VERSION ""

NS_ :

BS_:

BU_: AHCP APM BPCM EAC EBCM ECM ESC HCP OBCM ORC RHSC2

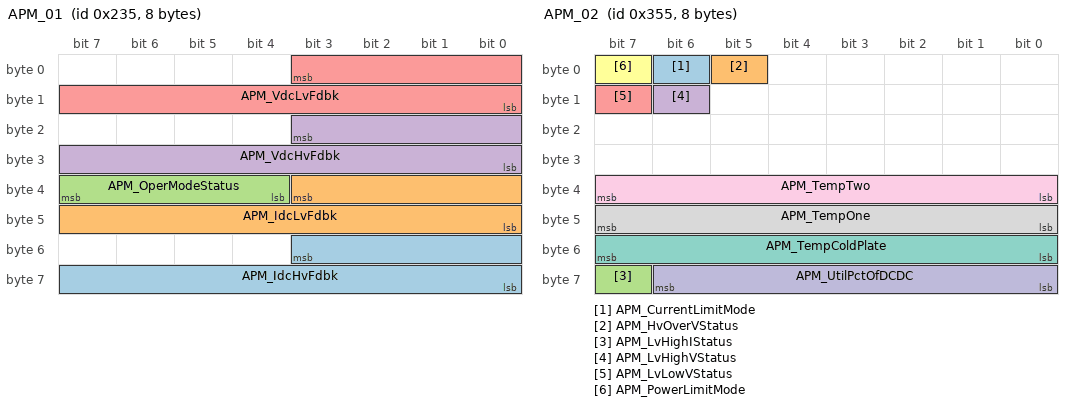
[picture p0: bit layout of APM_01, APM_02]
BO_ 565 APM_01: 8 APM
 SG_ APM_IdcHvFdbk : 51|12@0+ (0.1,-149) [-149|150] "Amp"  HCP
 SG_ APM_IdcLvFdbk : 35|12@0+ (0.15,-299) [-299|299.5] "Amp"  HCP
 SG_ APM_OperModeStatus : 36|4@1+ (1,0) [0|0] ""  HCP
 SG_ APM_VdcHvFdbk : 19|12@0+ (0.125,0) [0|510] "V"  HCP
 SG_ APM_VdcLvFdbk : 3|12@0+ (0.005,0) [0|19.9999] "V"  HCP

BO_ 853 APM_02: 8 APM
 SG_ APM_CurrentLimitMode : 6|1@1+ (1,0) [0|0] ""  HCP
 SG_ APM_HvOverVStatus : 5|1@1+ (1,0) [0|0] ""  HCP
 SG_ APM_LvHighIStatus : 63|1@1+ (1,0) [0|0] ""  HCP
 SG_ APM_LvHighVStatus : 14|1@1+ (1,0) [0|0] ""  HCP
 SG_ APM_LvLowVStatus : 15|1@1+ (1,0) [0|0] ""  HCP
 SG_ APM_PowerLimitMode : 7|1@1+ (1,0) [0|0] ""  HCP
 SG_ APM_TempColdPlate : 48|8@1+ (1,-40) [-40|213] "°C"  HCP
 SG_ APM_TempOne : 40|8@1+ (1,-40) [-40|213] "°C"  HCP
 SG_ APM_TempTwo : 32|8@1+ (1,-40) [-40|213] "°C"  HCP
 SG_ APM_UtilPctOfDCDC : 56|7@1+ (1,0) [0|126] "%"  HCP

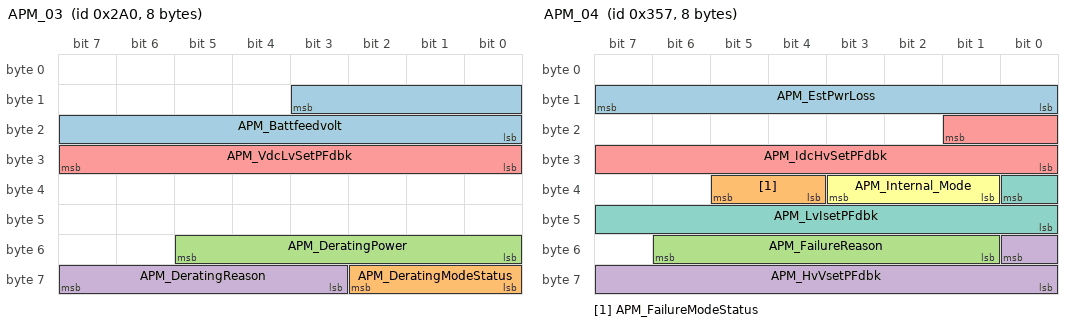
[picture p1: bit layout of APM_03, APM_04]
BO_ 672 APM_03: 8 APM
 SG_ APM_Battfeedvolt : 11|12@0+ (0.0097703,0) [0|40] "V"  HCP
 SG_ APM_DeratingModeStatus : 56|3@1+ (1,0) [0|0] ""  HCP
 SG_ APM_DeratingPower : 48|6@1+ (50,0) [0|3100] "W"  HCP
 SG_ APM_DeratingReason : 59|5@1+ (1,0) [0|0] ""  HCP
 SG_ APM_VdcLvSetPFdbk : 24|8@1+ (0.0625,0) [0|15.875] "V"  HCP

BO_ 855 APM_04: 8 APM
 SG_ APM_EstPwrLoss : 8|8@1+ (2,0) [0|504] "W"  HCP
 SG_ APM_FailureModeStatus : 36|2@1+ (1,0) [0|0] ""  HCP
 SG_ APM_FailureReason : 49|6@1+ (1,0) [0|0] ""  HCP
 SG_ APM_HvVsetPFdbk : 48|9@0+ (1,0) [0|510] "V"  HCP
 SG_ APM_IdcHvSetPFdbk : 17|10@0+ (0.2,-100) [-100|104.4] "Amp"  HCP
 SG_ APM_Internal_Mode : 33|3@1+ (1,0) [0|0] ""  HCP
 SG_ APM_LvIsetPFdbk : 32|9@0+ (1,-255) [-255|255] "Amp"  HCP

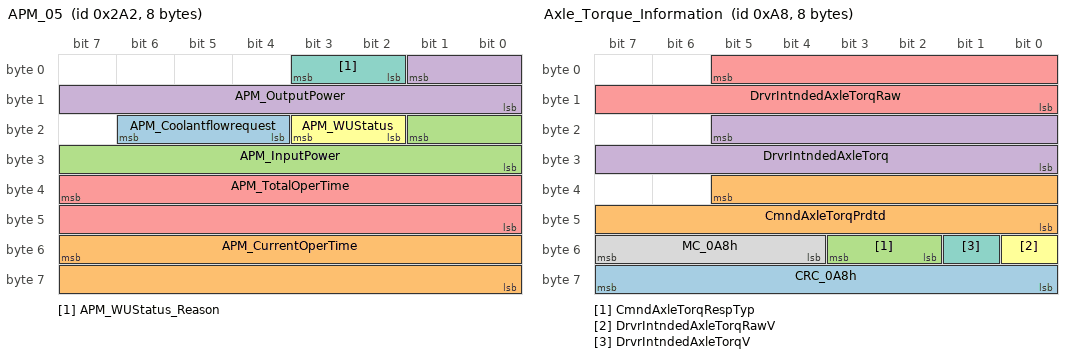
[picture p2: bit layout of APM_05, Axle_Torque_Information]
BO_ 674 APM_05: 8 APM
 SG_ APM_Coolantflowrequest : 20|3@1+ (1,0) [0|7] ""  HCP
 SG_ APM_CurrentOperTime : 55|16@0+ (1,0) [0|65534] "sec"  HCP
 SG_ APM_InputPower : 17|10@0+ (3,0) [0|3066] "W"  HCP
 SG_ APM_OutputPower : 1|10@0+ (3,0) [0|3066] "W"  HCP
 SG_ APM_TotalOperTime : 39|16@0+ (1,0) [0|65534] "Hours"  HCP
 SG_ APM_WUStatus : 18|2@1+ (1,0) [0|0] ""  HCP
 SG_ APM_WUStatus_Reason : 2|2@1+ (1,0) [0|0] ""  HCP

BO_ 168 Axle_Torque_Information: 8 ECM
 SG_ CRC_0A8h : 56|8@1+ (1,0) [0|0] ""  HCP
 SG_ CmndAxleTorqPrdtd : 37|14@0+ (1.5625,-4604.688) [-4604.688|20970.3125] "Nm"  HCP
 SG_ CmndAxleTorqRespTyp : 50|2@1+ (1,0) [0|0] ""  HCP
 SG_ DrvrIntndedAxleTorq : 21|14@0+ (1.5625,-4604.688) [-4604.688|20970.3125] "Nm"  HCP
 SG_ DrvrIntndedAxleTorqRaw : 5|14@0+ (1.5625,-4604.688) [-4604.688|20970.3125] "Nm"  HCP
 SG_ DrvrIntndedAxleTorqRawV : 48|1@1+ (1,0) [0|0] ""  HCP
 SG_ DrvrIntndedAxleTorqV : 49|1@1+ (1,0) [0|0] ""  HCP
 SG_ MC_0A8h : 52|4@1+ (1,0) [0|15] ""  HCP

BO_ 708 BPCM_HV_CellBalancing: 8 BPCM
 SG_ HVBatBalComplete : 56|1@1+ (1,0) [0|0] ""  HCP
 SG_ HVBatBalMd : 58|1@1+ (1,0) [0|0] ""  HCP

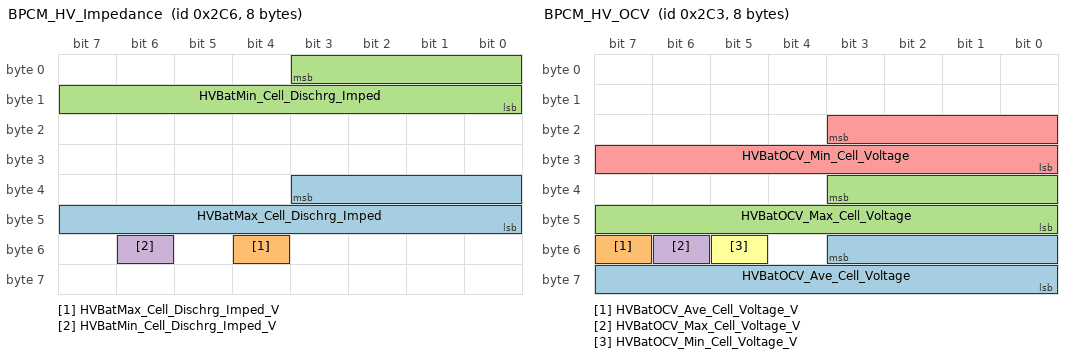
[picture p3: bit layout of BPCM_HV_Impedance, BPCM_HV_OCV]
BO_ 710 BPCM_HV_Impedance: 8 BPCM
 SG_ HVBatMax_Cell_Dischrg_Imped : 35|12@0+ (0.01,0) [0|40.9] "Ohms"  HCP
 SG_ HVBatMax_Cell_Dischrg_Imped_V : 52|1@1+ (1,0) [0|0] ""  HCP
 SG_ HVBatMin_Cell_Dischrg_Imped : 3|12@0+ (0.01,0) [0|40.9] "Ohms"  HCP
 SG_ HVBatMin_Cell_Dischrg_Imped_V : 54|1@1+ (1,0) [0|0] ""  HCP

BO_ 707 BPCM_HV_OCV: 8 BPCM
 SG_ HVBatOCV_Ave_Cell_Voltage : 51|12@0+ (0.001,1.5) [1.5|4.5] "Volts"  HCP
 SG_ HVBatOCV_Ave_Cell_Voltage_V : 55|1@1+ (1,0) [0|0] ""  HCP
 SG_ HVBatOCV_Max_Cell_Voltage : 35|12@0+ (0.001,1.5) [1.5|4.5] "Volts"  HCP
 SG_ HVBatOCV_Max_Cell_Voltage_V : 54|1@1+ (1,0) [0|0] ""  HCP
 SG_ HVBatOCV_Min_Cell_Voltage : 19|12@0+ (0.001,1.5) [1.5|4.5] "Volts"  HCP
 SG_ HVBatOCV_Min_Cell_Voltage_V : 53|1@1+ (1,0) [0|0] ""  HCP

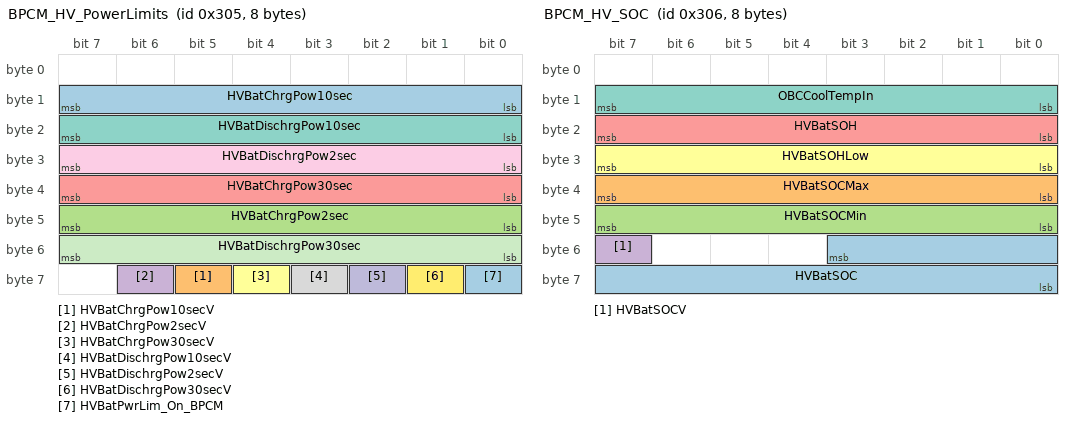
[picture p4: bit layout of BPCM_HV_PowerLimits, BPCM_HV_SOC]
BO_ 773 BPCM_HV_PowerLimits: 8 BPCM
 SG_ HVBatChrgPow10sec : 8|8@1+ (0.5,0) [0|125] "kW"  ECM,HCP
 SG_ HVBatChrgPow10secV : 61|1@1+ (1,0) [0|0] ""  ECM,HCP
 SG_ HVBatChrgPow2sec : 40|8@1+ (0.5,0) [0|125] "kW"  ECM,HCP
 SG_ HVBatChrgPow2secV : 62|1@1+ (1,0) [0|0] ""  ECM,HCP
 SG_ HVBatChrgPow30sec : 32|8@1+ (0.5,0) [0|125] "kW"  ECM,HCP
 SG_ HVBatChrgPow30secV : 60|1@1+ (1,0) [0|0] ""  ECM,HCP
 SG_ HVBatDischrgPow10sec : 16|8@1+ (0.5,0) [0|125] "kW"  HCP
 SG_ HVBatDischrgPow10secV : 59|1@1+ (1,0) [0|0] ""  HCP
 SG_ HVBatDischrgPow2sec : 24|8@1+ (0.5,0) [0|125] "kW"  HCP
 SG_ HVBatDischrgPow2secV : 58|1@1+ (1,0) [0|0] ""  HCP
 SG_ HVBatDischrgPow30sec : 48|8@1+ (0.5,0) [0|125] "kW"  HCP
 SG_ HVBatDischrgPow30secV : 57|1@1+ (1,0) [0|0] ""  HCP
 SG_ HVBatPwrLim_On_BPCM : 56|1@1+ (1,0) [0|0] ""  HCP

BO_ 774 BPCM_HV_SOC: 8 BPCM
 SG_ HVBatSOC : 51|12@0+ (0.02442,0) [0|100] "%"  EBCM,ESC,HCP
 SG_ HVBatSOCMax : 32|8@1+ (0.392157,0) [0|100] "%"  HCP
 SG_ HVBatSOCMin : 40|8@1+ (0.392157,0) [0|100] "%"  HCP
 SG_ HVBatSOCV : 55|1@1+ (1,0) [0|0] ""  HCP
 SG_ HVBatSOH : 16|8@1+ (0.2,50) [50|100] "%"  HCP
 SG_ HVBatSOHLow : 24|8@1+ (0.2,50) [50|100] "%"  HCP
 SG_ OBCCoolTempIn : 8|8@1+ (1,-40) [-40|214] "°C"  HCP

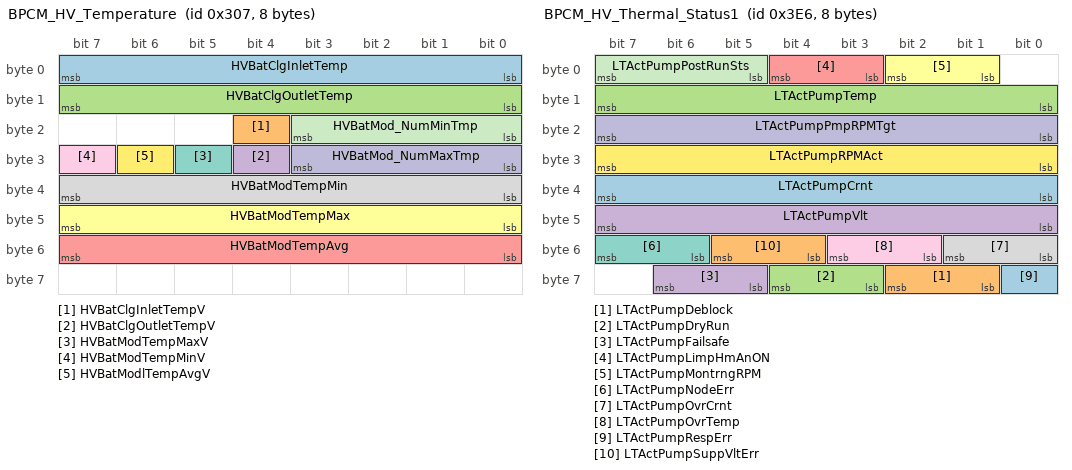
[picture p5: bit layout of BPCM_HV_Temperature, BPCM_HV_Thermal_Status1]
BO_ 775 BPCM_HV_Temperature: 8 BPCM
 SG_ HVBatClgInletTemp : 0|8@1+ (1,-40) [-40|214] "°C"  ECM,HCP
 SG_ HVBatClgInletTempV : 20|1@1+ (1,0) [0|0] ""  ECM,HCP
 SG_ HVBatClgOutletTemp : 8|8@1+ (1,-40) [-40|214] "°C"  ECM,HCP
 SG_ HVBatClgOutletTempV : 28|1@1+ (1,0) [0|0] ""  ECM,HCP
 SG_ HVBatModTempAvg : 48|8@1+ (1,-40) [-40|214] "°C"  HCP
 SG_ HVBatModTempMax : 40|8@1+ (1,-40) [-40|214] "°C"  HCP,RHSC2
 SG_ HVBatModTempMaxV : 29|1@1+ (1,0) [0|0] ""  HCP,RHSC2
 SG_ HVBatModTempMin : 32|8@1+ (1,-40) [-40|214] "°C"  HCP,RHSC2
 SG_ HVBatModTempMinV : 31|1@1+ (1,0) [0|0] ""  HCP,RHSC2
 SG_ HVBatMod_NumMaxTmp : 24|4@1+ (1,0) [0|15] ""  HCP
 SG_ HVBatMod_NumMinTmp : 16|4@1+ (1,0) [0|15] ""  HCP
 SG_ HVBatModlTempAvgV : 30|1@1+ (1,0) [0|0] ""  HCP

BO_ 998 BPCM_HV_Thermal_Status1: 8 BPCM
 SG_ LTActPumpCrnt : 32|8@1+ (0.2,0) [0|50.8] "Amp"  HCP
 SG_ LTActPumpDeblock : 57|2@1+ (1,0) [0|0] ""  HCP
 SG_ LTActPumpDryRun : 59|2@1+ (1,0) [0|0] ""  HCP
 SG_ LTActPumpFailsafe : 61|2@1+ (1,0) [0|0] ""  HCP
 SG_ LTActPumpLimpHmAnON : 3|2@1+ (1,0) [0|0] ""  HCP
 SG_ LTActPumpMontrngRPM : 1|2@1+ (1,0) [0|0] ""  ECM,HCP
 SG_ LTActPumpNodeErr : 54|2@1+ (1,0) [0|0] ""  HCP
 SG_ LTActPumpOvrCrnt : 48|2@1+ (1,0) [0|0] ""  HCP
 SG_ LTActPumpOvrTemp : 50|2@1+ (1,0) [0|0] ""  HCP
 SG_ LTActPumpPmpRPMTgt : 16|8@1+ (28,0) [0|7000] "rpm"  HCP
 SG_ LTActPumpPostRunSts : 5|3@1+ (1,0) [0|0] ""  HCP
 SG_ LTActPumpRPMAct : 24|8@1+ (28,0) [0|7000] "rpm"  ECM,HCP
 SG_ LTActPumpRespErr : 56|1@1+ (1,0) [0|0] ""  HCP
 SG_ LTActPumpSuppVltErr : 52|2@1+ (1,0) [0|0] ""  HCP
 SG_ LTActPumpTemp : 8|8@1+ (1,-50) [-50|204] "°C"  HCP
 SG_ LTActPumpVlt : 40|8@1+ (0.12,0) [0|30] "Volts"  HCP

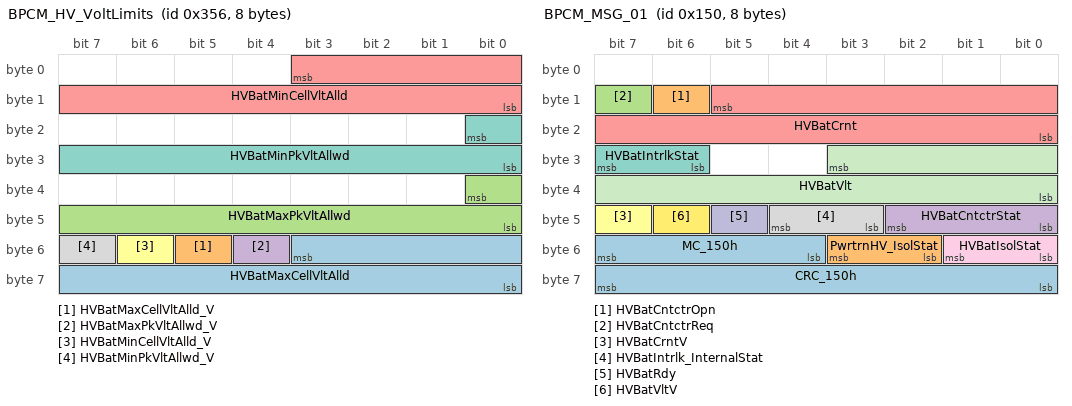
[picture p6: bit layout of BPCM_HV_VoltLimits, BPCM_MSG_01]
BO_ 854 BPCM_HV_VoltLimits: 8 BPCM
 SG_ HVBatMaxCellVltAlld : 51|12@0+ (0.001,1.5) [1.5|4.5] "Volts"  HCP
 SG_ HVBatMaxCellVltAlld_V : 53|1@1+ (1,0) [0|0] ""  HCP
 SG_ HVBatMaxPkVltAllwd : 32|9@0+ (1,175) [175|440] "V"  HCP
 SG_ HVBatMaxPkVltAllwd_V : 52|1@1+ (1,0) [0|0] ""  HCP
 SG_ HVBatMinCellVltAlld : 3|12@0+ (0.001,1.5) [1.5|4.5] "Volts"  HCP
 SG_ HVBatMinCellVltAlld_V : 54|1@1+ (1,0) [0|0] ""  HCP
 SG_ HVBatMinPkVltAllwd : 16|9@0+ (1,175) [175|440] "V"  HCP
 SG_ HVBatMinPkVltAllwd_V : 55|1@1+ (1,0) [0|0] ""  HCP

BO_ 336 BPCM_MSG_01: 8 BPCM
 SG_ CRC_150h : 56|8@1+ (1,0) [0|255] ""  HCP,OBCM
 SG_ HVBatCntctrOpn : 14|1@1+ (1,0) [0|0] ""  APM,HCP,OBCM
 SG_ HVBatCntctrReq : 15|1@1+ (1,0) [0|0] ""  HCP
 SG_ HVBatCntctrStat : 40|3@1+ (1,0) [0|0] ""  APM,HCP,OBCM,ORC
 SG_ HVBatCrnt : 13|14@0+ (0.1,-512.1) [-512|512] "Amp"  HCP
 SG_ HVBatCrntV : 47|1@1+ (1,0) [0|0] ""  HCP
 SG_ HVBatIntrlkStat : 30|2@1+ (1,0) [0|0] ""  HCP
 SG_ HVBatIntrlk_InternalStat : 43|2@1+ (1,0) [0|0] ""  HCP
 SG_ HVBatIsolStat : 48|2@1+ (1,0) [0|0] ""  HCP
 SG_ HVBatRdy : 45|1@1+ (1,0) [0|0] ""  HCP
 SG_ HVBatVlt : 27|12@0+ (0.1,180) [180|511] "Volts"  APM,HCP
 SG_ HVBatVltV : 46|1@1+ (1,0) [0|0] ""  APM,HCP
 SG_ MC_150h : 52|4@1+ (1,0) [0|15] ""  HCP,OBCM
 SG_ PwrtrnHV_IsolStat : 50|2@1+ (1,0) [0|0] ""  HCP

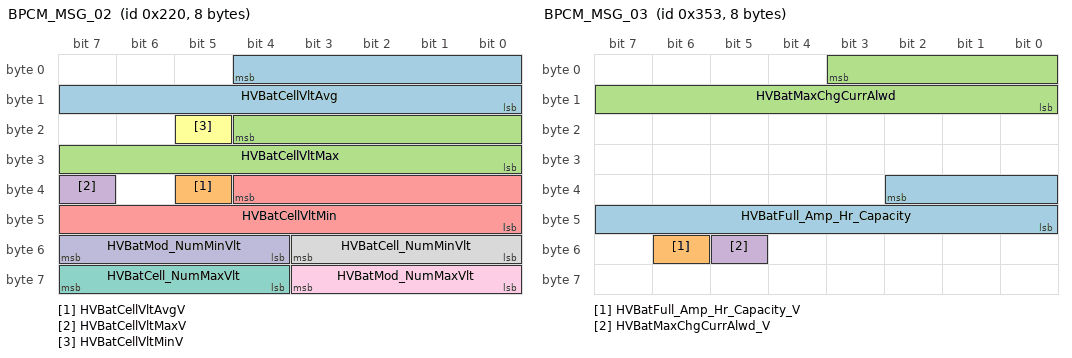
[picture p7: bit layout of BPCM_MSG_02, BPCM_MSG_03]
BO_ 544 BPCM_MSG_02: 8 BPCM
 SG_ HVBatCellVltAvg : 4|13@0+ (0.001,0) [0|5] "Volts"  HCP
 SG_ HVBatCellVltAvgV : 37|1@1+ (1,0) [0|0] ""  HCP
 SG_ HVBatCellVltMax : 20|13@0+ (0.001,0) [0|5] "Volts"  HCP
 SG_ HVBatCellVltMaxV : 39|1@1+ (1,0) [0|0] ""  HCP
 SG_ HVBatCellVltMin : 36|13@0+ (0.001,0) [0|5] "Volts"  HCP
 SG_ HVBatCellVltMinV : 21|1@1+ (1,0) [0|0] ""  HCP
 SG_ HVBatCell_NumMaxVlt : 60|4@1+ (1,0) [0|15] "Volts"  HCP
 SG_ HVBatCell_NumMinVlt : 48|4@1+ (1,0) [0|15] "Volts"  HCP
 SG_ HVBatMod_NumMaxVlt : 56|4@1+ (1,0) [0|15] ""  HCP
 SG_ HVBatMod_NumMinVlt : 52|4@1+ (1,0) [0|15] ""  HCP

BO_ 851 BPCM_MSG_03: 8 BPCM
 SG_ HVBatFull_Amp_Hr_Capacity : 34|11@0+ (0.1,0) [0|200] "Ah"  HCP
 SG_ HVBatFull_Amp_Hr_Capacity_V : 54|1@1+ (1,0) [0|0] ""  HCP
 SG_ HVBatMaxChgCurrAlwd : 3|12@0+ (0.1,0) [0|256] "A"  HCP
 SG_ HVBatMaxChgCurrAlwd_V : 53|1@1+ (1,0) [0|0] ""  HCP

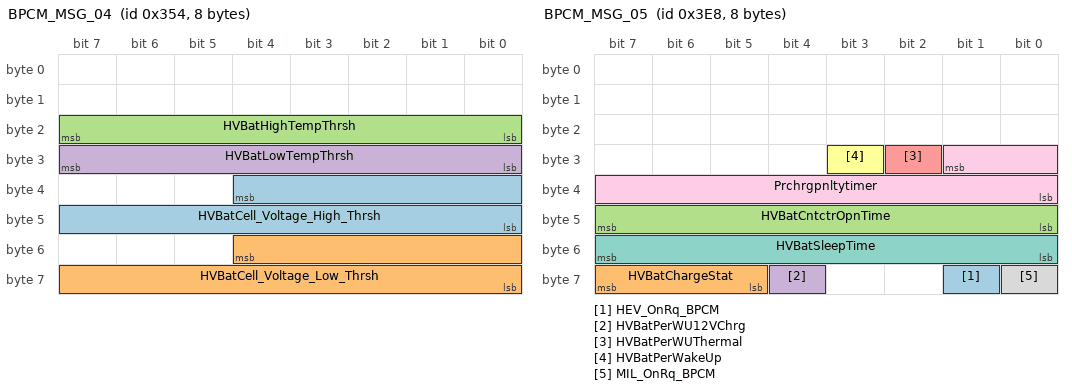
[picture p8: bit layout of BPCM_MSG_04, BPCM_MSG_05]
BO_ 852 BPCM_MSG_04: 8 BPCM
 SG_ HVBatCell_Voltage_High_Thrsh : 36|13@0+ (0.001,0) [0|5] "Volts"  HCP
 SG_ HVBatCell_Voltage_Low_Thrsh : 52|13@0+ (0.001,0) [0|5] "Volts"  HCP
 SG_ HVBatHighTempThrsh : 16|8@1+ (1,-40) [-40|214] "°C"  HCP,RHSC2
 SG_ HVBatLowTempThrsh : 24|8@1+ (1,-40) [-40|214] "°C"  HCP,RHSC2

BO_ 1000 BPCM_MSG_05: 8 BPCM
 SG_ HEV_OnRq_BPCM : 57|1@1+ (1,0) [0|0] ""  HCP
 SG_ HVBatChargeStat : 61|3@1+ (1,0) [0|0] ""  HCP
 SG_ HVBatCntctrOpnTime : 40|8@1+ (0.2,0) [0|48] "Hours"  HCP
 SG_ HVBatPerWU12VChrg : 60|1@1+ (1,0) [0|0] ""  HCP
 SG_ HVBatPerWUThermal : 26|1@1+ (1,0) [0|0] ""  HCP
 SG_ HVBatPerWakeUp : 27|1@1+ (1,0) [0|0] ""  HCP
 SG_ HVBatSleepTime : 48|8@1+ (0.2,0) [0|48] "Days"  HCP
 SG_ MIL_OnRq_BPCM : 56|1@1+ (1,0) [0|0] ""  ECM
 SG_ Prchrgpnltytimer : 25|10@0+ (2,0) [2|1800] "sec"  HCP

BO_ 337 BPCM_PHEV_2: 8 BPCM
 SG_ HVBat_Real_Time_Clock : 7|32@0+ (1,0) [0|4294967294] "sec"  ECM,HCP
 SG_ HVBat_Real_Time_Clock_V : 39|1@1+ (1,0) [0|0] ""  ECM,HCP

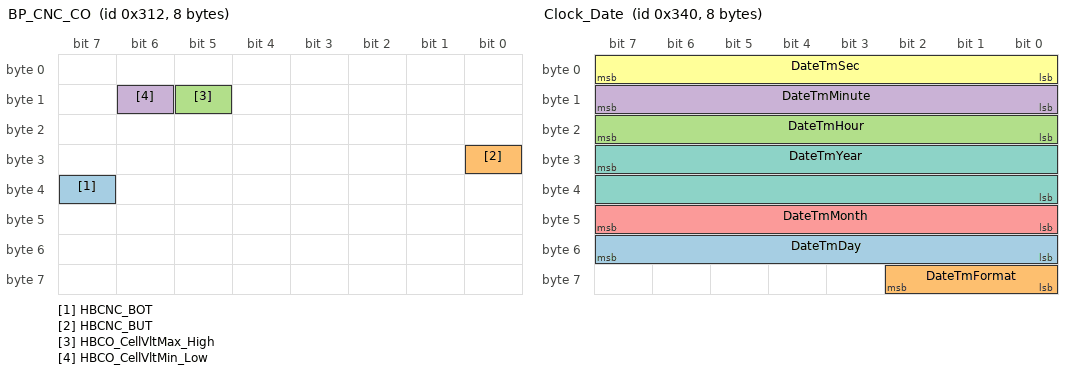
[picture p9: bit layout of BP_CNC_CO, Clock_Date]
BO_ 786 BP_CNC_CO: 8 BPCM
 SG_ HBCNC_BOT : 39|1@1+ (1,0) [0|0] ""  HCP
 SG_ HBCNC_BUT : 24|1@1+ (1,0) [0|0] ""  HCP
 SG_ HBCO_CellVltMax_High : 13|1@1+ (1,0) [0|0] ""  HCP
 SG_ HBCO_CellVltMin_Low : 14|1@1+ (1,0) [0|0] ""  HCP

BO_ 832 Clock_Date: 8 HCP
 SG_ DateTmDay : 48|8@1+ (1,0) [1|31] "Days"  BPCM
 SG_ DateTmFormat : 56|3@1+ (1,0) [0|0] ""  BPCM
 SG_ DateTmHour : 16|8@1+ (1,0) [0|23] "Hours"  BPCM
 SG_ DateTmMinute : 8|8@1+ (1,0) [0|59] "min"  BPCM
 SG_ DateTmMonth : 40|8@1+ (1,0) [1|12] "Months"  BPCM
 SG_ DateTmSec : 0|8@1+ (1,0) [0|59] "sec"  BPCM
 SG_ DateTmYear : 31|16@0+ (1,0) [0|65534] "Years"  BPCM

BO_ 500 DAS_A3: 8 RHSC2
 SG_ CRC_DAS_A3 : 56|8@1+ (1,0) [0|0] "" Vector__XXX
 SG_ MC_DAS_A3 : 52|4@1+ (1,0) [0|15] "" Vector__XXX

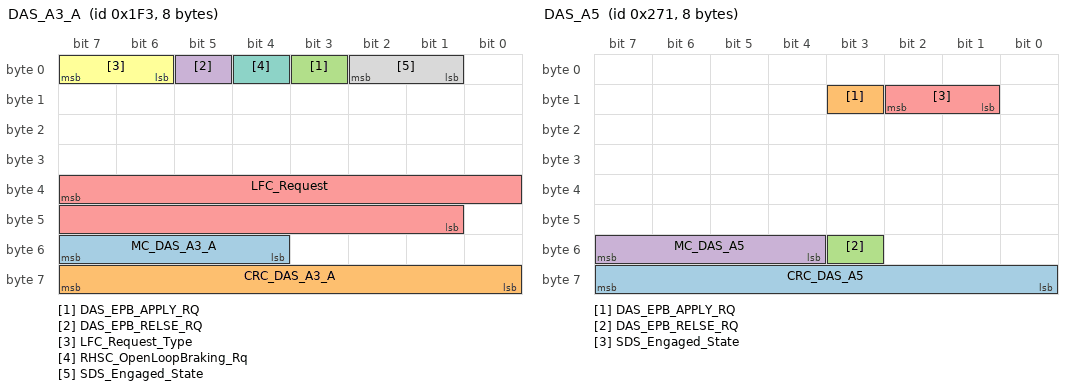
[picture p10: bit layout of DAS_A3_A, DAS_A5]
BO_ 499 DAS_A3_A: 8 RHSC2
 SG_ MC_DAS_A3_A : 52|4@1+ (1,0) [0|15] ""  EBCM,ESC
 SG_ CRC_DAS_A3_A : 56|8@1+ (1,0) [0|255] ""  EBCM,ESC
 SG_ DAS_EPB_APPLY_RQ : 3|1@1+ (1,0) [0|0] "" Vector__XXX
 SG_ DAS_EPB_RELSE_RQ : 5|1@1+ (1,0) [0|0] "" Vector__XXX
 SG_ LFC_Request : 39|15@0+ (2,-65534) [-65534|0] ""  EBCM,ESC
 SG_ LFC_Request_Type : 6|2@1+ (1,0) [0|0] ""  EBCM,ESC
 SG_ RHSC_OpenLoopBraking_Rq : 4|1@1+ (1,0) [0|0] ""  EBCM,ESC
 SG_ SDS_Engaged_State : 1|2@1+ (1,0) [0|0] ""  EBCM,ESC

BO_ 625 DAS_A5: 8 RHSC2
 SG_ CRC_DAS_A5 : 56|8@1+ (1,0) [0|255] "" Vector__XXX
 SG_ DAS_EPB_APPLY_RQ : 11|1@1+ (1,0) [0|0] "" Vector__XXX
 SG_ DAS_EPB_RELSE_RQ : 51|1@1+ (1,0) [0|0] "" Vector__XXX
 SG_ MC_DAS_A5 : 52|4@1+ (1,0) [0|15] "" Vector__XXX
 SG_ SDS_Engaged_State : 9|2@1+ (1,0) [0|0] "" Vector__XXX

BO_ 2015 DG_RQ_GLOBAL: 8 HCP
 SG_ DG_RQ_GLOBAL : 7|64@0+ (1,0) [0|0] ""  BPCM

BO_ 1089 DG_RQ_GLOBAL_UDS: 8 HCP
 SG_ DG_RQ_GLOBAL_UDS : 7|64@0+ (1,0) [0|0] ""  AHCP,APM,BPCM,EAC,OBCM

BO_ 1900 D_RQ_AHCP: 8 HCP
 SG_ D_RQ_AHCP : 7|64@0+ (1,0) [0|0] ""  AHCP

BO_ 1898 D_RQ_APM: 8 HCP
 SG_ D_RQ_APM : 7|64@0+ (1,0) [0|0] ""  APM

BO_ 2023 D_RQ_BPCM: 8 HCP
 SG_ D_RQ_BPCM : 7|64@0+ (1,0) [0|0] ""  BPCM

BO_ 1899 D_RQ_EAC: 8 HCP
 SG_ D_RQ_EAC : 7|64@0+ (1,0) [0|0] ""  EAC

BO_ 1902 D_RQ_OBCM: 8 HCP
 SG_ D_RQ_OBCM : 7|64@0+ (1,0) [0|0] ""  OBCM

BO_ 1260 D_RS_AHCP: 8 AHCP
 SG_ D_RS_AHCP : 7|64@0+ (1,0) [0|0] ""  HCP

BO_ 1258 D_RS_APM: 8 APM
 SG_ D_RS_APM : 7|64@0+ (1,0) [0|0] ""  HCP

BO_ 2031 D_RS_BPCM: 8 BPCM
 SG_ D_RS_BPCM : 7|64@0+ (1,0) [0|0] ""  HCP

BO_ 1259 D_RS_EAC: 8 EAC
 SG_ D_RS_EAC : 7|64@0+ (1,0) [0|0] ""  HCP

BO_ 1262 D_RS_OBCM: 8 OBCM
 SG_ D_RS_OBCM : 7|64@0+ (1,0) [0|0] ""  HCP

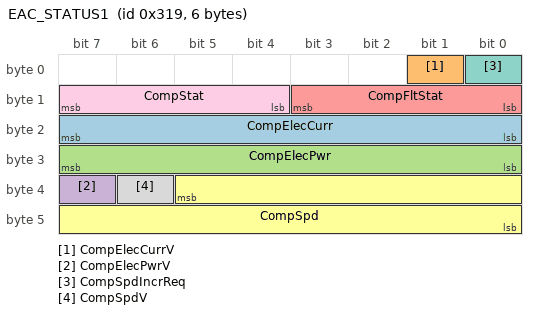
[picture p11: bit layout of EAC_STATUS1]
BO_ 793 EAC_STATUS1: 6 EAC
 SG_ CompElecCurr : 16|8@1+ (0.2,0) [0|51] "Amp"  HCP
 SG_ CompElecCurrV : 1|1@1+ (1,0) [0|0] ""  HCP
 SG_ CompElecPwr : 24|8@1+ (0.04,0) [0|10.2] "kW"  HCP
 SG_ CompElecPwrV : 39|1@1+ (1,0) [0|0] ""  HCP
 SG_ CompFltStat : 8|4@1+ (1,0) [0|0] ""  HCP
 SG_ CompSpd : 37|14@0+ (1,0) [0|16382] "rpm"  HCP
 SG_ CompSpdIncrReq : 0|1@1+ (1,0) [0|0] ""  HCP
 SG_ CompSpdV : 38|1@1+ (1,0) [0|0] ""  HCP
 SG_ CompStat : 12|4@1+ (1,0) [0|0] ""  HCP

CM_ "Excel Convert to DBC - Written by Vector CANtech, Inc. 2016";
CM_ SG_ 565 APM_IdcHvFdbk "High side current feedback";
CM_ SG_ 565 APM_IdcLvFdbk "Low side current feedback";
CM_ SG_ 565 APM_OperModeStatus "APM Operation  mode  Status";
CM_ SG_ 565 APM_VdcHvFdbk "High side  voltage feedback";
CM_ SG_ 565 APM_VdcLvFdbk "Low side voltage feedback";
CM_ SG_ 853 APM_CurrentLimitMode "Derating becasuse of too high current at HV";
CM_ SG_ 853 APM_HvOverVStatus "over voltage at HV";
CM_ SG_ 853 APM_LvHighIStatus "High current at LV side";
CM_ SG_ 853 APM_LvHighVStatus "High voltage at LV side";
CM_ SG_ 853 APM_LvLowVStatus "Low voltage at LV side";
CM_ SG_ 853 APM_PowerLimitMode "Low voltage at HV side";
CM_ SG_ 853 APM_TempColdPlate "Cold Plate Temperature";
CM_ SG_ 853 APM_TempOne "Direct Bonded Copper temperature";
CM_ SG_ 853 APM_TempTwo "Printed Circuit Board Temperature";
CM_ SG_ 853 APM_UtilPctOfDCDC "Utilization of DCDC output power capability";
CM_ SG_ 672 APM_Battfeedvolt "Battery feed voltage";
CM_ SG_ 672 APM_DeratingModeStatus "APM Derating status during operation";
CM_ SG_ 672 APM_DeratingPower "Available power during derating mode";
CM_ SG_ 672 APM_DeratingReason "APM Derating";
CM_ SG_ 672 APM_VdcLvSetPFdbk "setpoint of low voltage";
CM_ SG_ 855 APM_EstPwrLoss "Estimated Power Loss";
CM_ SG_ 855 APM_FailureModeStatus "APM Failure mode status";
CM_ SG_ 855 APM_FailureReason "FailureReason";
CM_ SG_ 855 APM_HvVsetPFdbk "APM HV  Voltage set point feedback";
CM_ SG_ 855 APM_IdcHvSetPFdbk "Feedback of set point high voltage current";
CM_ SG_ 855 APM_Internal_Mode "APM internal mode status";
CM_ SG_ 855 APM_LvIsetPFdbk "APM LV  Current set point feedback";
CM_ SG_ 674 APM_Coolantflowrequest "APM coolant flow required rate";
CM_ SG_ 674 APM_CurrentOperTime "APM current cycle time";
CM_ SG_ 674 APM_InputPower "APM input power";
CM_ SG_ 674 APM_OutputPower "APM output power";
CM_ SG_ 674 APM_TotalOperTime "APM total operating time in hours";
CM_ SG_ 674 APM_WUStatus "APM Wake up status";
CM_ SG_ 674 APM_WUStatus_Reason "APM Wake reason";
CM_ SG_ 168 CRC_0A8h "CRC-Checksum Byte 1 - 7 according to SAE J1850";
CM_ SG_ 168 CmndAxleTorqPrdtd "Commanded Axle Torque: Predicted Torque";
CM_ SG_ 168 CmndAxleTorqRespTyp "Commanded Axle Torque Response Type";
CM_ SG_ 168 DrvrIntndedAxleTorq "Driver Intended Axle Torque";
CM_ SG_ 168 DrvrIntndedAxleTorqRaw "Driver Intended Axle Torque Raw";
CM_ SG_ 168 DrvrIntndedAxleTorqRawV "Driver Intended Axle Torque Raw Validity; Invalid = [1]";
CM_ SG_ 168 DrvrIntndedAxleTorqV "Driver Intended Axle Torque Validity; Invalid = [1]";
CM_ SG_ 168 MC_0A8h "Message counter   0A8h";
CM_ SG_ 708 HVBatBalComplete "Battery Balance complete...";
CM_ SG_ 708 HVBatBalMd "Balance mode in progress";
CM_ SG_ 710 HVBatMax_Cell_Dischrg_Imped "Maximum Cell disCharge Impedance";
CM_ SG_ 710 HVBatMax_Cell_Dischrg_Imped_V "Maximum cell discharge impedance valid; Invalid = [1]";
CM_ SG_ 710 HVBatMin_Cell_Dischrg_Imped "Minimum cell discharge impedance";
CM_ SG_ 710 HVBatMin_Cell_Dischrg_Imped_V "Minimum cell discharge impedance validity; Invalid = [1]";
CM_ SG_ 707 HVBatOCV_Ave_Cell_Voltage "Cell Open Circuit Voltage Average";
CM_ SG_ 707 HVBatOCV_Ave_Cell_Voltage_V "Cell open circuit voltage average validity; Invalid = [1]";
CM_ SG_ 707 HVBatOCV_Max_Cell_Voltage "Cell Open Circuit Voltage Maximum";
CM_ SG_ 707 HVBatOCV_Max_Cell_Voltage_V "Cell open circuit voltage maximum validity; Invalid = [1]";
CM_ SG_ 707 HVBatOCV_Min_Cell_Voltage "Cell Open Circuit Voltage Minimum";
CM_ SG_ 707 HVBatOCV_Min_Cell_Voltage_V "Cell open circuit voltage minimum validity; Invalid = [1]";
CM_ SG_ 773 HVBatChrgPow10sec "Eunjoo ??";
CM_ SG_ 773 HVBatChrgPow10secV "High voltage battery charge power 10 seconds validity; Invalid = [1]";
CM_ SG_ 773 HVBatChrgPow2sec "High Voltage Battery Charge Power 2 seconds";
CM_ SG_ 773 HVBatChrgPow2secV "High voltage battery charge power 2 seconds validity; Invalid = [1]";
CM_ SG_ 773 HVBatChrgPow30sec "High Voltage Battery Charge Power 30 seconds";
CM_ SG_ 773 HVBatChrgPow30secV "High voltage battery charge power 30 seconds validity; Invalid = [1]";
CM_ SG_ 773 HVBatDischrgPow10sec "High Voltage Battery Discharge Power 10 seconds";
CM_ SG_ 773 HVBatDischrgPow10secV "High voltage battery discharge power 10 seconds validity; Invalid = [1]";
CM_ SG_ 773 HVBatDischrgPow2sec "High Voltage Battery DisCharge Power 2 seconds";
CM_ SG_ 773 HVBatDischrgPow2secV "High voltage battery discharge power 2 seconds validity; Invalid = [1]";
CM_ SG_ 773 HVBatDischrgPow30sec "High Voltage Battery DisCharge Power 30 seconds";
CM_ SG_ 773 HVBatDischrgPow30secV "High voltage battery discharge power 30 seconds validity; Invalid = [1]";
CM_ SG_ 773 HVBatPwrLim_On_BPCM "Limp Home Mode Enabled";
CM_ SG_ 774 HVBatSOC "High voltage battery pack state of charge";
CM_ SG_ 774 HVBatSOCMax "Maximum HV battery cell state of charge";
CM_ SG_ 774 HVBatSOCMin "Minimum HV battery cell state of charge";
CM_ SG_ 774 HVBatSOCV "High voltage battery state of charge validity. 0-Valid, 1-Invalid.";
CM_ SG_ 774 HVBatSOH "HV Battery percentage of State of Health.  Last-Known value to be stored in EEPROM.";
CM_ SG_ 774 HVBatSOHLow "HV Battery percentage of State of Health Low";
CM_ SG_ 774 OBCCoolTempIn "Onboard Charger Coolant Inlet Temperature";
CM_ SG_ 775 HVBatClgInletTemp "High voltage pack outlet cooling temperature";
CM_ SG_ 775 HVBatClgInletTempV "High voltage pack outlet cooling temperature valid; Invalid = [1]";
CM_ SG_ 775 HVBatClgOutletTemp "High voltage pack outlet cooling temperature valid";
CM_ SG_ 775 HVBatClgOutletTempV "High voltage pack outlet cooling temperature valid; Invalid = [1]";
CM_ SG_ 775 HVBatModTempAvg "HV Battery pack average temperature";
CM_ SG_ 775 HVBatModTempMax "HV Battery pack Maximum temperature";
CM_ SG_ 775 HVBatModTempMaxV "HV battery pack maximum temperature validity; Invalid = [1]";
CM_ SG_ 775 HVBatModTempMin "HV Battery pack Minimum temperature";
CM_ SG_ 775 HVBatModTempMinV "HV battery pack minimum temperature validity; Invalid = [1]";
CM_ SG_ 775 HVBatMod_NumMaxTmp "Module number - maximum temperature";
CM_ SG_ 775 HVBatMod_NumMinTmp "Module number - minimum temperature";
CM_ SG_ 775 HVBatModlTempAvgV "HV battery pack average temperature validity; Invalid = [1]";
CM_ SG_ 998 LTActPumpCrnt "Low Temp Active Pump Current";
CM_ SG_ 998 LTActPumpDeblock "Low Temp Active Pump Deblocking";
CM_ SG_ 998 LTActPumpDryRun "Low Temp Active Pump Dry Run";
CM_ SG_ 998 LTActPumpFailsafe "Low Temp Active Pump Failsafe";
CM_ SG_ 998 LTActPumpLimpHmAnON "Low Temp Active Pump limp home analog signal is on";
CM_ SG_ 998 LTActPumpMontrngRPM "Low Temp Active Pump RPM monitoring active";
CM_ SG_ 998 LTActPumpNodeErr "Low Temp Active Pump Node Error";
CM_ SG_ 998 LTActPumpOvrCrnt "Low Temp Active Pump Overcurrent";
CM_ SG_ 998 LTActPumpOvrTemp "Low Temp Active Pump Overtemp";
CM_ SG_ 998 LTActPumpPmpRPMTgt "Low Temp Active Pump RPM Target";
CM_ SG_ 998 LTActPumpPostRunSts "Low Temp Active Pump Post run status";
CM_ SG_ 998 LTActPumpRPMAct "Low Temp Active Pump RPM Actual";
CM_ SG_ 998 LTActPumpRespErr "0x0 No Error, 0x1 Error in the response of of a message frame";
CM_ SG_ 998 LTActPumpSuppVltErr "specified range (7V > Vbat >20V)";
CM_ SG_ 998 LTActPumpTemp "Low Temp Active Pump temperature";
CM_ SG_ 998 LTActPumpVlt "Low Temp Active Pump Voltage";
CM_ SG_ 854 HVBatMaxCellVltAlld "Maximum cell voltage allowed";
CM_ SG_ 854 HVBatMaxCellVltAlld_V "Maximum cell voltage allowed valid; Invalid = [1]";
CM_ SG_ 854 HVBatMaxPkVltAllwd "Maximum pack voltage allowed";
CM_ SG_ 854 HVBatMaxPkVltAllwd_V "Maximum pack voltage allowed valid; Invalid = [1]";
CM_ SG_ 854 HVBatMinCellVltAlld "Minimum cell voltage allowed";
CM_ SG_ 854 HVBatMinCellVltAlld_V "Minimum cell voltage allowed valid; Invalid = [1]";
CM_ SG_ 854 HVBatMinPkVltAllwd "Minimum battery pack voltage allowed";
CM_ SG_ 854 HVBatMinPkVltAllwd_V "Minimum battery pack voltage allowed valid; Invalid = [1]";
CM_ SG_ 336 CRC_150h "CRC-Checksum Byte 1 - 7 according to SAE J1850";
CM_ SG_ 336 HVBatCntctrOpn "HV Battery Pack contactor Open";
CM_ SG_ 336 HVBatCntctrReq "HV Battery pack contactor request";
CM_ SG_ 336 HVBatCntctrStat "HV Battery pack contactor state";
CM_ SG_ 336 HVBatCrnt "High voltage Battery pack current...";
CM_ SG_ 336 HVBatCrntV "High voltage battery pack current valid; Invalid = [1]";
CM_ SG_ 336 HVBatIntrlkStat "High Voltage Battery interlock state";
CM_ SG_ 336 HVBatIntrlk_InternalStat "HVIL Status internal";
CM_ SG_ 336 HVBatIsolStat "High voltage battery pack Isolation state";
CM_ SG_ 336 HVBatRdy "High Voltage Battery Ready";
CM_ SG_ 336 HVBatVlt "High voltage battery pack voltage";
CM_ SG_ 336 HVBatVltV "High voltage battery pack voltage validity; Invalid = [1]";
CM_ SG_ 336 MC_150h "HV Battery pack contactor state message counter";
CM_ SG_ 336 PwrtrnHV_IsolStat "Powertrain High voltage Isolation state";
CM_ SG_ 544 HVBatCellVltAvg "Average cell voltage";
CM_ SG_ 544 HVBatCellVltAvgV "Average cell voltage valid; Invalid = [1]";
CM_ SG_ 544 HVBatCellVltMax "Max cell voltage";
CM_ SG_ 544 HVBatCellVltMaxV "Max cell voltage valid; Invalid = [1]";
CM_ SG_ 544 HVBatCellVltMin "Min cell voltage";
CM_ SG_ 544 HVBatCellVltMinV "Min cell voltage valid; Invalid = [1]";
CM_ SG_ 544 HVBatCell_NumMaxVlt "Cell number - maximum voltage";
CM_ SG_ 544 HVBatCell_NumMinVlt "Cell number - minimum voltage";
CM_ SG_ 544 HVBatMod_NumMaxVlt "Module number - maximum voltage; Enumeration  0 = Module 1 ...15 = Module 16.";
CM_ SG_ 544 HVBatMod_NumMinVlt "Module number - Minimum voltage; Enumeration  0 = Module 1, 15 = Module 16.";
CM_ SG_ 851 HVBatFull_Amp_Hr_Capacity "Total HV Battery Amp Hour Capacity";
CM_ SG_ 851 HVBatFull_Amp_Hr_Capacity_V "Total HV battery amp hour capacity validity; Invalid = [1]";
CM_ SG_ 851 HVBatMaxChgCurrAlwd "Maximum charge current allowed";
CM_ SG_ 851 HVBatMaxChgCurrAlwd_V "Maximum charge current allowed valid; Invalid = [1]";
CM_ SG_ 852 HVBatCell_Voltage_High_Thrsh "Cell voltage high threshold";
CM_ SG_ 852 HVBatCell_Voltage_Low_Thrsh "Cell voltage low threshold";
CM_ SG_ 852 HVBatHighTempThrsh "High Voltage Battery High Temperature Threshold";
CM_ SG_ 852 HVBatLowTempThrsh "High Voltage Battery low Temperature Threshold";
CM_ SG_ 1000 HEV_OnRq_BPCM "Ev service On request from BPCM";
CM_ SG_ 1000 HVBatChargeStat "ChargeStat";
CM_ SG_ 1000 HVBatCntctrOpnTime "Time Since Bat contactors last transitioned to Open";
CM_ SG_ 1000 HVBatPerWU12VChrg "High voltage pack wake up due to 12v charge, [1] = Periodic Wakeup";
CM_ SG_ 1000 HVBatPerWUThermal "High voltage battery pack wake up due to thermal request, [1] = Periodic Wakeup";
CM_ SG_ 1000 HVBatPerWakeUp "High voltage battery pack periodical wake up, [1] = Periodic Wakeup";
CM_ SG_ 1000 HVBatSleepTime "Time since BPCM last went to sleep.";
CM_ SG_ 1000 MIL_OnRq_BPCM "MIL Lamp request from BPCM.";
CM_ SG_ 1000 Prchrgpnltytimer "Precharge Penalty Timer";
CM_ SG_ 337 HVBat_Real_Time_Clock "32 bit Real Time Clock";
CM_ SG_ 337 HVBat_Real_Time_Clock_V "-";
CM_ SG_ 786 HBCNC_BOT "Battery over temperature";
CM_ SG_ 786 HBCNC_BUT "HV Battery under temperature";
CM_ SG_ 786 HBCO_CellVltMax_High "Cell Voltage too High";
CM_ SG_ 786 HBCO_CellVltMin_Low "Cell Voltage too Low";
CM_ SG_ 832 DateTmDay "Day";
CM_ SG_ 832 DateTmFormat "Date and Time Format";
CM_ SG_ 832 DateTmHour "Time of day: HOURS";
CM_ SG_ 832 DateTmMinute "Time of day: MINUTES";
CM_ SG_ 832 DateTmMonth "Month";
CM_ SG_ 832 DateTmSec "Time of day: SECONDS";
CM_ SG_ 832 DateTmYear "Date year";
CM_ SG_ 500 CRC_DAS_A3 "CRC-checksum byte 1 to 7 according to SAE J1850";
CM_ SG_ 500 MC_DAS_A3 "Message counter";
CM_ SG_ 499 DAS_EPB_APPLY_RQ "DAS request to apply EPB";
CM_ SG_ 499 DAS_EPB_RELSE_RQ "DAS request to release EPB";
CM_ SG_ 499 LFC_Request_Type "Longitudinal Force Control Request Type";
CM_ SG_ 499 RHSC_OpenLoopBraking_Rq "Longitudinal Force Control Open Loop Braking Request";
CM_ SG_ 499 SDS_Engaged_State "SDS Engaged Status";
CM_ SG_ 625 CRC_DAS_A5 "CRC-checksum byte 1 to 7 according to SAE J1850";
CM_ SG_ 625 DAS_EPB_APPLY_RQ "DAS request to apply EPB";
CM_ SG_ 625 DAS_EPB_RELSE_RQ "DAS request to apply EPB";
CM_ SG_ 625 MC_DAS_A5 "Message counter";
CM_ SG_ 625 SDS_Engaged_State "SDS Engaged Status";
CM_ SG_ 2015 DG_RQ_GLOBAL "Diagnostic-Request";
CM_ SG_ 1089 DG_RQ_GLOBAL_UDS "Diagnostic-Request";
CM_ SG_ 1900 D_RQ_AHCP "Diagnostic-Request";
CM_ SG_ 1898 D_RQ_APM "Diagnostic-Request";
CM_ SG_ 2023 D_RQ_BPCM "Diagnostic-Request";
CM_ SG_ 1899 D_RQ_EAC "Diagnostic-Request";
CM_ SG_ 1902 D_RQ_OBCM "Diagnostic-Request";
CM_ SG_ 1260 D_RS_AHCP "Diagnostic-Response";
CM_ SG_ 1258 D_RS_APM "Diagnostic-Response";
CM_ SG_ 2031 D_RS_BPCM "Diagnostic-Response";
CM_ SG_ 1259 D_RS_EAC "Diagnostic-Response";
CM_ SG_ 1262 D_RS_OBCM "Diagnostic-Response";
CM_ SG_ 793 CompElecCurr "CompElecCurr";
CM_ SG_ 793 CompElecCurrV "compressor current valid";
CM_ SG_ 793 CompElecPwr "CompElecPwr";
CM_ SG_ 793 CompElecPwrV "compressor power valid";
CM_ SG_ 793 CompFltStat "Compressor Fault status.";
CM_ SG_ 793 CompSpd "compressor speed";
CM_ SG_ 793 CompSpdIncrReq "compressor speed incr valid";
CM_ SG_ 793 CompSpdV "compressor speed valid";
CM_ SG_ 793 CompStat "comppressor state";
BA_DEF_ BO_  "App-Botschaft" ENUM  "nein","ja";
BA_DEF_ BO_  "CanMsgMinLen" INT 0 8;
BA_DEF_ BO_  "DiagRequest" ENUM  "nein","ja";
BA_DEF_ BO_  "DiagResponse" ENUM  "nein","ja";
BA_DEF_ BO_  "DiagState" ENUM  "nein","ja";
BA_DEF_ BO_  "GenMsgCycleTime" INT 0 65535;
BA_DEF_ BO_  "GenMsgCycleTimeActive" INT 0 65535;
BA_DEF_ BO_  "GenMsgDelayTime" INT 0 65535;
BA_DEF_ BO_  "GenMsgNrOfRepetitions" INT 0 65535;
BA_DEF_ BO_  "GenMsgSendType" ENUM  "cyclicX","spontanX","cyclicIfActiveX","spontanWithDelay","cyclicAndSpontanX","cyclicAndSpontanWithDelay","spontanWithRepitition","cyclicIfActiveAndSpontanWD","cyclicIfActiveFast","cyclicWithRepeatOnDemand","none";
BA_DEF_ BO_  "GenMsgStartDelayTime" INT 0 65535;
BA_DEF_ BO_  "GenMsgStartValue" STRING ;
BA_DEF_ BO_  "NWM-Botschaft" ENUM  "nein","ja";
BA_DEF_ BO_  "TpTxIndex" INT 0 99;
BA_DEF_  "Baudrate" INT 0 1000000;
BA_DEF_  "Manufacturer" ENUM  "DBAG","VAG","BMWAG","PAG","GM";
BA_DEF_  "NBTMax" INT 0 255;
BA_DEF_  "NBTMin" INT 0 255;
BA_DEF_  "NmMessageCount" INT 0 64;
BA_DEF_  "NWM-Basisadresse" HEX 0 536870911;
BA_DEF_  "NWM-Typ" ENUM  "zentral (MB-W210)","dezentral (MB-OSAN)","keines","VAG-OSEK","BMW-OSEK","PAG-OSEK","DBAG-OSEK";
BA_DEF_  "SamplePointMax" FLOAT 0 100;
BA_DEF_  "SamplePointMin" FLOAT 0 100;
BA_DEF_  "Version" HEX 0 4080;
BA_DEF_  "VersionWeek" INT 0 53;
BA_DEF_  "VersionYear" INT 0 99;
BA_DEF_ BU_  "NWM-Knoten" ENUM  "nein","ja";
BA_DEF_ BU_  "NWM-Stationsadresse" HEX 0 63;
BA_DEF_ BU_  "TpNodeBaseAddress" HEX 0 65535;
BA_DEF_ BU_  "TpOwnSystemEcuNumber" HEX 0 255;
BA_DEF_ SG_  "FlexKomComment" STRING ;
BA_DEF_ SG_  "FlexKomIsMotorola" ENUM  "nein","ja";
BA_DEF_ SG_  "FlexKomSID" INT 0 2147483647;
BA_DEF_ SG_  "FlexKomSigLaenge" INT 0 64;
BA_DEF_ SG_  "FlexKomSigName" STRING ;
BA_DEF_ SG_  "FlexKomSigStartPos" INT 0 63;
BA_DEF_ SG_  "FlexKomSigStartValue" STRING ;
BA_DEF_ SG_  "GenSigCycleTime" INT 0 65535;
BA_DEF_ SG_  "GenSigCycleTimeActive" INT 0 65535;
BA_DEF_ SG_  "GenSigSendType" ENUM  "cyclicX","spontanX","cyclicIfActiveX","spontanWithDelay","cyclicAndSpontanX","cyclicAndSpontanWithDelay","spontanWithRepitition","cyclicIfActiveAndSpontanWD","cyclicIfActiveFast","cyclicWithRepeatOnDemand","none";
BA_DEF_ SG_  "GenSigSNA" STRING ;
BA_DEF_ SG_  "GenSigStartValue" HEX 0 2147483648;
BA_DEF_ SG_  "RID" STRING ;
BA_DEF_DEF_  "App-Botschaft" "nein";
BA_DEF_DEF_  "CanMsgMinLen" 0;
BA_DEF_DEF_  "DiagRequest" "nein";
BA_DEF_DEF_  "DiagResponse" "nein";
BA_DEF_DEF_  "DiagState" "nein";
BA_DEF_DEF_  "GenMsgCycleTime" 0;
BA_DEF_DEF_  "GenMsgCycleTimeActive" 0;
BA_DEF_DEF_  "GenMsgDelayTime" 0;
BA_DEF_DEF_  "GenMsgNrOfRepetitions" 0;
BA_DEF_DEF_  "GenMsgSendType" "cyclicX";
BA_DEF_DEF_  "GenMsgStartDelayTime" 0;
BA_DEF_DEF_  "GenMsgStartValue" "";
BA_DEF_DEF_  "NWM-Botschaft" "nein";
BA_DEF_DEF_  "TpTxIndex" 0;
BA_DEF_DEF_  "Baudrate" 500000;
BA_DEF_DEF_  "Manufacturer" "DBAG";
BA_DEF_DEF_  "NBTMax" 20;
BA_DEF_DEF_  "NBTMin" 10;
BA_DEF_DEF_  "NmMessageCount" 64;
BA_DEF_DEF_  "NWM-Basisadresse" 1024;
BA_DEF_DEF_  "NWM-Typ" "DBAG-OSEK";
BA_DEF_DEF_  "SamplePointMax" 81.25;
BA_DEF_DEF_  "SamplePointMin" 75;
BA_DEF_DEF_  "Version" 4;
BA_DEF_DEF_  "VersionWeek" 26;
BA_DEF_DEF_  "VersionYear" 18;
BA_DEF_DEF_  "NWM-Knoten" "nein";
BA_DEF_DEF_  "NWM-Stationsadresse" 0;
BA_DEF_DEF_  "TpNodeBaseAddress" 0;
BA_DEF_DEF_  "TpOwnSystemEcuNumber" 0;
BA_DEF_DEF_  "FlexKomComment" "";
BA_DEF_DEF_  "FlexKomIsMotorola" "nein";
BA_DEF_DEF_  "FlexKomSID" 0;
BA_DEF_DEF_  "FlexKomSigLaenge" 0;
BA_DEF_DEF_  "FlexKomSigName" "";
BA_DEF_DEF_  "FlexKomSigStartPos" 0;
BA_DEF_DEF_  "FlexKomSigStartValue" "";
BA_DEF_DEF_  "GenSigCycleTime" 0;
BA_DEF_DEF_  "GenSigCycleTimeActive" 0;
BA_DEF_DEF_  "GenSigSendType" "cyclicX";
BA_DEF_DEF_  "GenSigSNA" "";
BA_DEF_DEF_  "GenSigStartValue" 0;
BA_DEF_DEF_  "RID" "";
BA_ "NWM-Stationsadresse" BU_ APM 42;
BA_ "NWM-Knoten" BU_ APM 1;
BA_ "NWM-Stationsadresse" BU_ OBCM 46;
BA_ "NWM-Knoten" BU_ OBCM 1;
BA_ "GenMsgStartValue" BO_ 565 "000000000FFF03FDh";
BA_ "GenMsgNrOfRepetitions" BO_ 565 2;
BA_ "GenMsgDelayTime" BO_ 565 20;
BA_ "GenMsgCycleTime" BO_ 565 50;
BA_ "GenMsgStartValue" BO_ 853 "0000000041414100h";
BA_ "GenMsgNrOfRepetitions" BO_ 853 2;
BA_ "GenMsgDelayTime" BO_ 853 20;
BA_ "GenMsgCycleTime" BO_ 853 250;
BA_ "GenMsgStartValue" BO_ 672 "000000D941413D00h";
BA_ "GenMsgNrOfRepetitions" BO_ 672 2;
BA_ "GenMsgDelayTime" BO_ 672 20;
BA_ "GenMsgCycleTime" BO_ 672 250;
BA_ "GenMsgStartValue" BO_ 855 "000003FD01FC0000h";
BA_ "GenMsgNrOfRepetitions" BO_ 855 2;
BA_ "GenMsgDelayTime" BO_ 855 20;
BA_ "GenMsgCycleTime" BO_ 855 100;
BA_ "GenMsgStartValue" BO_ 674 "0000000000000000h";
BA_ "GenMsgNrOfRepetitions" BO_ 674 2;
BA_ "GenMsgDelayTime" BO_ 674 20;
BA_ "GenMsgCycleTime" BO_ 674 250;
BA_ "GenMsgStartValue" BO_ 168 "0B830B830B8300FFh";
BA_ "GenMsgNrOfRepetitions" BO_ 168 2;
BA_ "GenMsgDelayTime" BO_ 168 20;
BA_ "GenMsgCycleTime" BO_ 168 10;
BA_ "GenMsgStartValue" BO_ 708 "0000000000000000h";
BA_ "GenMsgNrOfRepetitions" BO_ 708 2;
BA_ "GenMsgDelayTime" BO_ 708 20;
BA_ "GenMsgCycleTime" BO_ 708 1000;
BA_ "GenMsgStartValue" BO_ 710 "0000000000000000h";
BA_ "GenMsgNrOfRepetitions" BO_ 710 2;
BA_ "GenMsgDelayTime" BO_ 710 20;
BA_ "GenMsgCycleTime" BO_ 710 1000;
BA_ "GenMsgStartValue" BO_ 707 "0000000000000000h";
BA_ "GenMsgNrOfRepetitions" BO_ 707 2;
BA_ "GenMsgDelayTime" BO_ 707 20;
BA_ "GenMsgCycleTime" BO_ 707 1000;
BA_ "GenMsgStartValue" BO_ 773 "0000000000000000h";
BA_ "GenMsgNrOfRepetitions" BO_ 773 2;
BA_ "GenMsgDelayTime" BO_ 773 20;
BA_ "GenMsgCycleTime" BO_ 773 100;
BA_ "GenMsgStartValue" BO_ 774 "0000FAFA80808800h";
BA_ "GenMsgNrOfRepetitions" BO_ 774 2;
BA_ "GenMsgDelayTime" BO_ 774 20;
BA_ "GenMsgCycleTime" BO_ 774 100;
BA_ "GenMsgStartValue" BO_ 775 "0000000000000000h";
BA_ "GenMsgNrOfRepetitions" BO_ 775 2;
BA_ "GenMsgDelayTime" BO_ 775 20;
BA_ "GenMsgCycleTime" BO_ 775 100;
BA_ "GenMsgStartValue" BO_ 998 "FEFFFFFFFFFF3C1Eh";
BA_ "GenMsgNrOfRepetitions" BO_ 998 2;
BA_ "GenMsgDelayTime" BO_ 998 20;
BA_ "GenMsgCycleTime" BO_ 998 100;
BA_ "GenMsgStartValue" BO_ 854 "0000000000000000h";
BA_ "GenMsgNrOfRepetitions" BO_ 854 2;
BA_ "GenMsgDelayTime" BO_ 854 20;
BA_ "GenMsgCycleTime" BO_ 854 250;
BA_ "GenMsgStartValue" BO_ 336 "00000000000000FFh";
BA_ "GenMsgNrOfRepetitions" BO_ 336 2;
BA_ "GenMsgDelayTime" BO_ 336 20;
BA_ "GenMsgCycleTime" BO_ 336 10;
BA_ "GenMsgStartValue" BO_ 544 "0000000000000000h";
BA_ "GenMsgNrOfRepetitions" BO_ 544 2;
BA_ "GenMsgDelayTime" BO_ 544 20;
BA_ "GenMsgCycleTime" BO_ 544 20;
BA_ "GenMsgStartValue" BO_ 851 "0000000000000000h";
BA_ "GenMsgNrOfRepetitions" BO_ 851 2;
BA_ "GenMsgDelayTime" BO_ 851 20;
BA_ "GenMsgCycleTime" BO_ 851 250;
BA_ "GenMsgStartValue" BO_ 852 "0000141400000000h";
BA_ "GenMsgNrOfRepetitions" BO_ 852 2;
BA_ "GenMsgDelayTime" BO_ 852 20;
BA_ "GenMsgCycleTime" BO_ 852 250;
BA_ "GenMsgStartValue" BO_ 1000 "0000000000000000h";
BA_ "GenMsgNrOfRepetitions" BO_ 1000 2;
BA_ "GenMsgDelayTime" BO_ 1000 20;
BA_ "GenMsgCycleTime" BO_ 1000 100;
BA_ "GenMsgStartValue" BO_ 337 "0000000000000000h";
BA_ "GenMsgNrOfRepetitions" BO_ 337 2;
BA_ "GenMsgDelayTime" BO_ 337 20;
BA_ "GenMsgCycleTime" BO_ 337 1000;
BA_ "GenMsgStartValue" BO_ 786 "0000000000000000h";
BA_ "GenMsgNrOfRepetitions" BO_ 786 2;
BA_ "GenMsgDelayTime" BO_ 786 20;
BA_ "GenMsgCycleTime" BO_ 786 1000;
BA_ "GenMsgStartValue" BO_ 832 "FFFFFFFFFFFFFF3Fh";
BA_ "GenMsgNrOfRepetitions" BO_ 832 2;
BA_ "GenMsgDelayTime" BO_ 832 20;
BA_ "GenMsgCycleTime" BO_ 832 1000;
BA_ "GenMsgStartValue" BO_ 500 "1FFF0CCB000000FFh";
BA_ "GenMsgNrOfRepetitions" BO_ 500 2;
BA_ "GenMsgDelayTime" BO_ 500 20;
BA_ "GenMsgCycleTime" BO_ 500 20;
BA_ "GenMsgStartValue" BO_ 499 "1FFF0CCB000000FFh";
BA_ "GenMsgNrOfRepetitions" BO_ 499 2;
BA_ "GenMsgCycleTime" BO_ 499 10;
BA_ "GenMsgStartValue" BO_ 625 "000000FF000000FFh";
BA_ "GenMsgNrOfRepetitions" BO_ 625 2;
BA_ "GenMsgDelayTime" BO_ 625 20;
BA_ "GenMsgCycleTime" BO_ 625 20;
BA_ "GenMsgStartValue" BO_ 2015 "0000000000000000h";
BA_ "GenMsgNrOfRepetitions" BO_ 2015 2;
BA_ "GenMsgDelayTime" BO_ 2015 20;
BA_ "DiagState" BO_ 2015 1;
BA_ "GenMsgStartValue" BO_ 1089 "0000000000000000h";
BA_ "GenMsgNrOfRepetitions" BO_ 1089 2;
BA_ "GenMsgDelayTime" BO_ 1089 20;
BA_ "DiagState" BO_ 1089 1;
BA_ "GenMsgStartValue" BO_ 1900 "0000000000000000h";
BA_ "GenMsgNrOfRepetitions" BO_ 1900 2;
BA_ "GenMsgDelayTime" BO_ 1900 20;
BA_ "DiagRequest" BO_ 1900 1;
BA_ "GenMsgStartValue" BO_ 1898 "0000000000000000h";
BA_ "GenMsgNrOfRepetitions" BO_ 1898 2;
BA_ "GenMsgDelayTime" BO_ 1898 20;
BA_ "DiagRequest" BO_ 1898 1;
BA_ "GenMsgStartValue" BO_ 2023 "0000000000000000h";
BA_ "GenMsgNrOfRepetitions" BO_ 2023 2;
BA_ "GenMsgDelayTime" BO_ 2023 20;
BA_ "DiagRequest" BO_ 2023 1;
BA_ "GenMsgStartValue" BO_ 1899 "0000000000000000h";
BA_ "GenMsgNrOfRepetitions" BO_ 1899 2;
BA_ "GenMsgDelayTime" BO_ 1899 20;
BA_ "DiagRequest" BO_ 1899 1;
BA_ "GenMsgStartValue" BO_ 1902 "0000000000000000h";
BA_ "GenMsgNrOfRepetitions" BO_ 1902 2;
BA_ "GenMsgDelayTime" BO_ 1902 20;
BA_ "DiagRequest" BO_ 1902 1;
BA_ "GenMsgStartValue" BO_ 1260 "0000000000000000h";
BA_ "GenMsgNrOfRepetitions" BO_ 1260 2;
BA_ "GenMsgDelayTime" BO_ 1260 20;
BA_ "DiagResponse" BO_ 1260 1;
BA_ "GenMsgStartValue" BO_ 1258 "0000000000000000h";
BA_ "GenMsgNrOfRepetitions" BO_ 1258 2;
BA_ "GenMsgDelayTime" BO_ 1258 20;
BA_ "DiagResponse" BO_ 1258 1;
BA_ "GenMsgStartValue" BO_ 2031 "0000000000000000h";
BA_ "GenMsgNrOfRepetitions" BO_ 2031 2;
BA_ "GenMsgDelayTime" BO_ 2031 20;
BA_ "DiagResponse" BO_ 2031 1;
BA_ "GenMsgStartValue" BO_ 1259 "0000000000000000h";
BA_ "GenMsgNrOfRepetitions" BO_ 1259 2;
BA_ "GenMsgDelayTime" BO_ 1259 20;
BA_ "DiagResponse" BO_ 1259 1;
BA_ "GenMsgStartValue" BO_ 1262 "0000000000000000h";
BA_ "GenMsgNrOfRepetitions" BO_ 1262 2;
BA_ "GenMsgDelayTime" BO_ 1262 20;
BA_ "DiagResponse" BO_ 1262 1;
BA_ "GenMsgStartValue" BO_ 793 "000000000000h";
BA_ "GenMsgNrOfRepetitions" BO_ 793 2;
BA_ "GenMsgDelayTime" BO_ 793 20;
BA_ "GenMsgCycleTime" BO_ 793 100;
BA_ "GenSigStartValue" SG_ 565 APM_IdcHvFdbk 1021;
BA_ "GenSigSNA" SG_ 565 APM_IdcHvFdbk "FFFh";
BA_ "GenSigCycleTime" SG_ 565 APM_IdcHvFdbk 50;
BA_ "FlexKomSigStartValue" SG_ 565 APM_IdcHvFdbk "000000000FFF03FDh";
BA_ "FlexKomSigStartPos" SG_ 565 APM_IdcHvFdbk 7;
BA_ "FlexKomSigName" SG_ 565 APM_IdcHvFdbk "APM_01";
BA_ "FlexKomSigLaenge" SG_ 565 APM_IdcHvFdbk 64;
BA_ "FlexKomSID" SG_ 565 APM_IdcHvFdbk 2130708605;
BA_ "FlexKomIsMotorola" SG_ 565 APM_IdcHvFdbk 1;
BA_ "FlexKomComment" SG_ 565 APM_IdcHvFdbk ".";
BA_ "GenSigStartValue" SG_ 565 APM_IdcLvFdbk 4095;
BA_ "GenSigSNA" SG_ 565 APM_IdcLvFdbk "FFFh";
BA_ "GenSigCycleTime" SG_ 565 APM_IdcLvFdbk 50;
BA_ "FlexKomSigStartValue" SG_ 565 APM_IdcLvFdbk "000000000FFF03FDh";
BA_ "FlexKomSigStartPos" SG_ 565 APM_IdcLvFdbk 7;
BA_ "FlexKomSigName" SG_ 565 APM_IdcLvFdbk "APM_01";
BA_ "FlexKomSigLaenge" SG_ 565 APM_IdcLvFdbk 64;
BA_ "FlexKomSID" SG_ 565 APM_IdcLvFdbk 2130708605;
BA_ "FlexKomIsMotorola" SG_ 565 APM_IdcLvFdbk 1;
BA_ "FlexKomComment" SG_ 565 APM_IdcLvFdbk ".";
BA_ "GenSigSNA" SG_ 565 APM_OperModeStatus "Fh";
BA_ "GenSigCycleTime" SG_ 565 APM_OperModeStatus 50;
BA_ "FlexKomSigStartValue" SG_ 565 APM_OperModeStatus "000000000FFF03FDh";
BA_ "FlexKomSigStartPos" SG_ 565 APM_OperModeStatus 7;
BA_ "FlexKomSigName" SG_ 565 APM_OperModeStatus "APM_01";
BA_ "FlexKomSigLaenge" SG_ 565 APM_OperModeStatus 64;
BA_ "FlexKomSID" SG_ 565 APM_OperModeStatus 2130708605;
BA_ "FlexKomIsMotorola" SG_ 565 APM_OperModeStatus 1;
BA_ "FlexKomComment" SG_ 565 APM_OperModeStatus ".";
BA_ "GenSigSNA" SG_ 565 APM_VdcHvFdbk "FFFh";
BA_ "GenSigCycleTime" SG_ 565 APM_VdcHvFdbk 50;
BA_ "FlexKomSigStartValue" SG_ 565 APM_VdcHvFdbk "000000000FFF03FDh";
BA_ "FlexKomSigStartPos" SG_ 565 APM_VdcHvFdbk 7;
BA_ "FlexKomSigName" SG_ 565 APM_VdcHvFdbk "APM_01";
BA_ "FlexKomSigLaenge" SG_ 565 APM_VdcHvFdbk 64;
BA_ "FlexKomSID" SG_ 565 APM_VdcHvFdbk 2130708605;
BA_ "FlexKomIsMotorola" SG_ 565 APM_VdcHvFdbk 1;
BA_ "FlexKomComment" SG_ 565 APM_VdcHvFdbk ".";
BA_ "GenSigSNA" SG_ 565 APM_VdcLvFdbk "FFFh";
BA_ "GenSigCycleTime" SG_ 565 APM_VdcLvFdbk 50;
BA_ "FlexKomSigStartValue" SG_ 565 APM_VdcLvFdbk "000000000FFF03FDh";
BA_ "FlexKomSigStartPos" SG_ 565 APM_VdcLvFdbk 7;
BA_ "FlexKomSigName" SG_ 565 APM_VdcLvFdbk "APM_01";
BA_ "FlexKomSigLaenge" SG_ 565 APM_VdcLvFdbk 64;
BA_ "FlexKomSID" SG_ 565 APM_VdcLvFdbk 2130708605;
BA_ "FlexKomIsMotorola" SG_ 565 APM_VdcLvFdbk 1;
BA_ "FlexKomComment" SG_ 565 APM_VdcLvFdbk ".";
BA_ "GenSigSNA" SG_ 853 APM_CurrentLimitMode "0h";
BA_ "GenSigCycleTime" SG_ 853 APM_CurrentLimitMode 250;
BA_ "FlexKomSigStartValue" SG_ 853 APM_CurrentLimitMode "0000000041414100h";
BA_ "FlexKomSigStartPos" SG_ 853 APM_CurrentLimitMode 7;
BA_ "FlexKomSigName" SG_ 853 APM_CurrentLimitMode "APM_02";
BA_ "FlexKomSigLaenge" SG_ 853 APM_CurrentLimitMode 64;
BA_ "FlexKomSID" SG_ 853 APM_CurrentLimitMode 2130708606;
BA_ "FlexKomIsMotorola" SG_ 853 APM_CurrentLimitMode 1;
BA_ "FlexKomComment" SG_ 853 APM_CurrentLimitMode ".";
BA_ "GenSigSNA" SG_ 853 APM_HvOverVStatus "0h";
BA_ "GenSigCycleTime" SG_ 853 APM_HvOverVStatus 250;
BA_ "FlexKomSigStartValue" SG_ 853 APM_HvOverVStatus "0000000041414100h";
BA_ "FlexKomSigStartPos" SG_ 853 APM_HvOverVStatus 7;
BA_ "FlexKomSigName" SG_ 853 APM_HvOverVStatus "APM_02";
BA_ "FlexKomSigLaenge" SG_ 853 APM_HvOverVStatus 64;
BA_ "FlexKomSID" SG_ 853 APM_HvOverVStatus 2130708606;
BA_ "FlexKomIsMotorola" SG_ 853 APM_HvOverVStatus 1;
BA_ "FlexKomComment" SG_ 853 APM_HvOverVStatus ".";
BA_ "GenSigSNA" SG_ 853 APM_LvHighIStatus "0h";
BA_ "GenSigCycleTime" SG_ 853 APM_LvHighIStatus 250;
BA_ "FlexKomSigStartValue" SG_ 853 APM_LvHighIStatus "0000000041414100h";
BA_ "FlexKomSigStartPos" SG_ 853 APM_LvHighIStatus 7;
BA_ "FlexKomSigName" SG_ 853 APM_LvHighIStatus "APM_02";
BA_ "FlexKomSigLaenge" SG_ 853 APM_LvHighIStatus 64;
BA_ "FlexKomSID" SG_ 853 APM_LvHighIStatus 2130708606;
BA_ "FlexKomIsMotorola" SG_ 853 APM_LvHighIStatus 1;
BA_ "FlexKomComment" SG_ 853 APM_LvHighIStatus ".";
BA_ "GenSigSNA" SG_ 853 APM_LvHighVStatus "0h";
BA_ "GenSigCycleTime" SG_ 853 APM_LvHighVStatus 250;
BA_ "FlexKomSigStartValue" SG_ 853 APM_LvHighVStatus "0000000041414100h";
BA_ "FlexKomSigStartPos" SG_ 853 APM_LvHighVStatus 7;
BA_ "FlexKomSigName" SG_ 853 APM_LvHighVStatus "APM_02";
BA_ "FlexKomSigLaenge" SG_ 853 APM_LvHighVStatus 64;
BA_ "FlexKomSID" SG_ 853 APM_LvHighVStatus 2130708606;
BA_ "FlexKomIsMotorola" SG_ 853 APM_LvHighVStatus 1;
BA_ "FlexKomComment" SG_ 853 APM_LvHighVStatus ".";
BA_ "GenSigSNA" SG_ 853 APM_LvLowVStatus "0h";
BA_ "GenSigCycleTime" SG_ 853 APM_LvLowVStatus 250;
BA_ "FlexKomSigStartValue" SG_ 853 APM_LvLowVStatus "0000000041414100h";
BA_ "FlexKomSigStartPos" SG_ 853 APM_LvLowVStatus 7;
BA_ "FlexKomSigName" SG_ 853 APM_LvLowVStatus "APM_02";
BA_ "FlexKomSigLaenge" SG_ 853 APM_LvLowVStatus 64;
BA_ "FlexKomSID" SG_ 853 APM_LvLowVStatus 2130708606;
BA_ "FlexKomIsMotorola" SG_ 853 APM_LvLowVStatus 1;
BA_ "FlexKomComment" SG_ 853 APM_LvLowVStatus ".";
BA_ "GenSigSNA" SG_ 853 APM_PowerLimitMode "0h";
BA_ "GenSigCycleTime" SG_ 853 APM_PowerLimitMode 250;
BA_ "FlexKomSigStartValue" SG_ 853 APM_PowerLimitMode "0000000041414100h";
BA_ "FlexKomSigStartPos" SG_ 853 APM_PowerLimitMode 7;
BA_ "FlexKomSigName" SG_ 853 APM_PowerLimitMode "APM_02";
BA_ "FlexKomSigLaenge" SG_ 853 APM_PowerLimitMode 64;
BA_ "FlexKomSID" SG_ 853 APM_PowerLimitMode 2130708606;
BA_ "FlexKomIsMotorola" SG_ 853 APM_PowerLimitMode 1;
BA_ "FlexKomComment" SG_ 853 APM_PowerLimitMode ".";
BA_ "GenSigStartValue" SG_ 853 APM_TempColdPlate 65;
BA_ "GenSigSNA" SG_ 853 APM_TempColdPlate "FFh";
BA_ "GenSigCycleTime" SG_ 853 APM_TempColdPlate 250;
BA_ "FlexKomSigStartValue" SG_ 853 APM_TempColdPlate "0000000041414100h";
BA_ "FlexKomSigStartPos" SG_ 853 APM_TempColdPlate 7;
BA_ "FlexKomSigName" SG_ 853 APM_TempColdPlate "APM_02";
BA_ "FlexKomSigLaenge" SG_ 853 APM_TempColdPlate 64;
BA_ "FlexKomSID" SG_ 853 APM_TempColdPlate 2130708606;
BA_ "FlexKomIsMotorola" SG_ 853 APM_TempColdPlate 1;
BA_ "FlexKomComment" SG_ 853 APM_TempColdPlate ".";
BA_ "GenSigStartValue" SG_ 853 APM_TempOne 65;
BA_ "GenSigSNA" SG_ 853 APM_TempOne "FFh";
BA_ "GenSigCycleTime" SG_ 853 APM_TempOne 250;
BA_ "FlexKomSigStartValue" SG_ 853 APM_TempOne "0000000041414100h";
BA_ "FlexKomSigStartPos" SG_ 853 APM_TempOne 7;
BA_ "FlexKomSigName" SG_ 853 APM_TempOne "APM_02";
BA_ "FlexKomSigLaenge" SG_ 853 APM_TempOne 64;
BA_ "FlexKomSID" SG_ 853 APM_TempOne 2130708606;
BA_ "FlexKomIsMotorola" SG_ 853 APM_TempOne 1;
BA_ "FlexKomComment" SG_ 853 APM_TempOne ".";
BA_ "GenSigStartValue" SG_ 853 APM_TempTwo 65;
BA_ "GenSigSNA" SG_ 853 APM_TempTwo "FFh";
BA_ "GenSigCycleTime" SG_ 853 APM_TempTwo 250;
BA_ "FlexKomSigStartValue" SG_ 853 APM_TempTwo "0000000041414100h";
BA_ "FlexKomSigStartPos" SG_ 853 APM_TempTwo 7;
BA_ "FlexKomSigName" SG_ 853 APM_TempTwo "APM_02";
BA_ "FlexKomSigLaenge" SG_ 853 APM_TempTwo 64;
BA_ "FlexKomSID" SG_ 853 APM_TempTwo 2130708606;
BA_ "FlexKomIsMotorola" SG_ 853 APM_TempTwo 1;
BA_ "FlexKomComment" SG_ 853 APM_TempTwo ".";
BA_ "GenSigSNA" SG_ 853 APM_UtilPctOfDCDC "7Fh";
BA_ "GenSigCycleTime" SG_ 853 APM_UtilPctOfDCDC 250;
BA_ "FlexKomSigStartValue" SG_ 853 APM_UtilPctOfDCDC "0000000041414100h";
BA_ "FlexKomSigStartPos" SG_ 853 APM_UtilPctOfDCDC 7;
BA_ "FlexKomSigName" SG_ 853 APM_UtilPctOfDCDC "APM_02";
BA_ "FlexKomSigLaenge" SG_ 853 APM_UtilPctOfDCDC 64;
BA_ "FlexKomSID" SG_ 853 APM_UtilPctOfDCDC 2130708606;
BA_ "FlexKomIsMotorola" SG_ 853 APM_UtilPctOfDCDC 1;
BA_ "FlexKomComment" SG_ 853 APM_UtilPctOfDCDC ".";
BA_ "GenSigSNA" SG_ 672 APM_Battfeedvolt "FFFh";
BA_ "GenSigCycleTime" SG_ 672 APM_Battfeedvolt 250;
BA_ "FlexKomSigStartValue" SG_ 672 APM_Battfeedvolt "000000D941413D00h";
BA_ "FlexKomSigStartPos" SG_ 672 APM_Battfeedvolt 7;
BA_ "FlexKomSigName" SG_ 672 APM_Battfeedvolt "APM_03";
BA_ "FlexKomSigLaenge" SG_ 672 APM_Battfeedvolt 64;
BA_ "FlexKomSID" SG_ 672 APM_Battfeedvolt 2130708607;
BA_ "FlexKomIsMotorola" SG_ 672 APM_Battfeedvolt 1;
BA_ "FlexKomComment" SG_ 672 APM_Battfeedvolt ".";
BA_ "GenSigSNA" SG_ 672 APM_DeratingModeStatus "7h";
BA_ "GenSigCycleTime" SG_ 672 APM_DeratingModeStatus 250;
BA_ "FlexKomSigStartValue" SG_ 672 APM_DeratingModeStatus "000000D941413D00h";
BA_ "FlexKomSigStartPos" SG_ 672 APM_DeratingModeStatus 7;
BA_ "FlexKomSigName" SG_ 672 APM_DeratingModeStatus "APM_03";
BA_ "FlexKomSigLaenge" SG_ 672 APM_DeratingModeStatus 64;
BA_ "FlexKomSID" SG_ 672 APM_DeratingModeStatus 2130708607;
BA_ "FlexKomIsMotorola" SG_ 672 APM_DeratingModeStatus 1;
BA_ "FlexKomComment" SG_ 672 APM_DeratingModeStatus ".";
BA_ "GenSigStartValue" SG_ 672 APM_DeratingPower 61;
BA_ "GenSigSNA" SG_ 672 APM_DeratingPower "3Fh";
BA_ "GenSigCycleTime" SG_ 672 APM_DeratingPower 250;
BA_ "FlexKomSigStartValue" SG_ 672 APM_DeratingPower "000000D941413D00h";
BA_ "FlexKomSigStartPos" SG_ 672 APM_DeratingPower 7;
BA_ "FlexKomSigName" SG_ 672 APM_DeratingPower "APM_03";
BA_ "FlexKomSigLaenge" SG_ 672 APM_DeratingPower 64;
BA_ "FlexKomSID" SG_ 672 APM_DeratingPower 2130708607;
BA_ "FlexKomIsMotorola" SG_ 672 APM_DeratingPower 1;
BA_ "FlexKomComment" SG_ 672 APM_DeratingPower ".";
BA_ "GenSigSNA" SG_ 672 APM_DeratingReason "1Fh";
BA_ "GenSigCycleTime" SG_ 672 APM_DeratingReason 250;
BA_ "FlexKomSigStartValue" SG_ 672 APM_DeratingReason "000000D941413D00h";
BA_ "FlexKomSigStartPos" SG_ 672 APM_DeratingReason 7;
BA_ "FlexKomSigName" SG_ 672 APM_DeratingReason "APM_03";
BA_ "FlexKomSigLaenge" SG_ 672 APM_DeratingReason 64;
BA_ "FlexKomSID" SG_ 672 APM_DeratingReason 2130708607;
BA_ "FlexKomIsMotorola" SG_ 672 APM_DeratingReason 1;
BA_ "FlexKomComment" SG_ 672 APM_DeratingReason ".";
BA_ "GenSigStartValue" SG_ 672 APM_VdcLvSetPFdbk 217;
BA_ "GenSigSNA" SG_ 672 APM_VdcLvSetPFdbk "FFh";
BA_ "GenSigCycleTime" SG_ 672 APM_VdcLvSetPFdbk 250;
BA_ "FlexKomSigStartValue" SG_ 672 APM_VdcLvSetPFdbk "000000D941413D00h";
BA_ "FlexKomSigStartPos" SG_ 672 APM_VdcLvSetPFdbk 7;
BA_ "FlexKomSigName" SG_ 672 APM_VdcLvSetPFdbk "APM_03";
BA_ "FlexKomSigLaenge" SG_ 672 APM_VdcLvSetPFdbk 64;
BA_ "FlexKomSID" SG_ 672 APM_VdcLvSetPFdbk 2130708607;
BA_ "FlexKomIsMotorola" SG_ 672 APM_VdcLvSetPFdbk 1;
BA_ "FlexKomComment" SG_ 672 APM_VdcLvSetPFdbk ".";
BA_ "GenSigSNA" SG_ 855 APM_EstPwrLoss "FFh";
BA_ "GenSigCycleTime" SG_ 855 APM_EstPwrLoss 100;
BA_ "FlexKomSigStartValue" SG_ 855 APM_EstPwrLoss "000003FD01FC0000h";
BA_ "FlexKomSigStartPos" SG_ 855 APM_EstPwrLoss 7;
BA_ "FlexKomSigName" SG_ 855 APM_EstPwrLoss "APM_04";
BA_ "FlexKomSigLaenge" SG_ 855 APM_EstPwrLoss 64;
BA_ "FlexKomSID" SG_ 855 APM_EstPwrLoss 2130708608;
BA_ "FlexKomIsMotorola" SG_ 855 APM_EstPwrLoss 1;
BA_ "FlexKomComment" SG_ 855 APM_EstPwrLoss ".";
BA_ "GenSigSNA" SG_ 855 APM_FailureModeStatus "3h";
BA_ "GenSigCycleTime" SG_ 855 APM_FailureModeStatus 100;
BA_ "FlexKomSigStartValue" SG_ 855 APM_FailureModeStatus "000003FD01FC0000h";
BA_ "FlexKomSigStartPos" SG_ 855 APM_FailureModeStatus 7;
BA_ "FlexKomSigName" SG_ 855 APM_FailureModeStatus "APM_04";
BA_ "FlexKomSigLaenge" SG_ 855 APM_FailureModeStatus 64;
BA_ "FlexKomSID" SG_ 855 APM_FailureModeStatus 2130708608;
BA_ "FlexKomIsMotorola" SG_ 855 APM_FailureModeStatus 1;
BA_ "FlexKomComment" SG_ 855 APM_FailureModeStatus ".";
BA_ "GenSigSNA" SG_ 855 APM_FailureReason "3Fh";
BA_ "GenSigCycleTime" SG_ 855 APM_FailureReason 100;
BA_ "FlexKomSigStartValue" SG_ 855 APM_FailureReason "000003FD01FC0000h";
BA_ "FlexKomSigStartPos" SG_ 855 APM_FailureReason 7;
BA_ "FlexKomSigName" SG_ 855 APM_FailureReason "APM_04";
BA_ "FlexKomSigLaenge" SG_ 855 APM_FailureReason 64;
BA_ "FlexKomSID" SG_ 855 APM_FailureReason 2130708608;
BA_ "FlexKomIsMotorola" SG_ 855 APM_FailureReason 1;
BA_ "FlexKomComment" SG_ 855 APM_FailureReason ".";
BA_ "GenSigSNA" SG_ 855 APM_HvVsetPFdbk "1FFh";
BA_ "GenSigCycleTime" SG_ 855 APM_HvVsetPFdbk 100;
BA_ "FlexKomSigStartValue" SG_ 855 APM_HvVsetPFdbk "000003FD01FC0000h";
BA_ "FlexKomSigStartPos" SG_ 855 APM_HvVsetPFdbk 7;
BA_ "FlexKomSigName" SG_ 855 APM_HvVsetPFdbk "APM_04";
BA_ "FlexKomSigLaenge" SG_ 855 APM_HvVsetPFdbk 64;
BA_ "FlexKomSID" SG_ 855 APM_HvVsetPFdbk 2130708608;
BA_ "FlexKomIsMotorola" SG_ 855 APM_HvVsetPFdbk 1;
BA_ "FlexKomComment" SG_ 855 APM_HvVsetPFdbk ".";
BA_ "GenSigStartValue" SG_ 855 APM_IdcHvSetPFdbk 1021;
BA_ "GenSigSNA" SG_ 855 APM_IdcHvSetPFdbk "3FFh";
BA_ "GenSigCycleTime" SG_ 855 APM_IdcHvSetPFdbk 100;
BA_ "FlexKomSigStartValue" SG_ 855 APM_IdcHvSetPFdbk "000003FD01FC0000h";
BA_ "FlexKomSigStartPos" SG_ 855 APM_IdcHvSetPFdbk 7;
BA_ "FlexKomSigName" SG_ 855 APM_IdcHvSetPFdbk "APM_04";
BA_ "FlexKomSigLaenge" SG_ 855 APM_IdcHvSetPFdbk 64;
BA_ "FlexKomSID" SG_ 855 APM_IdcHvSetPFdbk 2130708608;
BA_ "FlexKomIsMotorola" SG_ 855 APM_IdcHvSetPFdbk 1;
BA_ "FlexKomComment" SG_ 855 APM_IdcHvSetPFdbk ".";
BA_ "GenSigSNA" SG_ 855 APM_Internal_Mode "7h";
BA_ "GenSigCycleTime" SG_ 855 APM_Internal_Mode 100;
BA_ "FlexKomSigStartValue" SG_ 855 APM_Internal_Mode "000003FD01FC0000h";
BA_ "FlexKomSigStartPos" SG_ 855 APM_Internal_Mode 7;
BA_ "FlexKomSigName" SG_ 855 APM_Internal_Mode "APM_04";
BA_ "FlexKomSigLaenge" SG_ 855 APM_Internal_Mode 64;
BA_ "FlexKomSID" SG_ 855 APM_Internal_Mode 2130708608;
BA_ "FlexKomIsMotorola" SG_ 855 APM_Internal_Mode 1;
BA_ "FlexKomComment" SG_ 855 APM_Internal_Mode ".";
BA_ "GenSigStartValue" SG_ 855 APM_LvIsetPFdbk 508;
BA_ "GenSigSNA" SG_ 855 APM_LvIsetPFdbk "1FFh";
BA_ "GenSigCycleTime" SG_ 855 APM_LvIsetPFdbk 100;
BA_ "FlexKomSigStartValue" SG_ 855 APM_LvIsetPFdbk "000003FD01FC0000h";
BA_ "FlexKomSigStartPos" SG_ 855 APM_LvIsetPFdbk 7;
BA_ "FlexKomSigName" SG_ 855 APM_LvIsetPFdbk "APM_04";
BA_ "FlexKomSigLaenge" SG_ 855 APM_LvIsetPFdbk 64;
BA_ "FlexKomSID" SG_ 855 APM_LvIsetPFdbk 2130708608;
BA_ "FlexKomIsMotorola" SG_ 855 APM_LvIsetPFdbk 1;
BA_ "FlexKomComment" SG_ 855 APM_LvIsetPFdbk ".";
BA_ "GenSigSNA" SG_ 674 APM_Coolantflowrequest "0h";
BA_ "GenSigCycleTime" SG_ 674 APM_Coolantflowrequest 250;
BA_ "FlexKomSigStartValue" SG_ 674 APM_Coolantflowrequest "0000000000000000h";
BA_ "FlexKomSigStartPos" SG_ 674 APM_Coolantflowrequest 7;
BA_ "FlexKomSigName" SG_ 674 APM_Coolantflowrequest "APM_05";
BA_ "FlexKomSigLaenge" SG_ 674 APM_Coolantflowrequest 64;
BA_ "FlexKomSID" SG_ 674 APM_Coolantflowrequest 2130708804;
BA_ "FlexKomIsMotorola" SG_ 674 APM_Coolantflowrequest 1;
BA_ "FlexKomComment" SG_ 674 APM_Coolantflowrequest ".";
BA_ "GenSigSNA" SG_ 674 APM_CurrentOperTime "FFFFh";
BA_ "GenSigCycleTime" SG_ 674 APM_CurrentOperTime 250;
BA_ "FlexKomSigStartValue" SG_ 674 APM_CurrentOperTime "0000000000000000h";
BA_ "FlexKomSigStartPos" SG_ 674 APM_CurrentOperTime 7;
BA_ "FlexKomSigName" SG_ 674 APM_CurrentOperTime "APM_05";
BA_ "FlexKomSigLaenge" SG_ 674 APM_CurrentOperTime 64;
BA_ "FlexKomSID" SG_ 674 APM_CurrentOperTime 2130708804;
BA_ "FlexKomIsMotorola" SG_ 674 APM_CurrentOperTime 1;
BA_ "FlexKomComment" SG_ 674 APM_CurrentOperTime ".";
BA_ "GenSigSNA" SG_ 674 APM_InputPower "3FFh";
BA_ "GenSigCycleTime" SG_ 674 APM_InputPower 250;
BA_ "FlexKomSigStartValue" SG_ 674 APM_InputPower "0000000000000000h";
BA_ "FlexKomSigStartPos" SG_ 674 APM_InputPower 7;
BA_ "FlexKomSigName" SG_ 674 APM_InputPower "APM_05";
BA_ "FlexKomSigLaenge" SG_ 674 APM_InputPower 64;
BA_ "FlexKomSID" SG_ 674 APM_InputPower 2130708804;
BA_ "FlexKomIsMotorola" SG_ 674 APM_InputPower 1;
BA_ "FlexKomComment" SG_ 674 APM_InputPower ".";
BA_ "GenSigSNA" SG_ 674 APM_OutputPower "3FFh";
BA_ "GenSigCycleTime" SG_ 674 APM_OutputPower 250;
BA_ "FlexKomSigStartValue" SG_ 674 APM_OutputPower "0000000000000000h";
BA_ "FlexKomSigStartPos" SG_ 674 APM_OutputPower 7;
BA_ "FlexKomSigName" SG_ 674 APM_OutputPower "APM_05";
BA_ "FlexKomSigLaenge" SG_ 674 APM_OutputPower 64;
BA_ "FlexKomSID" SG_ 674 APM_OutputPower 2130708804;
BA_ "FlexKomIsMotorola" SG_ 674 APM_OutputPower 1;
BA_ "FlexKomComment" SG_ 674 APM_OutputPower ".";
BA_ "GenSigSNA" SG_ 674 APM_TotalOperTime "FFFFh";
BA_ "GenSigCycleTime" SG_ 674 APM_TotalOperTime 250;
BA_ "FlexKomSigStartValue" SG_ 674 APM_TotalOperTime "0000000000000000h";
BA_ "FlexKomSigStartPos" SG_ 674 APM_TotalOperTime 7;
BA_ "FlexKomSigName" SG_ 674 APM_TotalOperTime "APM_05";
BA_ "FlexKomSigLaenge" SG_ 674 APM_TotalOperTime 64;
BA_ "FlexKomSID" SG_ 674 APM_TotalOperTime 2130708804;
BA_ "FlexKomIsMotorola" SG_ 674 APM_TotalOperTime 1;
BA_ "FlexKomComment" SG_ 674 APM_TotalOperTime ".";
BA_ "GenSigSNA" SG_ 674 APM_WUStatus "3h";
BA_ "GenSigCycleTime" SG_ 674 APM_WUStatus 250;
BA_ "FlexKomSigStartValue" SG_ 674 APM_WUStatus "0000000000000000h";
BA_ "FlexKomSigStartPos" SG_ 674 APM_WUStatus 7;
BA_ "FlexKomSigName" SG_ 674 APM_WUStatus "APM_05";
BA_ "FlexKomSigLaenge" SG_ 674 APM_WUStatus 64;
BA_ "FlexKomSID" SG_ 674 APM_WUStatus 2130708804;
BA_ "FlexKomIsMotorola" SG_ 674 APM_WUStatus 1;
BA_ "FlexKomComment" SG_ 674 APM_WUStatus ".";
BA_ "GenSigSNA" SG_ 674 APM_WUStatus_Reason "3h";
BA_ "GenSigCycleTime" SG_ 674 APM_WUStatus_Reason 250;
BA_ "FlexKomSigStartValue" SG_ 674 APM_WUStatus_Reason "0000000000000000h";
BA_ "FlexKomSigStartPos" SG_ 674 APM_WUStatus_Reason 7;
BA_ "FlexKomSigName" SG_ 674 APM_WUStatus_Reason "APM_05";
BA_ "FlexKomSigLaenge" SG_ 674 APM_WUStatus_Reason 64;
BA_ "FlexKomSID" SG_ 674 APM_WUStatus_Reason 2130708804;
BA_ "FlexKomIsMotorola" SG_ 674 APM_WUStatus_Reason 1;
BA_ "FlexKomComment" SG_ 674 APM_WUStatus_Reason ".";
BA_ "GenSigStartValue" SG_ 168 CRC_0A8h 255;
BA_ "GenSigSNA" SG_ 168 CRC_0A8h "FFh";
BA_ "GenSigCycleTime" SG_ 168 CRC_0A8h 10;
BA_ "FlexKomSigStartValue" SG_ 168 CRC_0A8h "0B830B830B8300FFh";
BA_ "FlexKomSigStartPos" SG_ 168 CRC_0A8h 7;
BA_ "FlexKomSigName" SG_ 168 CRC_0A8h "Axle_Torque_Information";
BA_ "FlexKomSigLaenge" SG_ 168 CRC_0A8h 64;
BA_ "FlexKomSID" SG_ 168 CRC_0A8h 2130708723;
BA_ "FlexKomIsMotorola" SG_ 168 CRC_0A8h 1;
BA_ "FlexKomComment" SG_ 168 CRC_0A8h ".";
BA_ "GenSigStartValue" SG_ 168 CmndAxleTorqPrdtd 2947;
BA_ "GenSigSNA" SG_ 168 CmndAxleTorqPrdtd "3FFFh";
BA_ "GenSigCycleTime" SG_ 168 CmndAxleTorqPrdtd 10;
BA_ "FlexKomSigStartValue" SG_ 168 CmndAxleTorqPrdtd "0B830B830B8300FFh";
BA_ "FlexKomSigStartPos" SG_ 168 CmndAxleTorqPrdtd 7;
BA_ "FlexKomSigName" SG_ 168 CmndAxleTorqPrdtd "Axle_Torque_Information";
BA_ "FlexKomSigLaenge" SG_ 168 CmndAxleTorqPrdtd 64;
BA_ "FlexKomSID" SG_ 168 CmndAxleTorqPrdtd 2130708723;
BA_ "FlexKomIsMotorola" SG_ 168 CmndAxleTorqPrdtd 1;
BA_ "FlexKomComment" SG_ 168 CmndAxleTorqPrdtd ".";
BA_ "GenSigSNA" SG_ 168 CmndAxleTorqRespTyp "0h";
BA_ "GenSigCycleTime" SG_ 168 CmndAxleTorqRespTyp 10;
BA_ "FlexKomSigStartValue" SG_ 168 CmndAxleTorqRespTyp "0B830B830B8300FFh";
BA_ "FlexKomSigStartPos" SG_ 168 CmndAxleTorqRespTyp 7;
BA_ "FlexKomSigName" SG_ 168 CmndAxleTorqRespTyp "Axle_Torque_Information";
BA_ "FlexKomSigLaenge" SG_ 168 CmndAxleTorqRespTyp 64;
BA_ "FlexKomSID" SG_ 168 CmndAxleTorqRespTyp 2130708723;
BA_ "FlexKomIsMotorola" SG_ 168 CmndAxleTorqRespTyp 1;
BA_ "FlexKomComment" SG_ 168 CmndAxleTorqRespTyp ".";
BA_ "GenSigStartValue" SG_ 168 DrvrIntndedAxleTorq 2947;
BA_ "GenSigSNA" SG_ 168 DrvrIntndedAxleTorq "3FFFh";
BA_ "GenSigCycleTime" SG_ 168 DrvrIntndedAxleTorq 10;
BA_ "FlexKomSigStartValue" SG_ 168 DrvrIntndedAxleTorq "0B830B830B8300FFh";
BA_ "FlexKomSigStartPos" SG_ 168 DrvrIntndedAxleTorq 7;
BA_ "FlexKomSigName" SG_ 168 DrvrIntndedAxleTorq "Axle_Torque_Information";
BA_ "FlexKomSigLaenge" SG_ 168 DrvrIntndedAxleTorq 64;
BA_ "FlexKomSID" SG_ 168 DrvrIntndedAxleTorq 2130708723;
BA_ "FlexKomIsMotorola" SG_ 168 DrvrIntndedAxleTorq 1;
BA_ "FlexKomComment" SG_ 168 DrvrIntndedAxleTorq ".";
BA_ "GenSigStartValue" SG_ 168 DrvrIntndedAxleTorqRaw 2947;
BA_ "GenSigSNA" SG_ 168 DrvrIntndedAxleTorqRaw "3FFFh";
BA_ "GenSigCycleTime" SG_ 168 DrvrIntndedAxleTorqRaw 10;
BA_ "FlexKomSigStartValue" SG_ 168 DrvrIntndedAxleTorqRaw "0B830B830B8300FFh";
BA_ "FlexKomSigStartPos" SG_ 168 DrvrIntndedAxleTorqRaw 7;
BA_ "FlexKomSigName" SG_ 168 DrvrIntndedAxleTorqRaw "Axle_Torque_Information";
BA_ "FlexKomSigLaenge" SG_ 168 DrvrIntndedAxleTorqRaw 64;
BA_ "FlexKomSID" SG_ 168 DrvrIntndedAxleTorqRaw 2130708723;
BA_ "FlexKomIsMotorola" SG_ 168 DrvrIntndedAxleTorqRaw 1;
BA_ "FlexKomComment" SG_ 168 DrvrIntndedAxleTorqRaw ".";
BA_ "GenSigSNA" SG_ 168 DrvrIntndedAxleTorqRawV "0h";
BA_ "GenSigCycleTime" SG_ 168 DrvrIntndedAxleTorqRawV 10;
BA_ "FlexKomSigStartValue" SG_ 168 DrvrIntndedAxleTorqRawV "0B830B830B8300FFh";
BA_ "FlexKomSigStartPos" SG_ 168 DrvrIntndedAxleTorqRawV 7;
BA_ "FlexKomSigName" SG_ 168 DrvrIntndedAxleTorqRawV "Axle_Torque_Information";
BA_ "FlexKomSigLaenge" SG_ 168 DrvrIntndedAxleTorqRawV 64;
BA_ "FlexKomSID" SG_ 168 DrvrIntndedAxleTorqRawV 2130708723;
BA_ "FlexKomIsMotorola" SG_ 168 DrvrIntndedAxleTorqRawV 1;
BA_ "FlexKomComment" SG_ 168 DrvrIntndedAxleTorqRawV ".";
BA_ "GenSigSNA" SG_ 168 DrvrIntndedAxleTorqV "0h";
BA_ "GenSigCycleTime" SG_ 168 DrvrIntndedAxleTorqV 10;
BA_ "FlexKomSigStartValue" SG_ 168 DrvrIntndedAxleTorqV "0B830B830B8300FFh";
BA_ "FlexKomSigStartPos" SG_ 168 DrvrIntndedAxleTorqV 7;
BA_ "FlexKomSigName" SG_ 168 DrvrIntndedAxleTorqV "Axle_Torque_Information";
BA_ "FlexKomSigLaenge" SG_ 168 DrvrIntndedAxleTorqV 64;
BA_ "FlexKomSID" SG_ 168 DrvrIntndedAxleTorqV 2130708723;
BA_ "FlexKomIsMotorola" SG_ 168 DrvrIntndedAxleTorqV 1;
BA_ "FlexKomComment" SG_ 168 DrvrIntndedAxleTorqV ".";
BA_ "GenSigSNA" SG_ 168 MC_0A8h "0h";
BA_ "GenSigCycleTime" SG_ 168 MC_0A8h 10;
BA_ "FlexKomSigStartValue" SG_ 168 MC_0A8h "0B830B830B8300FFh";
BA_ "FlexKomSigStartPos" SG_ 168 MC_0A8h 7;
BA_ "FlexKomSigName" SG_ 168 MC_0A8h "Axle_Torque_Information";
BA_ "FlexKomSigLaenge" SG_ 168 MC_0A8h 64;
BA_ "FlexKomSID" SG_ 168 MC_0A8h 2130708723;
BA_ "FlexKomIsMotorola" SG_ 168 MC_0A8h 1;
BA_ "FlexKomComment" SG_ 168 MC_0A8h ".";
BA_ "GenSigSNA" SG_ 708 HVBatBalComplete "0h";
BA_ "GenSigCycleTime" SG_ 708 HVBatBalComplete 1000;
BA_ "FlexKomSigStartValue" SG_ 708 HVBatBalComplete "0000000000000000h";
BA_ "FlexKomSigStartPos" SG_ 708 HVBatBalComplete 7;
BA_ "FlexKomSigName" SG_ 708 HVBatBalComplete "BPCM_HV_CellBalancing";
BA_ "FlexKomSigLaenge" SG_ 708 HVBatBalComplete 64;
BA_ "FlexKomSID" SG_ 708 HVBatBalComplete 2130708613;
BA_ "FlexKomIsMotorola" SG_ 708 HVBatBalComplete 1;
BA_ "FlexKomComment" SG_ 708 HVBatBalComplete "HV Cell Balancing";
BA_ "GenSigSNA" SG_ 708 HVBatBalMd "0h";
BA_ "GenSigCycleTime" SG_ 708 HVBatBalMd 1000;
BA_ "FlexKomSigStartValue" SG_ 708 HVBatBalMd "0000000000000000h";
BA_ "FlexKomSigStartPos" SG_ 708 HVBatBalMd 7;
BA_ "FlexKomSigName" SG_ 708 HVBatBalMd "BPCM_HV_CellBalancing";
BA_ "FlexKomSigLaenge" SG_ 708 HVBatBalMd 64;
BA_ "FlexKomSID" SG_ 708 HVBatBalMd 2130708613;
BA_ "FlexKomIsMotorola" SG_ 708 HVBatBalMd 1;
BA_ "FlexKomComment" SG_ 708 HVBatBalMd "HV Cell Balancing";
BA_ "GenSigSNA" SG_ 710 HVBatMax_Cell_Dischrg_Imped "FFFh";
BA_ "GenSigCycleTime" SG_ 710 HVBatMax_Cell_Dischrg_Imped 1000;
BA_ "FlexKomSigStartValue" SG_ 710 HVBatMax_Cell_Dischrg_Imped "0000000000000000h";
BA_ "FlexKomSigStartPos" SG_ 710 HVBatMax_Cell_Dischrg_Imped 7;
BA_ "FlexKomSigName" SG_ 710 HVBatMax_Cell_Dischrg_Imped "BPCM_HV_Impedance";
BA_ "FlexKomSigLaenge" SG_ 710 HVBatMax_Cell_Dischrg_Imped 64;
BA_ "FlexKomSID" SG_ 710 HVBatMax_Cell_Dischrg_Imped 2130708615;
BA_ "FlexKomIsMotorola" SG_ 710 HVBatMax_Cell_Dischrg_Imped 1;
BA_ "FlexKomComment" SG_ 710 HVBatMax_Cell_Dischrg_Imped ".";
BA_ "GenSigSNA" SG_ 710 HVBatMax_Cell_Dischrg_Imped_V "0h";
BA_ "GenSigCycleTime" SG_ 710 HVBatMax_Cell_Dischrg_Imped_V 1000;
BA_ "FlexKomSigStartValue" SG_ 710 HVBatMax_Cell_Dischrg_Imped_V "0000000000000000h";
BA_ "FlexKomSigStartPos" SG_ 710 HVBatMax_Cell_Dischrg_Imped_V 7;
BA_ "FlexKomSigName" SG_ 710 HVBatMax_Cell_Dischrg_Imped_V "BPCM_HV_Impedance";
BA_ "FlexKomSigLaenge" SG_ 710 HVBatMax_Cell_Dischrg_Imped_V 64;
BA_ "FlexKomSID" SG_ 710 HVBatMax_Cell_Dischrg_Imped_V 2130708615;
BA_ "FlexKomIsMotorola" SG_ 710 HVBatMax_Cell_Dischrg_Imped_V 1;
BA_ "FlexKomComment" SG_ 710 HVBatMax_Cell_Dischrg_Imped_V ".";
BA_ "GenSigSNA" SG_ 710 HVBatMin_Cell_Dischrg_Imped "FFFh";
BA_ "GenSigCycleTime" SG_ 710 HVBatMin_Cell_Dischrg_Imped 1000;
BA_ "FlexKomSigStartValue" SG_ 710 HVBatMin_Cell_Dischrg_Imped "0000000000000000h";
BA_ "FlexKomSigStartPos" SG_ 710 HVBatMin_Cell_Dischrg_Imped 7;
BA_ "FlexKomSigName" SG_ 710 HVBatMin_Cell_Dischrg_Imped "BPCM_HV_Impedance";
BA_ "FlexKomSigLaenge" SG_ 710 HVBatMin_Cell_Dischrg_Imped 64;
BA_ "FlexKomSID" SG_ 710 HVBatMin_Cell_Dischrg_Imped 2130708615;
BA_ "FlexKomIsMotorola" SG_ 710 HVBatMin_Cell_Dischrg_Imped 1;
BA_ "FlexKomComment" SG_ 710 HVBatMin_Cell_Dischrg_Imped ".";
BA_ "GenSigSNA" SG_ 710 HVBatMin_Cell_Dischrg_Imped_V "0h";
BA_ "GenSigCycleTime" SG_ 710 HVBatMin_Cell_Dischrg_Imped_V 1000;
BA_ "FlexKomSigStartValue" SG_ 710 HVBatMin_Cell_Dischrg_Imped_V "0000000000000000h";
BA_ "FlexKomSigStartPos" SG_ 710 HVBatMin_Cell_Dischrg_Imped_V 7;
BA_ "FlexKomSigName" SG_ 710 HVBatMin_Cell_Dischrg_Imped_V "BPCM_HV_Impedance";
BA_ "FlexKomSigLaenge" SG_ 710 HVBatMin_Cell_Dischrg_Imped_V 64;
BA_ "FlexKomSID" SG_ 710 HVBatMin_Cell_Dischrg_Imped_V 2130708615;
BA_ "FlexKomIsMotorola" SG_ 710 HVBatMin_Cell_Dischrg_Imped_V 1;
BA_ "FlexKomComment" SG_ 710 HVBatMin_Cell_Dischrg_Imped_V ".";
BA_ "GenSigSNA" SG_ 707 HVBatOCV_Ave_Cell_Voltage "FFFh";
BA_ "GenSigCycleTime" SG_ 707 HVBatOCV_Ave_Cell_Voltage 1000;
BA_ "FlexKomSigStartValue" SG_ 707 HVBatOCV_Ave_Cell_Voltage "0000000000000000h";
BA_ "FlexKomSigStartPos" SG_ 707 HVBatOCV_Ave_Cell_Voltage 7;
BA_ "FlexKomSigName" SG_ 707 HVBatOCV_Ave_Cell_Voltage "BPCM_HV_OCV";
BA_ "FlexKomSigLaenge" SG_ 707 HVBatOCV_Ave_Cell_Voltage 64;
BA_ "FlexKomSID" SG_ 707 HVBatOCV_Ave_Cell_Voltage 2130708616;
BA_ "FlexKomIsMotorola" SG_ 707 HVBatOCV_Ave_Cell_Voltage 1;
BA_ "FlexKomComment" SG_ 707 HVBatOCV_Ave_Cell_Voltage ".";
BA_ "GenSigSNA" SG_ 707 HVBatOCV_Ave_Cell_Voltage_V "0h";
BA_ "GenSigCycleTime" SG_ 707 HVBatOCV_Ave_Cell_Voltage_V 1000;
BA_ "FlexKomSigStartValue" SG_ 707 HVBatOCV_Ave_Cell_Voltage_V "0000000000000000h";
BA_ "FlexKomSigStartPos" SG_ 707 HVBatOCV_Ave_Cell_Voltage_V 7;
BA_ "FlexKomSigName" SG_ 707 HVBatOCV_Ave_Cell_Voltage_V "BPCM_HV_OCV";
BA_ "FlexKomSigLaenge" SG_ 707 HVBatOCV_Ave_Cell_Voltage_V 64;
BA_ "FlexKomSID" SG_ 707 HVBatOCV_Ave_Cell_Voltage_V 2130708616;
BA_ "FlexKomIsMotorola" SG_ 707 HVBatOCV_Ave_Cell_Voltage_V 1;
BA_ "FlexKomComment" SG_ 707 HVBatOCV_Ave_Cell_Voltage_V ".";
BA_ "GenSigSNA" SG_ 707 HVBatOCV_Max_Cell_Voltage "FFFh";
BA_ "GenSigCycleTime" SG_ 707 HVBatOCV_Max_Cell_Voltage 1000;
BA_ "FlexKomSigStartValue" SG_ 707 HVBatOCV_Max_Cell_Voltage "0000000000000000h";
BA_ "FlexKomSigStartPos" SG_ 707 HVBatOCV_Max_Cell_Voltage 7;
BA_ "FlexKomSigName" SG_ 707 HVBatOCV_Max_Cell_Voltage "BPCM_HV_OCV";
BA_ "FlexKomSigLaenge" SG_ 707 HVBatOCV_Max_Cell_Voltage 64;
BA_ "FlexKomSID" SG_ 707 HVBatOCV_Max_Cell_Voltage 2130708616;
BA_ "FlexKomIsMotorola" SG_ 707 HVBatOCV_Max_Cell_Voltage 1;
BA_ "FlexKomComment" SG_ 707 HVBatOCV_Max_Cell_Voltage ".";
BA_ "GenSigSNA" SG_ 707 HVBatOCV_Max_Cell_Voltage_V "0h";
BA_ "GenSigCycleTime" SG_ 707 HVBatOCV_Max_Cell_Voltage_V 1000;
BA_ "FlexKomSigStartValue" SG_ 707 HVBatOCV_Max_Cell_Voltage_V "0000000000000000h";
BA_ "FlexKomSigStartPos" SG_ 707 HVBatOCV_Max_Cell_Voltage_V 7;
BA_ "FlexKomSigName" SG_ 707 HVBatOCV_Max_Cell_Voltage_V "BPCM_HV_OCV";
BA_ "FlexKomSigLaenge" SG_ 707 HVBatOCV_Max_Cell_Voltage_V 64;
BA_ "FlexKomSID" SG_ 707 HVBatOCV_Max_Cell_Voltage_V 2130708616;
BA_ "FlexKomIsMotorola" SG_ 707 HVBatOCV_Max_Cell_Voltage_V 1;
BA_ "FlexKomComment" SG_ 707 HVBatOCV_Max_Cell_Voltage_V ".";
BA_ "GenSigSNA" SG_ 707 HVBatOCV_Min_Cell_Voltage "FFFh";
BA_ "GenSigCycleTime" SG_ 707 HVBatOCV_Min_Cell_Voltage 1000;
BA_ "FlexKomSigStartValue" SG_ 707 HVBatOCV_Min_Cell_Voltage "0000000000000000h";
BA_ "FlexKomSigStartPos" SG_ 707 HVBatOCV_Min_Cell_Voltage 7;
BA_ "FlexKomSigName" SG_ 707 HVBatOCV_Min_Cell_Voltage "BPCM_HV_OCV";
BA_ "FlexKomSigLaenge" SG_ 707 HVBatOCV_Min_Cell_Voltage 64;
BA_ "FlexKomSID" SG_ 707 HVBatOCV_Min_Cell_Voltage 2130708616;
BA_ "FlexKomIsMotorola" SG_ 707 HVBatOCV_Min_Cell_Voltage 1;
BA_ "FlexKomComment" SG_ 707 HVBatOCV_Min_Cell_Voltage ".";
BA_ "GenSigSNA" SG_ 707 HVBatOCV_Min_Cell_Voltage_V "0h";
BA_ "GenSigCycleTime" SG_ 707 HVBatOCV_Min_Cell_Voltage_V 1000;
BA_ "FlexKomSigStartValue" SG_ 707 HVBatOCV_Min_Cell_Voltage_V "0000000000000000h";
BA_ "FlexKomSigStartPos" SG_ 707 HVBatOCV_Min_Cell_Voltage_V 7;
BA_ "FlexKomSigName" SG_ 707 HVBatOCV_Min_Cell_Voltage_V "BPCM_HV_OCV";
BA_ "FlexKomSigLaenge" SG_ 707 HVBatOCV_Min_Cell_Voltage_V 64;
BA_ "FlexKomSID" SG_ 707 HVBatOCV_Min_Cell_Voltage_V 2130708616;
BA_ "FlexKomIsMotorola" SG_ 707 HVBatOCV_Min_Cell_Voltage_V 1;
BA_ "FlexKomComment" SG_ 707 HVBatOCV_Min_Cell_Voltage_V ".";
BA_ "GenSigSNA" SG_ 773 HVBatChrgPow10sec "FFh";
BA_ "GenSigCycleTime" SG_ 773 HVBatChrgPow10sec 100;
BA_ "FlexKomSigStartValue" SG_ 773 HVBatChrgPow10sec "0000000000000000h";
BA_ "FlexKomSigStartPos" SG_ 773 HVBatChrgPow10sec 7;
BA_ "FlexKomSigName" SG_ 773 HVBatChrgPow10sec "BPCM_HV_PowerLimits";
BA_ "FlexKomSigLaenge" SG_ 773 HVBatChrgPow10sec 64;
BA_ "FlexKomSID" SG_ 773 HVBatChrgPow10sec 2130708617;
BA_ "FlexKomIsMotorola" SG_ 773 HVBatChrgPow10sec 1;
BA_ "FlexKomComment" SG_ 773 HVBatChrgPow10sec ".";
BA_ "GenSigSNA" SG_ 773 HVBatChrgPow10secV "0h";
BA_ "GenSigCycleTime" SG_ 773 HVBatChrgPow10secV 100;
BA_ "FlexKomSigStartValue" SG_ 773 HVBatChrgPow10secV "0000000000000000h";
BA_ "FlexKomSigStartPos" SG_ 773 HVBatChrgPow10secV 7;
BA_ "FlexKomSigName" SG_ 773 HVBatChrgPow10secV "BPCM_HV_PowerLimits";
BA_ "FlexKomSigLaenge" SG_ 773 HVBatChrgPow10secV 64;
BA_ "FlexKomSID" SG_ 773 HVBatChrgPow10secV 2130708617;
BA_ "FlexKomIsMotorola" SG_ 773 HVBatChrgPow10secV 1;
BA_ "FlexKomComment" SG_ 773 HVBatChrgPow10secV ".";
BA_ "GenSigSNA" SG_ 773 HVBatChrgPow2sec "FFh";
BA_ "GenSigCycleTime" SG_ 773 HVBatChrgPow2sec 100;
BA_ "FlexKomSigStartValue" SG_ 773 HVBatChrgPow2sec "0000000000000000h";
BA_ "FlexKomSigStartPos" SG_ 773 HVBatChrgPow2sec 7;
BA_ "FlexKomSigName" SG_ 773 HVBatChrgPow2sec "BPCM_HV_PowerLimits";
BA_ "FlexKomSigLaenge" SG_ 773 HVBatChrgPow2sec 64;
BA_ "FlexKomSID" SG_ 773 HVBatChrgPow2sec 2130708617;
BA_ "FlexKomIsMotorola" SG_ 773 HVBatChrgPow2sec 1;
BA_ "FlexKomComment" SG_ 773 HVBatChrgPow2sec ".";
BA_ "GenSigSNA" SG_ 773 HVBatChrgPow2secV "0h";
BA_ "GenSigCycleTime" SG_ 773 HVBatChrgPow2secV 100;
BA_ "FlexKomSigStartValue" SG_ 773 HVBatChrgPow2secV "0000000000000000h";
BA_ "FlexKomSigStartPos" SG_ 773 HVBatChrgPow2secV 7;
BA_ "FlexKomSigName" SG_ 773 HVBatChrgPow2secV "BPCM_HV_PowerLimits";
BA_ "FlexKomSigLaenge" SG_ 773 HVBatChrgPow2secV 64;
BA_ "FlexKomSID" SG_ 773 HVBatChrgPow2secV 2130708617;
BA_ "FlexKomIsMotorola" SG_ 773 HVBatChrgPow2secV 1;
BA_ "FlexKomComment" SG_ 773 HVBatChrgPow2secV ".";
BA_ "GenSigSNA" SG_ 773 HVBatChrgPow30sec "FFh";
BA_ "GenSigCycleTime" SG_ 773 HVBatChrgPow30sec 100;
BA_ "FlexKomSigStartValue" SG_ 773 HVBatChrgPow30sec "0000000000000000h";
BA_ "FlexKomSigStartPos" SG_ 773 HVBatChrgPow30sec 7;
BA_ "FlexKomSigName" SG_ 773 HVBatChrgPow30sec "BPCM_HV_PowerLimits";
BA_ "FlexKomSigLaenge" SG_ 773 HVBatChrgPow30sec 64;
BA_ "FlexKomSID" SG_ 773 HVBatChrgPow30sec 2130708617;
BA_ "FlexKomIsMotorola" SG_ 773 HVBatChrgPow30sec 1;
BA_ "FlexKomComment" SG_ 773 HVBatChrgPow30sec ".";
BA_ "GenSigSNA" SG_ 773 HVBatChrgPow30secV "0h";
BA_ "GenSigCycleTime" SG_ 773 HVBatChrgPow30secV 100;
BA_ "FlexKomSigStartValue" SG_ 773 HVBatChrgPow30secV "0000000000000000h";
BA_ "FlexKomSigStartPos" SG_ 773 HVBatChrgPow30secV 7;
BA_ "FlexKomSigName" SG_ 773 HVBatChrgPow30secV "BPCM_HV_PowerLimits";
BA_ "FlexKomSigLaenge" SG_ 773 HVBatChrgPow30secV 64;
BA_ "FlexKomSID" SG_ 773 HVBatChrgPow30secV 2130708617;
BA_ "FlexKomIsMotorola" SG_ 773 HVBatChrgPow30secV 1;
BA_ "FlexKomComment" SG_ 773 HVBatChrgPow30secV ".";
BA_ "GenSigSNA" SG_ 773 HVBatDischrgPow10sec "FFh";
BA_ "GenSigCycleTime" SG_ 773 HVBatDischrgPow10sec 100;
BA_ "FlexKomSigStartValue" SG_ 773 HVBatDischrgPow10sec "0000000000000000h";
BA_ "FlexKomSigStartPos" SG_ 773 HVBatDischrgPow10sec 7;
BA_ "FlexKomSigName" SG_ 773 HVBatDischrgPow10sec "BPCM_HV_PowerLimits";
BA_ "FlexKomSigLaenge" SG_ 773 HVBatDischrgPow10sec 64;
BA_ "FlexKomSID" SG_ 773 HVBatDischrgPow10sec 2130708617;
BA_ "FlexKomIsMotorola" SG_ 773 HVBatDischrgPow10sec 1;
BA_ "FlexKomComment" SG_ 773 HVBatDischrgPow10sec ".";
BA_ "GenSigSNA" SG_ 773 HVBatDischrgPow10secV "0h";
BA_ "GenSigCycleTime" SG_ 773 HVBatDischrgPow10secV 100;
BA_ "FlexKomSigStartValue" SG_ 773 HVBatDischrgPow10secV "0000000000000000h";
BA_ "FlexKomSigStartPos" SG_ 773 HVBatDischrgPow10secV 7;
BA_ "FlexKomSigName" SG_ 773 HVBatDischrgPow10secV "BPCM_HV_PowerLimits";
BA_ "FlexKomSigLaenge" SG_ 773 HVBatDischrgPow10secV 64;
BA_ "FlexKomSID" SG_ 773 HVBatDischrgPow10secV 2130708617;
BA_ "FlexKomIsMotorola" SG_ 773 HVBatDischrgPow10secV 1;
BA_ "FlexKomComment" SG_ 773 HVBatDischrgPow10secV ".";
BA_ "GenSigSNA" SG_ 773 HVBatDischrgPow2sec "FFh";
BA_ "GenSigCycleTime" SG_ 773 HVBatDischrgPow2sec 100;
BA_ "FlexKomSigStartValue" SG_ 773 HVBatDischrgPow2sec "0000000000000000h";
BA_ "FlexKomSigStartPos" SG_ 773 HVBatDischrgPow2sec 7;
BA_ "FlexKomSigName" SG_ 773 HVBatDischrgPow2sec "BPCM_HV_PowerLimits";
BA_ "FlexKomSigLaenge" SG_ 773 HVBatDischrgPow2sec 64;
BA_ "FlexKomSID" SG_ 773 HVBatDischrgPow2sec 2130708617;
BA_ "FlexKomIsMotorola" SG_ 773 HVBatDischrgPow2sec 1;
BA_ "FlexKomComment" SG_ 773 HVBatDischrgPow2sec ".";
BA_ "GenSigSNA" SG_ 773 HVBatDischrgPow2secV "0h";
BA_ "GenSigCycleTime" SG_ 773 HVBatDischrgPow2secV 100;
BA_ "FlexKomSigStartValue" SG_ 773 HVBatDischrgPow2secV "0000000000000000h";
BA_ "FlexKomSigStartPos" SG_ 773 HVBatDischrgPow2secV 7;
BA_ "FlexKomSigName" SG_ 773 HVBatDischrgPow2secV "BPCM_HV_PowerLimits";
BA_ "FlexKomSigLaenge" SG_ 773 HVBatDischrgPow2secV 64;
BA_ "FlexKomSID" SG_ 773 HVBatDischrgPow2secV 2130708617;
BA_ "FlexKomIsMotorola" SG_ 773 HVBatDischrgPow2secV 1;
BA_ "FlexKomComment" SG_ 773 HVBatDischrgPow2secV ".";
BA_ "GenSigSNA" SG_ 773 HVBatDischrgPow30sec "FFh";
BA_ "GenSigCycleTime" SG_ 773 HVBatDischrgPow30sec 100;
BA_ "FlexKomSigStartValue" SG_ 773 HVBatDischrgPow30sec "0000000000000000h";
BA_ "FlexKomSigStartPos" SG_ 773 HVBatDischrgPow30sec 7;
BA_ "FlexKomSigName" SG_ 773 HVBatDischrgPow30sec "BPCM_HV_PowerLimits";
BA_ "FlexKomSigLaenge" SG_ 773 HVBatDischrgPow30sec 64;
BA_ "FlexKomSID" SG_ 773 HVBatDischrgPow30sec 2130708617;
BA_ "FlexKomIsMotorola" SG_ 773 HVBatDischrgPow30sec 1;
BA_ "FlexKomComment" SG_ 773 HVBatDischrgPow30sec ".";
BA_ "GenSigSNA" SG_ 773 HVBatDischrgPow30secV "0h";
BA_ "GenSigCycleTime" SG_ 773 HVBatDischrgPow30secV 100;
BA_ "FlexKomSigStartValue" SG_ 773 HVBatDischrgPow30secV "0000000000000000h";
BA_ "FlexKomSigStartPos" SG_ 773 HVBatDischrgPow30secV 7;
BA_ "FlexKomSigName" SG_ 773 HVBatDischrgPow30secV "BPCM_HV_PowerLimits";
BA_ "FlexKomSigLaenge" SG_ 773 HVBatDischrgPow30secV 64;
BA_ "FlexKomSID" SG_ 773 HVBatDischrgPow30secV 2130708617;
BA_ "FlexKomIsMotorola" SG_ 773 HVBatDischrgPow30secV 1;
BA_ "FlexKomComment" SG_ 773 HVBatDischrgPow30secV ".";
BA_ "GenSigSNA" SG_ 773 HVBatPwrLim_On_BPCM "0h";
BA_ "GenSigCycleTime" SG_ 773 HVBatPwrLim_On_BPCM 100;
BA_ "FlexKomSigStartValue" SG_ 773 HVBatPwrLim_On_BPCM "0000000000000000h";
BA_ "FlexKomSigStartPos" SG_ 773 HVBatPwrLim_On_BPCM 7;
BA_ "FlexKomSigName" SG_ 773 HVBatPwrLim_On_BPCM "BPCM_HV_PowerLimits";
BA_ "FlexKomSigLaenge" SG_ 773 HVBatPwrLim_On_BPCM 64;
BA_ "FlexKomSID" SG_ 773 HVBatPwrLim_On_BPCM 2130708617;
BA_ "FlexKomIsMotorola" SG_ 773 HVBatPwrLim_On_BPCM 1;
BA_ "FlexKomComment" SG_ 773 HVBatPwrLim_On_BPCM ".";
BA_ "GenSigStartValue" SG_ 774 HVBatSOC 2048;
BA_ "GenSigSNA" SG_ 774 HVBatSOC "800h";
BA_ "GenSigCycleTime" SG_ 774 HVBatSOC 100;
BA_ "FlexKomSigStartValue" SG_ 774 HVBatSOC "0000FAFA80808800h";
BA_ "FlexKomSigStartPos" SG_ 774 HVBatSOC 7;
BA_ "FlexKomSigName" SG_ 774 HVBatSOC "BPCM_HV_SOC";
BA_ "FlexKomSigLaenge" SG_ 774 HVBatSOC 64;
BA_ "FlexKomSID" SG_ 774 HVBatSOC 2130708618;
BA_ "FlexKomIsMotorola" SG_ 774 HVBatSOC 1;
BA_ "FlexKomComment" SG_ 774 HVBatSOC ".";
BA_ "GenSigStartValue" SG_ 774 HVBatSOCMax 128;
BA_ "GenSigSNA" SG_ 774 HVBatSOCMax "80h";
BA_ "GenSigCycleTime" SG_ 774 HVBatSOCMax 100;
BA_ "FlexKomSigStartValue" SG_ 774 HVBatSOCMax "0000FAFA80808800h";
BA_ "FlexKomSigStartPos" SG_ 774 HVBatSOCMax 7;
BA_ "FlexKomSigName" SG_ 774 HVBatSOCMax "BPCM_HV_SOC";
BA_ "FlexKomSigLaenge" SG_ 774 HVBatSOCMax 64;
BA_ "FlexKomSID" SG_ 774 HVBatSOCMax 2130708618;
BA_ "FlexKomIsMotorola" SG_ 774 HVBatSOCMax 1;
BA_ "FlexKomComment" SG_ 774 HVBatSOCMax ".";
BA_ "GenSigStartValue" SG_ 774 HVBatSOCMin 128;
BA_ "GenSigSNA" SG_ 774 HVBatSOCMin "80h";
BA_ "GenSigCycleTime" SG_ 774 HVBatSOCMin 100;
BA_ "FlexKomSigStartValue" SG_ 774 HVBatSOCMin "0000FAFA80808800h";
BA_ "FlexKomSigStartPos" SG_ 774 HVBatSOCMin 7;
BA_ "FlexKomSigName" SG_ 774 HVBatSOCMin "BPCM_HV_SOC";
BA_ "FlexKomSigLaenge" SG_ 774 HVBatSOCMin 64;
BA_ "FlexKomSID" SG_ 774 HVBatSOCMin 2130708618;
BA_ "FlexKomIsMotorola" SG_ 774 HVBatSOCMin 1;
BA_ "FlexKomComment" SG_ 774 HVBatSOCMin ".";
BA_ "GenSigStartValue" SG_ 774 HVBatSOCV 1;
BA_ "GenSigSNA" SG_ 774 HVBatSOCV "1h";
BA_ "GenSigCycleTime" SG_ 774 HVBatSOCV 100;
BA_ "FlexKomSigStartValue" SG_ 774 HVBatSOCV "0000FAFA80808800h";
BA_ "FlexKomSigStartPos" SG_ 774 HVBatSOCV 7;
BA_ "FlexKomSigName" SG_ 774 HVBatSOCV "BPCM_HV_SOC";
BA_ "FlexKomSigLaenge" SG_ 774 HVBatSOCV 64;
BA_ "FlexKomSID" SG_ 774 HVBatSOCV 2130708618;
BA_ "FlexKomIsMotorola" SG_ 774 HVBatSOCV 1;
BA_ "FlexKomComment" SG_ 774 HVBatSOCV ".";
BA_ "GenSigStartValue" SG_ 774 HVBatSOH 250;
BA_ "GenSigSNA" SG_ 774 HVBatSOH "FFh";
BA_ "GenSigCycleTime" SG_ 774 HVBatSOH 100;
BA_ "FlexKomSigStartValue" SG_ 774 HVBatSOH "0000FAFA80808800h";
BA_ "FlexKomSigStartPos" SG_ 774 HVBatSOH 7;
BA_ "FlexKomSigName" SG_ 774 HVBatSOH "BPCM_HV_SOC";
BA_ "FlexKomSigLaenge" SG_ 774 HVBatSOH 64;
BA_ "FlexKomSID" SG_ 774 HVBatSOH 2130708618;
BA_ "FlexKomIsMotorola" SG_ 774 HVBatSOH 1;
BA_ "FlexKomComment" SG_ 774 HVBatSOH ".";
BA_ "GenSigStartValue" SG_ 774 HVBatSOHLow 250;
BA_ "GenSigSNA" SG_ 774 HVBatSOHLow "FFh";
BA_ "GenSigCycleTime" SG_ 774 HVBatSOHLow 100;
BA_ "FlexKomSigStartValue" SG_ 774 HVBatSOHLow "0000FAFA80808800h";
BA_ "FlexKomSigStartPos" SG_ 774 HVBatSOHLow 7;
BA_ "FlexKomSigName" SG_ 774 HVBatSOHLow "BPCM_HV_SOC";
BA_ "FlexKomSigLaenge" SG_ 774 HVBatSOHLow 64;
BA_ "FlexKomSID" SG_ 774 HVBatSOHLow 2130708618;
BA_ "FlexKomIsMotorola" SG_ 774 HVBatSOHLow 1;
BA_ "FlexKomComment" SG_ 774 HVBatSOHLow ".";
BA_ "GenSigSNA" SG_ 774 OBCCoolTempIn "FFh";
BA_ "GenSigCycleTime" SG_ 774 OBCCoolTempIn 100;
BA_ "FlexKomSigStartValue" SG_ 774 OBCCoolTempIn "0000FAFA80808800h";
BA_ "FlexKomSigStartPos" SG_ 774 OBCCoolTempIn 7;
BA_ "FlexKomSigName" SG_ 774 OBCCoolTempIn "BPCM_HV_SOC";
BA_ "FlexKomSigLaenge" SG_ 774 OBCCoolTempIn 64;
BA_ "FlexKomSID" SG_ 774 OBCCoolTempIn 2130708618;
BA_ "FlexKomIsMotorola" SG_ 774 OBCCoolTempIn 1;
BA_ "FlexKomComment" SG_ 774 OBCCoolTempIn ".";
BA_ "GenSigSNA" SG_ 775 HVBatClgInletTemp "FFh";
BA_ "GenSigCycleTime" SG_ 775 HVBatClgInletTemp 100;
BA_ "FlexKomSigStartValue" SG_ 775 HVBatClgInletTemp "0000000000000000h";
BA_ "FlexKomSigStartPos" SG_ 775 HVBatClgInletTemp 7;
BA_ "FlexKomSigName" SG_ 775 HVBatClgInletTemp "BPCM_HV_Temperature";
BA_ "FlexKomSigLaenge" SG_ 775 HVBatClgInletTemp 64;
BA_ "FlexKomSID" SG_ 775 HVBatClgInletTemp 2130708619;
BA_ "FlexKomIsMotorola" SG_ 775 HVBatClgInletTemp 1;
BA_ "FlexKomComment" SG_ 775 HVBatClgInletTemp ".";
BA_ "GenSigSNA" SG_ 775 HVBatClgInletTempV "0h";
BA_ "GenSigCycleTime" SG_ 775 HVBatClgInletTempV 100;
BA_ "FlexKomSigStartValue" SG_ 775 HVBatClgInletTempV "0000000000000000h";
BA_ "FlexKomSigStartPos" SG_ 775 HVBatClgInletTempV 7;
BA_ "FlexKomSigName" SG_ 775 HVBatClgInletTempV "BPCM_HV_Temperature";
BA_ "FlexKomSigLaenge" SG_ 775 HVBatClgInletTempV 64;
BA_ "FlexKomSID" SG_ 775 HVBatClgInletTempV 2130708619;
BA_ "FlexKomIsMotorola" SG_ 775 HVBatClgInletTempV 1;
BA_ "FlexKomComment" SG_ 775 HVBatClgInletTempV ".";
BA_ "GenSigSNA" SG_ 775 HVBatClgOutletTemp "FFh";
BA_ "GenSigCycleTime" SG_ 775 HVBatClgOutletTemp 100;
BA_ "FlexKomSigStartValue" SG_ 775 HVBatClgOutletTemp "0000000000000000h";
BA_ "FlexKomSigStartPos" SG_ 775 HVBatClgOutletTemp 7;
BA_ "FlexKomSigName" SG_ 775 HVBatClgOutletTemp "BPCM_HV_Temperature";
BA_ "FlexKomSigLaenge" SG_ 775 HVBatClgOutletTemp 64;
BA_ "FlexKomSID" SG_ 775 HVBatClgOutletTemp 2130708619;
BA_ "FlexKomIsMotorola" SG_ 775 HVBatClgOutletTemp 1;
BA_ "FlexKomComment" SG_ 775 HVBatClgOutletTemp ".";
BA_ "GenSigSNA" SG_ 775 HVBatClgOutletTempV "0h";
BA_ "GenSigCycleTime" SG_ 775 HVBatClgOutletTempV 100;
BA_ "FlexKomSigStartValue" SG_ 775 HVBatClgOutletTempV "0000000000000000h";
BA_ "FlexKomSigStartPos" SG_ 775 HVBatClgOutletTempV 7;
BA_ "FlexKomSigName" SG_ 775 HVBatClgOutletTempV "BPCM_HV_Temperature";
BA_ "FlexKomSigLaenge" SG_ 775 HVBatClgOutletTempV 64;
BA_ "FlexKomSID" SG_ 775 HVBatClgOutletTempV 2130708619;
BA_ "FlexKomIsMotorola" SG_ 775 HVBatClgOutletTempV 1;
BA_ "FlexKomComment" SG_ 775 HVBatClgOutletTempV ".";
BA_ "GenSigSNA" SG_ 775 HVBatModTempAvg "FFh";
BA_ "GenSigCycleTime" SG_ 775 HVBatModTempAvg 100;
BA_ "FlexKomSigStartValue" SG_ 775 HVBatModTempAvg "0000000000000000h";
BA_ "FlexKomSigStartPos" SG_ 775 HVBatModTempAvg 7;
BA_ "FlexKomSigName" SG_ 775 HVBatModTempAvg "BPCM_HV_Temperature";
BA_ "FlexKomSigLaenge" SG_ 775 HVBatModTempAvg 64;
BA_ "FlexKomSID" SG_ 775 HVBatModTempAvg 2130708619;
BA_ "FlexKomIsMotorola" SG_ 775 HVBatModTempAvg 1;
BA_ "FlexKomComment" SG_ 775 HVBatModTempAvg ".";
BA_ "GenSigSNA" SG_ 775 HVBatModTempMax "FFh";
BA_ "GenSigCycleTime" SG_ 775 HVBatModTempMax 100;
BA_ "FlexKomSigStartValue" SG_ 775 HVBatModTempMax "0000000000000000h";
BA_ "FlexKomSigStartPos" SG_ 775 HVBatModTempMax 7;
BA_ "FlexKomSigName" SG_ 775 HVBatModTempMax "BPCM_HV_Temperature";
BA_ "FlexKomSigLaenge" SG_ 775 HVBatModTempMax 64;
BA_ "FlexKomSID" SG_ 775 HVBatModTempMax 2130708619;
BA_ "FlexKomIsMotorola" SG_ 775 HVBatModTempMax 1;
BA_ "FlexKomComment" SG_ 775 HVBatModTempMax ".";
BA_ "GenSigSNA" SG_ 775 HVBatModTempMaxV "0h";
BA_ "GenSigCycleTime" SG_ 775 HVBatModTempMaxV 100;
BA_ "FlexKomSigStartValue" SG_ 775 HVBatModTempMaxV "0000000000000000h";
BA_ "FlexKomSigStartPos" SG_ 775 HVBatModTempMaxV 7;
BA_ "FlexKomSigName" SG_ 775 HVBatModTempMaxV "BPCM_HV_Temperature";
BA_ "FlexKomSigLaenge" SG_ 775 HVBatModTempMaxV 64;
BA_ "FlexKomSID" SG_ 775 HVBatModTempMaxV 2130708619;
BA_ "FlexKomIsMotorola" SG_ 775 HVBatModTempMaxV 1;
BA_ "FlexKomComment" SG_ 775 HVBatModTempMaxV ".";
BA_ "GenSigSNA" SG_ 775 HVBatModTempMin "FFh";
BA_ "GenSigCycleTime" SG_ 775 HVBatModTempMin 100;
BA_ "FlexKomSigStartValue" SG_ 775 HVBatModTempMin "0000000000000000h";
BA_ "FlexKomSigStartPos" SG_ 775 HVBatModTempMin 7;
BA_ "FlexKomSigName" SG_ 775 HVBatModTempMin "BPCM_HV_Temperature";
BA_ "FlexKomSigLaenge" SG_ 775 HVBatModTempMin 64;
BA_ "FlexKomSID" SG_ 775 HVBatModTempMin 2130708619;
BA_ "FlexKomIsMotorola" SG_ 775 HVBatModTempMin 1;
BA_ "FlexKomComment" SG_ 775 HVBatModTempMin ".";
BA_ "GenSigSNA" SG_ 775 HVBatModTempMinV "0h";
BA_ "GenSigCycleTime" SG_ 775 HVBatModTempMinV 100;
BA_ "FlexKomSigStartValue" SG_ 775 HVBatModTempMinV "0000000000000000h";
BA_ "FlexKomSigStartPos" SG_ 775 HVBatModTempMinV 7;
BA_ "FlexKomSigName" SG_ 775 HVBatModTempMinV "BPCM_HV_Temperature";
BA_ "FlexKomSigLaenge" SG_ 775 HVBatModTempMinV 64;
BA_ "FlexKomSID" SG_ 775 HVBatModTempMinV 2130708619;
BA_ "FlexKomIsMotorola" SG_ 775 HVBatModTempMinV 1;
BA_ "FlexKomComment" SG_ 775 HVBatModTempMinV ".";
BA_ "GenSigSNA" SG_ 775 HVBatMod_NumMaxTmp "0h";
BA_ "GenSigCycleTime" SG_ 775 HVBatMod_NumMaxTmp 100;
BA_ "FlexKomSigStartValue" SG_ 775 HVBatMod_NumMaxTmp "0000000000000000h";
BA_ "FlexKomSigStartPos" SG_ 775 HVBatMod_NumMaxTmp 7;
BA_ "FlexKomSigName" SG_ 775 HVBatMod_NumMaxTmp "BPCM_HV_Temperature";
BA_ "FlexKomSigLaenge" SG_ 775 HVBatMod_NumMaxTmp 64;
BA_ "FlexKomSID" SG_ 775 HVBatMod_NumMaxTmp 2130708619;
BA_ "FlexKomIsMotorola" SG_ 775 HVBatMod_NumMaxTmp 1;
BA_ "FlexKomComment" SG_ 775 HVBatMod_NumMaxTmp ".";
BA_ "GenSigSNA" SG_ 775 HVBatMod_NumMinTmp "0h";
BA_ "GenSigCycleTime" SG_ 775 HVBatMod_NumMinTmp 100;
BA_ "FlexKomSigStartValue" SG_ 775 HVBatMod_NumMinTmp "0000000000000000h";
BA_ "FlexKomSigStartPos" SG_ 775 HVBatMod_NumMinTmp 7;
BA_ "FlexKomSigName" SG_ 775 HVBatMod_NumMinTmp "BPCM_HV_Temperature";
BA_ "FlexKomSigLaenge" SG_ 775 HVBatMod_NumMinTmp 64;
BA_ "FlexKomSID" SG_ 775 HVBatMod_NumMinTmp 2130708619;
BA_ "FlexKomIsMotorola" SG_ 775 HVBatMod_NumMinTmp 1;
BA_ "FlexKomComment" SG_ 775 HVBatMod_NumMinTmp ".";
BA_ "GenSigSNA" SG_ 775 HVBatModlTempAvgV "0h";
BA_ "GenSigCycleTime" SG_ 775 HVBatModlTempAvgV 100;
BA_ "FlexKomSigStartValue" SG_ 775 HVBatModlTempAvgV "0000000000000000h";
BA_ "FlexKomSigStartPos" SG_ 775 HVBatModlTempAvgV 7;
BA_ "FlexKomSigName" SG_ 775 HVBatModlTempAvgV "BPCM_HV_Temperature";
BA_ "FlexKomSigLaenge" SG_ 775 HVBatModlTempAvgV 64;
BA_ "FlexKomSID" SG_ 775 HVBatModlTempAvgV 2130708619;
BA_ "FlexKomIsMotorola" SG_ 775 HVBatModlTempAvgV 1;
BA_ "FlexKomComment" SG_ 775 HVBatModlTempAvgV ".";
BA_ "GenSigStartValue" SG_ 998 LTActPumpCrnt 255;
BA_ "GenSigSNA" SG_ 998 LTActPumpCrnt "FFh";
BA_ "GenSigCycleTime" SG_ 998 LTActPumpCrnt 100;
BA_ "FlexKomSigStartValue" SG_ 998 LTActPumpCrnt "FEFFFFFFFFFF3C1Eh";
BA_ "FlexKomSigStartPos" SG_ 998 LTActPumpCrnt 7;
BA_ "FlexKomSigName" SG_ 998 LTActPumpCrnt "BPCM_HV_Thermal_Status1";
BA_ "FlexKomSigLaenge" SG_ 998 LTActPumpCrnt 64;
BA_ "FlexKomSID" SG_ 998 LTActPumpCrnt 2130708620;
BA_ "FlexKomIsMotorola" SG_ 998 LTActPumpCrnt 1;
BA_ "FlexKomComment" SG_ 998 LTActPumpCrnt ".";
BA_ "GenSigStartValue" SG_ 998 LTActPumpDeblock 3;
BA_ "GenSigSNA" SG_ 998 LTActPumpDeblock "3h";
BA_ "GenSigCycleTime" SG_ 998 LTActPumpDeblock 100;
BA_ "FlexKomSigStartValue" SG_ 998 LTActPumpDeblock "FEFFFFFFFFFF3C1Eh";
BA_ "FlexKomSigStartPos" SG_ 998 LTActPumpDeblock 7;
BA_ "FlexKomSigName" SG_ 998 LTActPumpDeblock "BPCM_HV_Thermal_Status1";
BA_ "FlexKomSigLaenge" SG_ 998 LTActPumpDeblock 64;
BA_ "FlexKomSID" SG_ 998 LTActPumpDeblock 2130708620;
BA_ "FlexKomIsMotorola" SG_ 998 LTActPumpDeblock 1;
BA_ "FlexKomComment" SG_ 998 LTActPumpDeblock ".";
BA_ "GenSigStartValue" SG_ 998 LTActPumpDryRun 3;
BA_ "GenSigSNA" SG_ 998 LTActPumpDryRun "3h";
BA_ "GenSigCycleTime" SG_ 998 LTActPumpDryRun 100;
BA_ "FlexKomSigStartValue" SG_ 998 LTActPumpDryRun "FEFFFFFFFFFF3C1Eh";
BA_ "FlexKomSigStartPos" SG_ 998 LTActPumpDryRun 7;
BA_ "FlexKomSigName" SG_ 998 LTActPumpDryRun "BPCM_HV_Thermal_Status1";
BA_ "FlexKomSigLaenge" SG_ 998 LTActPumpDryRun 64;
BA_ "FlexKomSID" SG_ 998 LTActPumpDryRun 2130708620;
BA_ "FlexKomIsMotorola" SG_ 998 LTActPumpDryRun 1;
BA_ "FlexKomComment" SG_ 998 LTActPumpDryRun ".";
BA_ "GenSigSNA" SG_ 998 LTActPumpFailsafe "0h";
BA_ "GenSigCycleTime" SG_ 998 LTActPumpFailsafe 100;
BA_ "FlexKomSigStartValue" SG_ 998 LTActPumpFailsafe "FEFFFFFFFFFF3C1Eh";
BA_ "FlexKomSigStartPos" SG_ 998 LTActPumpFailsafe 7;
BA_ "FlexKomSigName" SG_ 998 LTActPumpFailsafe "BPCM_HV_Thermal_Status1";
BA_ "FlexKomSigLaenge" SG_ 998 LTActPumpFailsafe 64;
BA_ "FlexKomSID" SG_ 998 LTActPumpFailsafe 2130708620;
BA_ "FlexKomIsMotorola" SG_ 998 LTActPumpFailsafe 1;
BA_ "FlexKomComment" SG_ 998 LTActPumpFailsafe ".";
BA_ "GenSigStartValue" SG_ 998 LTActPumpLimpHmAnON 3;
BA_ "GenSigSNA" SG_ 998 LTActPumpLimpHmAnON "3h";
BA_ "GenSigCycleTime" SG_ 998 LTActPumpLimpHmAnON 100;
BA_ "FlexKomSigStartValue" SG_ 998 LTActPumpLimpHmAnON "FEFFFFFFFFFF3C1Eh";
BA_ "FlexKomSigStartPos" SG_ 998 LTActPumpLimpHmAnON 7;
BA_ "FlexKomSigName" SG_ 998 LTActPumpLimpHmAnON "BPCM_HV_Thermal_Status1";
BA_ "FlexKomSigLaenge" SG_ 998 LTActPumpLimpHmAnON 64;
BA_ "FlexKomSID" SG_ 998 LTActPumpLimpHmAnON 2130708620;
BA_ "FlexKomIsMotorola" SG_ 998 LTActPumpLimpHmAnON 1;
BA_ "FlexKomComment" SG_ 998 LTActPumpLimpHmAnON ".";
BA_ "GenSigStartValue" SG_ 998 LTActPumpMontrngRPM 3;
BA_ "GenSigSNA" SG_ 998 LTActPumpMontrngRPM "3h";
BA_ "GenSigCycleTime" SG_ 998 LTActPumpMontrngRPM 100;
BA_ "FlexKomSigStartValue" SG_ 998 LTActPumpMontrngRPM "FEFFFFFFFFFF3C1Eh";
BA_ "FlexKomSigStartPos" SG_ 998 LTActPumpMontrngRPM 7;
BA_ "FlexKomSigName" SG_ 998 LTActPumpMontrngRPM "BPCM_HV_Thermal_Status1";
BA_ "FlexKomSigLaenge" SG_ 998 LTActPumpMontrngRPM 64;
BA_ "FlexKomSID" SG_ 998 LTActPumpMontrngRPM 2130708620;
BA_ "FlexKomIsMotorola" SG_ 998 LTActPumpMontrngRPM 1;
BA_ "FlexKomComment" SG_ 998 LTActPumpMontrngRPM ".";
BA_ "GenSigSNA" SG_ 998 LTActPumpNodeErr "0h";
BA_ "GenSigCycleTime" SG_ 998 LTActPumpNodeErr 100;
BA_ "FlexKomSigStartValue" SG_ 998 LTActPumpNodeErr "FEFFFFFFFFFF3C1Eh";
BA_ "FlexKomSigStartPos" SG_ 998 LTActPumpNodeErr 7;
BA_ "FlexKomSigName" SG_ 998 LTActPumpNodeErr "BPCM_HV_Thermal_Status1";
BA_ "FlexKomSigLaenge" SG_ 998 LTActPumpNodeErr 64;
BA_ "FlexKomSID" SG_ 998 LTActPumpNodeErr 2130708620;
BA_ "FlexKomIsMotorola" SG_ 998 LTActPumpNodeErr 1;
BA_ "FlexKomComment" SG_ 998 LTActPumpNodeErr ".";
BA_ "GenSigSNA" SG_ 998 LTActPumpOvrCrnt "0h";
BA_ "GenSigCycleTime" SG_ 998 LTActPumpOvrCrnt 100;
BA_ "FlexKomSigStartValue" SG_ 998 LTActPumpOvrCrnt "FEFFFFFFFFFF3C1Eh";
BA_ "FlexKomSigStartPos" SG_ 998 LTActPumpOvrCrnt 7;
BA_ "FlexKomSigName" SG_ 998 LTActPumpOvrCrnt "BPCM_HV_Thermal_Status1";
BA_ "FlexKomSigLaenge" SG_ 998 LTActPumpOvrCrnt 64;
BA_ "FlexKomSID" SG_ 998 LTActPumpOvrCrnt 2130708620;
BA_ "FlexKomIsMotorola" SG_ 998 LTActPumpOvrCrnt 1;
BA_ "FlexKomComment" SG_ 998 LTActPumpOvrCrnt ".";
BA_ "GenSigStartValue" SG_ 998 LTActPumpOvrTemp 3;
BA_ "GenSigSNA" SG_ 998 LTActPumpOvrTemp "3h";
BA_ "GenSigCycleTime" SG_ 998 LTActPumpOvrTemp 100;
BA_ "FlexKomSigStartValue" SG_ 998 LTActPumpOvrTemp "FEFFFFFFFFFF3C1Eh";
BA_ "FlexKomSigStartPos" SG_ 998 LTActPumpOvrTemp 7;
BA_ "FlexKomSigName" SG_ 998 LTActPumpOvrTemp "BPCM_HV_Thermal_Status1";
BA_ "FlexKomSigLaenge" SG_ 998 LTActPumpOvrTemp 64;
BA_ "FlexKomSID" SG_ 998 LTActPumpOvrTemp 2130708620;
BA_ "FlexKomIsMotorola" SG_ 998 LTActPumpOvrTemp 1;
BA_ "FlexKomComment" SG_ 998 LTActPumpOvrTemp ".";
BA_ "GenSigStartValue" SG_ 998 LTActPumpPmpRPMTgt 255;
BA_ "GenSigSNA" SG_ 998 LTActPumpPmpRPMTgt "FFh";
BA_ "GenSigCycleTime" SG_ 998 LTActPumpPmpRPMTgt 100;
BA_ "FlexKomSigStartValue" SG_ 998 LTActPumpPmpRPMTgt "FEFFFFFFFFFF3C1Eh";
BA_ "FlexKomSigStartPos" SG_ 998 LTActPumpPmpRPMTgt 7;
BA_ "FlexKomSigName" SG_ 998 LTActPumpPmpRPMTgt "BPCM_HV_Thermal_Status1";
BA_ "FlexKomSigLaenge" SG_ 998 LTActPumpPmpRPMTgt 64;
BA_ "FlexKomSID" SG_ 998 LTActPumpPmpRPMTgt 2130708620;
BA_ "FlexKomIsMotorola" SG_ 998 LTActPumpPmpRPMTgt 1;
BA_ "FlexKomComment" SG_ 998 LTActPumpPmpRPMTgt ".";
BA_ "GenSigStartValue" SG_ 998 LTActPumpPostRunSts 7;
BA_ "GenSigSNA" SG_ 998 LTActPumpPostRunSts "7h";
BA_ "GenSigCycleTime" SG_ 998 LTActPumpPostRunSts 100;
BA_ "FlexKomSigStartValue" SG_ 998 LTActPumpPostRunSts "FEFFFFFFFFFF3C1Eh";
BA_ "FlexKomSigStartPos" SG_ 998 LTActPumpPostRunSts 7;
BA_ "FlexKomSigName" SG_ 998 LTActPumpPostRunSts "BPCM_HV_Thermal_Status1";
BA_ "FlexKomSigLaenge" SG_ 998 LTActPumpPostRunSts 64;
BA_ "FlexKomSID" SG_ 998 LTActPumpPostRunSts 2130708620;
BA_ "FlexKomIsMotorola" SG_ 998 LTActPumpPostRunSts 1;
BA_ "FlexKomComment" SG_ 998 LTActPumpPostRunSts ".";
BA_ "GenSigStartValue" SG_ 998 LTActPumpRPMAct 255;
BA_ "GenSigSNA" SG_ 998 LTActPumpRPMAct "FFh";
BA_ "GenSigCycleTime" SG_ 998 LTActPumpRPMAct 100;
BA_ "FlexKomSigStartValue" SG_ 998 LTActPumpRPMAct "FEFFFFFFFFFF3C1Eh";
BA_ "FlexKomSigStartPos" SG_ 998 LTActPumpRPMAct 7;
BA_ "FlexKomSigName" SG_ 998 LTActPumpRPMAct "BPCM_HV_Thermal_Status1";
BA_ "FlexKomSigLaenge" SG_ 998 LTActPumpRPMAct 64;
BA_ "FlexKomSID" SG_ 998 LTActPumpRPMAct 2130708620;
BA_ "FlexKomIsMotorola" SG_ 998 LTActPumpRPMAct 1;
BA_ "FlexKomComment" SG_ 998 LTActPumpRPMAct ".";
BA_ "GenSigSNA" SG_ 998 LTActPumpRespErr "0h";
BA_ "GenSigCycleTime" SG_ 998 LTActPumpRespErr 100;
BA_ "FlexKomSigStartValue" SG_ 998 LTActPumpRespErr "FEFFFFFFFFFF3C1Eh";
BA_ "FlexKomSigStartPos" SG_ 998 LTActPumpRespErr 7;
BA_ "FlexKomSigName" SG_ 998 LTActPumpRespErr "BPCM_HV_Thermal_Status1";
BA_ "FlexKomSigLaenge" SG_ 998 LTActPumpRespErr 64;
BA_ "FlexKomSID" SG_ 998 LTActPumpRespErr 2130708620;
BA_ "FlexKomIsMotorola" SG_ 998 LTActPumpRespErr 1;
BA_ "FlexKomComment" SG_ 998 LTActPumpRespErr ".";
BA_ "GenSigStartValue" SG_ 998 LTActPumpSuppVltErr 3;
BA_ "GenSigSNA" SG_ 998 LTActPumpSuppVltErr "3h";
BA_ "GenSigCycleTime" SG_ 998 LTActPumpSuppVltErr 100;
BA_ "FlexKomSigStartValue" SG_ 998 LTActPumpSuppVltErr "FEFFFFFFFFFF3C1Eh";
BA_ "FlexKomSigStartPos" SG_ 998 LTActPumpSuppVltErr 7;
BA_ "FlexKomSigName" SG_ 998 LTActPumpSuppVltErr "BPCM_HV_Thermal_Status1";
BA_ "FlexKomSigLaenge" SG_ 998 LTActPumpSuppVltErr 64;
BA_ "FlexKomSID" SG_ 998 LTActPumpSuppVltErr 2130708620;
BA_ "FlexKomIsMotorola" SG_ 998 LTActPumpSuppVltErr 1;
BA_ "FlexKomComment" SG_ 998 LTActPumpSuppVltErr ".";
BA_ "GenSigStartValue" SG_ 998 LTActPumpTemp 255;
BA_ "GenSigSNA" SG_ 998 LTActPumpTemp "FFh";
BA_ "GenSigCycleTime" SG_ 998 LTActPumpTemp 100;
BA_ "FlexKomSigStartValue" SG_ 998 LTActPumpTemp "FEFFFFFFFFFF3C1Eh";
BA_ "FlexKomSigStartPos" SG_ 998 LTActPumpTemp 7;
BA_ "FlexKomSigName" SG_ 998 LTActPumpTemp "BPCM_HV_Thermal_Status1";
BA_ "FlexKomSigLaenge" SG_ 998 LTActPumpTemp 64;
BA_ "FlexKomSID" SG_ 998 LTActPumpTemp 2130708620;
BA_ "FlexKomIsMotorola" SG_ 998 LTActPumpTemp 1;
BA_ "FlexKomComment" SG_ 998 LTActPumpTemp ".";
BA_ "GenSigStartValue" SG_ 998 LTActPumpVlt 255;
BA_ "GenSigSNA" SG_ 998 LTActPumpVlt "FFh";
BA_ "GenSigCycleTime" SG_ 998 LTActPumpVlt 100;
BA_ "FlexKomSigStartValue" SG_ 998 LTActPumpVlt "FEFFFFFFFFFF3C1Eh";
BA_ "FlexKomSigStartPos" SG_ 998 LTActPumpVlt 7;
BA_ "FlexKomSigName" SG_ 998 LTActPumpVlt "BPCM_HV_Thermal_Status1";
BA_ "FlexKomSigLaenge" SG_ 998 LTActPumpVlt 64;
BA_ "FlexKomSID" SG_ 998 LTActPumpVlt 2130708620;
BA_ "FlexKomIsMotorola" SG_ 998 LTActPumpVlt 1;
BA_ "FlexKomComment" SG_ 998 LTActPumpVlt ".";
BA_ "GenSigSNA" SG_ 854 HVBatMaxCellVltAlld "FFFh";
BA_ "GenSigCycleTime" SG_ 854 HVBatMaxCellVltAlld 250;
BA_ "FlexKomSigStartValue" SG_ 854 HVBatMaxCellVltAlld "0000480000000000h";
BA_ "FlexKomSigStartPos" SG_ 854 HVBatMaxCellVltAlld 7;
BA_ "FlexKomSigName" SG_ 854 HVBatMaxCellVltAlld "BPCM_HV_VoltLimits";
BA_ "FlexKomSigLaenge" SG_ 854 HVBatMaxCellVltAlld 64;
BA_ "FlexKomSID" SG_ 854 HVBatMaxCellVltAlld 2130708622;
BA_ "FlexKomIsMotorola" SG_ 854 HVBatMaxCellVltAlld 1;
BA_ "FlexKomComment" SG_ 854 HVBatMaxCellVltAlld ".";
BA_ "GenSigSNA" SG_ 854 HVBatMaxCellVltAlld_V "0h";
BA_ "GenSigCycleTime" SG_ 854 HVBatMaxCellVltAlld_V 250;
BA_ "FlexKomSigStartValue" SG_ 854 HVBatMaxCellVltAlld_V "0000480000000000h";
BA_ "FlexKomSigStartPos" SG_ 854 HVBatMaxCellVltAlld_V 7;
BA_ "FlexKomSigName" SG_ 854 HVBatMaxCellVltAlld_V "BPCM_HV_VoltLimits";
BA_ "FlexKomSigLaenge" SG_ 854 HVBatMaxCellVltAlld_V 64;
BA_ "FlexKomSID" SG_ 854 HVBatMaxCellVltAlld_V 2130708622;
BA_ "FlexKomIsMotorola" SG_ 854 HVBatMaxCellVltAlld_V 1;
BA_ "FlexKomComment" SG_ 854 HVBatMaxCellVltAlld_V ".";
BA_ "GenSigSNA" SG_ 854 HVBatMaxPkVltAllwd "1FFh";
BA_ "GenSigCycleTime" SG_ 854 HVBatMaxPkVltAllwd 250;
BA_ "FlexKomSigStartValue" SG_ 854 HVBatMaxPkVltAllwd "0000480000000000h";
BA_ "FlexKomSigStartPos" SG_ 854 HVBatMaxPkVltAllwd 7;
BA_ "FlexKomSigName" SG_ 854 HVBatMaxPkVltAllwd "BPCM_HV_VoltLimits";
BA_ "FlexKomSigLaenge" SG_ 854 HVBatMaxPkVltAllwd 64;
BA_ "FlexKomSID" SG_ 854 HVBatMaxPkVltAllwd 2130708622;
BA_ "FlexKomIsMotorola" SG_ 854 HVBatMaxPkVltAllwd 1;
BA_ "FlexKomComment" SG_ 854 HVBatMaxPkVltAllwd ".";
BA_ "GenSigSNA" SG_ 854 HVBatMaxPkVltAllwd_V "0h";
BA_ "GenSigCycleTime" SG_ 854 HVBatMaxPkVltAllwd_V 250;
BA_ "FlexKomSigStartValue" SG_ 854 HVBatMaxPkVltAllwd_V "0000480000000000h";
BA_ "FlexKomSigStartPos" SG_ 854 HVBatMaxPkVltAllwd_V 7;
BA_ "FlexKomSigName" SG_ 854 HVBatMaxPkVltAllwd_V "BPCM_HV_VoltLimits";
BA_ "FlexKomSigLaenge" SG_ 854 HVBatMaxPkVltAllwd_V 64;
BA_ "FlexKomSID" SG_ 854 HVBatMaxPkVltAllwd_V 2130708622;
BA_ "FlexKomIsMotorola" SG_ 854 HVBatMaxPkVltAllwd_V 1;
BA_ "FlexKomComment" SG_ 854 HVBatMaxPkVltAllwd_V ".";
BA_ "GenSigSNA" SG_ 854 HVBatMinCellVltAlld "FFFh";
BA_ "GenSigCycleTime" SG_ 854 HVBatMinCellVltAlld 250;
BA_ "FlexKomSigStartValue" SG_ 854 HVBatMinCellVltAlld "0000480000000000h";
BA_ "FlexKomSigStartPos" SG_ 854 HVBatMinCellVltAlld 7;
BA_ "FlexKomSigName" SG_ 854 HVBatMinCellVltAlld "BPCM_HV_VoltLimits";
BA_ "FlexKomSigLaenge" SG_ 854 HVBatMinCellVltAlld 64;
BA_ "FlexKomSID" SG_ 854 HVBatMinCellVltAlld 2130708622;
BA_ "FlexKomIsMotorola" SG_ 854 HVBatMinCellVltAlld 1;
BA_ "FlexKomComment" SG_ 854 HVBatMinCellVltAlld ".";
BA_ "GenSigSNA" SG_ 854 HVBatMinCellVltAlld_V "0h";
BA_ "GenSigCycleTime" SG_ 854 HVBatMinCellVltAlld_V 250;
BA_ "FlexKomSigStartValue" SG_ 854 HVBatMinCellVltAlld_V "0000480000000000h";
BA_ "FlexKomSigStartPos" SG_ 854 HVBatMinCellVltAlld_V 7;
BA_ "FlexKomSigName" SG_ 854 HVBatMinCellVltAlld_V "BPCM_HV_VoltLimits";
BA_ "FlexKomSigLaenge" SG_ 854 HVBatMinCellVltAlld_V 64;
BA_ "FlexKomSID" SG_ 854 HVBatMinCellVltAlld_V 2130708622;
BA_ "FlexKomIsMotorola" SG_ 854 HVBatMinCellVltAlld_V 1;
BA_ "FlexKomComment" SG_ 854 HVBatMinCellVltAlld_V ".";
BA_ "GenSigSNA" SG_ 854 HVBatMinPkVltAllwd "1FFh";
BA_ "GenSigCycleTime" SG_ 854 HVBatMinPkVltAllwd 250;
BA_ "FlexKomSigStartValue" SG_ 854 HVBatMinPkVltAllwd "0000480000000000h";
BA_ "FlexKomSigStartPos" SG_ 854 HVBatMinPkVltAllwd 7;
BA_ "FlexKomSigName" SG_ 854 HVBatMinPkVltAllwd "BPCM_HV_VoltLimits";
BA_ "FlexKomSigLaenge" SG_ 854 HVBatMinPkVltAllwd 64;
BA_ "FlexKomSID" SG_ 854 HVBatMinPkVltAllwd 2130708622;
BA_ "FlexKomIsMotorola" SG_ 854 HVBatMinPkVltAllwd 1;
BA_ "FlexKomComment" SG_ 854 HVBatMinPkVltAllwd ".";
BA_ "GenSigSNA" SG_ 854 HVBatMinPkVltAllwd_V "0h";
BA_ "GenSigCycleTime" SG_ 854 HVBatMinPkVltAllwd_V 250;
BA_ "FlexKomSigStartValue" SG_ 854 HVBatMinPkVltAllwd_V "0000480000000000h";
BA_ "FlexKomSigStartPos" SG_ 854 HVBatMinPkVltAllwd_V 7;
BA_ "FlexKomSigName" SG_ 854 HVBatMinPkVltAllwd_V "BPCM_HV_VoltLimits";
BA_ "FlexKomSigLaenge" SG_ 854 HVBatMinPkVltAllwd_V 64;
BA_ "FlexKomSID" SG_ 854 HVBatMinPkVltAllwd_V 2130708622;
BA_ "FlexKomIsMotorola" SG_ 854 HVBatMinPkVltAllwd_V 1;
BA_ "FlexKomComment" SG_ 854 HVBatMinPkVltAllwd_V ".";
BA_ "GenSigStartValue" SG_ 336 CRC_150h 255;
BA_ "GenSigSNA" SG_ 336 CRC_150h "FFh";
BA_ "GenSigCycleTime" SG_ 336 CRC_150h 10;
BA_ "FlexKomSigStartValue" SG_ 336 CRC_150h "A8000000000000FFh";
BA_ "FlexKomSigStartPos" SG_ 336 CRC_150h 7;
BA_ "FlexKomSigName" SG_ 336 CRC_150h "BPCM_MSG_01";
BA_ "FlexKomSigLaenge" SG_ 336 CRC_150h 64;
BA_ "FlexKomSID" SG_ 336 CRC_150h 2130708627;
BA_ "FlexKomIsMotorola" SG_ 336 CRC_150h 1;
BA_ "FlexKomComment" SG_ 336 CRC_150h ".";
BA_ "GenSigSNA" SG_ 336 HVBatCntctrOpn "0h";
BA_ "GenSigCycleTime" SG_ 336 HVBatCntctrOpn 10;
BA_ "FlexKomSigStartValue" SG_ 336 HVBatCntctrOpn "A8000000000000FFh";
BA_ "FlexKomSigStartPos" SG_ 336 HVBatCntctrOpn 7;
BA_ "FlexKomSigName" SG_ 336 HVBatCntctrOpn "BPCM_MSG_01";
BA_ "FlexKomSigLaenge" SG_ 336 HVBatCntctrOpn 64;
BA_ "FlexKomSID" SG_ 336 HVBatCntctrOpn 2130708627;
BA_ "FlexKomIsMotorola" SG_ 336 HVBatCntctrOpn 1;
BA_ "FlexKomComment" SG_ 336 HVBatCntctrOpn ".";
BA_ "GenSigSNA" SG_ 336 HVBatCntctrReq "0h";
BA_ "GenSigCycleTime" SG_ 336 HVBatCntctrReq 10;
BA_ "FlexKomSigStartValue" SG_ 336 HVBatCntctrReq "A8000000000000FFh";
BA_ "FlexKomSigStartPos" SG_ 336 HVBatCntctrReq 7;
BA_ "FlexKomSigName" SG_ 336 HVBatCntctrReq "BPCM_MSG_01";
BA_ "FlexKomSigLaenge" SG_ 336 HVBatCntctrReq 64;
BA_ "FlexKomSID" SG_ 336 HVBatCntctrReq 2130708627;
BA_ "FlexKomIsMotorola" SG_ 336 HVBatCntctrReq 1;
BA_ "FlexKomComment" SG_ 336 HVBatCntctrReq ".";
BA_ "RID" SG_ 336 HVBatCntctrStat "5079";
BA_ "GenSigSNA" SG_ 336 HVBatCntctrStat "7h";
BA_ "GenSigCycleTime" SG_ 336 HVBatCntctrStat 10;
BA_ "FlexKomSigStartValue" SG_ 336 HVBatCntctrStat "A8000000000000FFh";
BA_ "FlexKomSigStartPos" SG_ 336 HVBatCntctrStat 7;
BA_ "FlexKomSigName" SG_ 336 HVBatCntctrStat "BPCM_MSG_01";
BA_ "FlexKomSigLaenge" SG_ 336 HVBatCntctrStat 64;
BA_ "FlexKomSID" SG_ 336 HVBatCntctrStat 2130708627;
BA_ "FlexKomIsMotorola" SG_ 336 HVBatCntctrStat 1;
BA_ "FlexKomComment" SG_ 336 HVBatCntctrStat ".";
BA_ "GenSigSNA" SG_ 336 HVBatCrnt "0h";
BA_ "GenSigCycleTime" SG_ 336 HVBatCrnt 10;
BA_ "FlexKomSigStartValue" SG_ 336 HVBatCrnt "A8000000000000FFh";
BA_ "FlexKomSigStartPos" SG_ 336 HVBatCrnt 7;
BA_ "FlexKomSigName" SG_ 336 HVBatCrnt "BPCM_MSG_01";
BA_ "FlexKomSigLaenge" SG_ 336 HVBatCrnt 64;
BA_ "FlexKomSID" SG_ 336 HVBatCrnt 2130708627;
BA_ "FlexKomIsMotorola" SG_ 336 HVBatCrnt 1;
BA_ "FlexKomComment" SG_ 336 HVBatCrnt ".";
BA_ "GenSigSNA" SG_ 336 HVBatCrntV "0h";
BA_ "GenSigCycleTime" SG_ 336 HVBatCrntV 10;
BA_ "FlexKomSigStartValue" SG_ 336 HVBatCrntV "A8000000000000FFh";
BA_ "FlexKomSigStartPos" SG_ 336 HVBatCrntV 7;
BA_ "FlexKomSigName" SG_ 336 HVBatCrntV "BPCM_MSG_01";
BA_ "FlexKomSigLaenge" SG_ 336 HVBatCrntV 64;
BA_ "FlexKomSID" SG_ 336 HVBatCrntV 2130708627;
BA_ "FlexKomIsMotorola" SG_ 336 HVBatCrntV 1;
BA_ "FlexKomComment" SG_ 336 HVBatCrntV ".";
BA_ "GenSigSNA" SG_ 336 HVBatIntrlkStat "0h";
BA_ "GenSigCycleTime" SG_ 336 HVBatIntrlkStat 10;
BA_ "FlexKomSigStartValue" SG_ 336 HVBatIntrlkStat "A8000000000000FFh";
BA_ "FlexKomSigStartPos" SG_ 336 HVBatIntrlkStat 7;
BA_ "FlexKomSigName" SG_ 336 HVBatIntrlkStat "BPCM_MSG_01";
BA_ "FlexKomSigLaenge" SG_ 336 HVBatIntrlkStat 64;
BA_ "FlexKomSID" SG_ 336 HVBatIntrlkStat 2130708627;
BA_ "FlexKomIsMotorola" SG_ 336 HVBatIntrlkStat 1;
BA_ "FlexKomComment" SG_ 336 HVBatIntrlkStat ".";
BA_ "GenSigSNA" SG_ 336 HVBatIntrlk_InternalStat "0h";
BA_ "GenSigCycleTime" SG_ 336 HVBatIntrlk_InternalStat 10;
BA_ "FlexKomSigStartValue" SG_ 336 HVBatIntrlk_InternalStat "A8000000000000FFh";
BA_ "FlexKomSigStartPos" SG_ 336 HVBatIntrlk_InternalStat 7;
BA_ "FlexKomSigName" SG_ 336 HVBatIntrlk_InternalStat "BPCM_MSG_01";
BA_ "FlexKomSigLaenge" SG_ 336 HVBatIntrlk_InternalStat 64;
BA_ "FlexKomSID" SG_ 336 HVBatIntrlk_InternalStat 2130708627;
BA_ "FlexKomIsMotorola" SG_ 336 HVBatIntrlk_InternalStat 1;
BA_ "FlexKomComment" SG_ 336 HVBatIntrlk_InternalStat ".";
BA_ "GenSigSNA" SG_ 336 HVBatIsolStat "0h";
BA_ "GenSigCycleTime" SG_ 336 HVBatIsolStat 10;
BA_ "FlexKomSigStartValue" SG_ 336 HVBatIsolStat "A8000000000000FFh";
BA_ "FlexKomSigStartPos" SG_ 336 HVBatIsolStat 7;
BA_ "FlexKomSigName" SG_ 336 HVBatIsolStat "BPCM_MSG_01";
BA_ "FlexKomSigLaenge" SG_ 336 HVBatIsolStat 64;
BA_ "FlexKomSID" SG_ 336 HVBatIsolStat 2130708627;
BA_ "FlexKomIsMotorola" SG_ 336 HVBatIsolStat 1;
BA_ "FlexKomComment" SG_ 336 HVBatIsolStat ".";
BA_ "GenSigSNA" SG_ 336 HVBatRdy "0h";
BA_ "GenSigCycleTime" SG_ 336 HVBatRdy 10;
BA_ "FlexKomSigStartValue" SG_ 336 HVBatRdy "A8000000000000FFh";
BA_ "FlexKomSigStartPos" SG_ 336 HVBatRdy 7;
BA_ "FlexKomSigName" SG_ 336 HVBatRdy "BPCM_MSG_01";
BA_ "FlexKomSigLaenge" SG_ 336 HVBatRdy 64;
BA_ "FlexKomSID" SG_ 336 HVBatRdy 2130708627;
BA_ "FlexKomIsMotorola" SG_ 336 HVBatRdy 1;
BA_ "FlexKomComment" SG_ 336 HVBatRdy ".";
BA_ "GenSigSNA" SG_ 336 HVBatVlt "FFFh";
BA_ "GenSigCycleTime" SG_ 336 HVBatVlt 10;
BA_ "FlexKomSigStartValue" SG_ 336 HVBatVlt "A8000000000000FFh";
BA_ "FlexKomSigStartPos" SG_ 336 HVBatVlt 7;
BA_ "FlexKomSigName" SG_ 336 HVBatVlt "BPCM_MSG_01";
BA_ "FlexKomSigLaenge" SG_ 336 HVBatVlt 64;
BA_ "FlexKomSID" SG_ 336 HVBatVlt 2130708627;
BA_ "FlexKomIsMotorola" SG_ 336 HVBatVlt 1;
BA_ "FlexKomComment" SG_ 336 HVBatVlt ".";
BA_ "GenSigSNA" SG_ 336 HVBatVltV "0h";
BA_ "GenSigCycleTime" SG_ 336 HVBatVltV 10;
BA_ "FlexKomSigStartValue" SG_ 336 HVBatVltV "A8000000000000FFh";
BA_ "FlexKomSigStartPos" SG_ 336 HVBatVltV 7;
BA_ "FlexKomSigName" SG_ 336 HVBatVltV "BPCM_MSG_01";
BA_ "FlexKomSigLaenge" SG_ 336 HVBatVltV 64;
BA_ "FlexKomSID" SG_ 336 HVBatVltV 2130708627;
BA_ "FlexKomIsMotorola" SG_ 336 HVBatVltV 1;
BA_ "FlexKomComment" SG_ 336 HVBatVltV ".";
BA_ "GenSigSNA" SG_ 336 MC_150h "0h";
BA_ "GenSigCycleTime" SG_ 336 MC_150h 10;
BA_ "FlexKomSigStartValue" SG_ 336 MC_150h "A8000000000000FFh";
BA_ "FlexKomSigStartPos" SG_ 336 MC_150h 7;
BA_ "FlexKomSigName" SG_ 336 MC_150h "BPCM_MSG_01";
BA_ "FlexKomSigLaenge" SG_ 336 MC_150h 64;
BA_ "FlexKomSID" SG_ 336 MC_150h 2130708627;
BA_ "FlexKomIsMotorola" SG_ 336 MC_150h 1;
BA_ "FlexKomComment" SG_ 336 MC_150h ".";
BA_ "GenSigSNA" SG_ 336 PwrtrnHV_IsolStat "0h";
BA_ "GenSigCycleTime" SG_ 336 PwrtrnHV_IsolStat 10;
BA_ "FlexKomSigStartValue" SG_ 336 PwrtrnHV_IsolStat "A8000000000000FFh";
BA_ "FlexKomSigStartPos" SG_ 336 PwrtrnHV_IsolStat 7;
BA_ "FlexKomSigName" SG_ 336 PwrtrnHV_IsolStat "BPCM_MSG_01";
BA_ "FlexKomSigLaenge" SG_ 336 PwrtrnHV_IsolStat 64;
BA_ "FlexKomSID" SG_ 336 PwrtrnHV_IsolStat 2130708627;
BA_ "FlexKomIsMotorola" SG_ 336 PwrtrnHV_IsolStat 1;
BA_ "FlexKomComment" SG_ 336 PwrtrnHV_IsolStat ".";
BA_ "GenSigSNA" SG_ 544 HVBatCellVltAvg "1FFFh";
BA_ "GenSigCycleTime" SG_ 544 HVBatCellVltAvg 20;
BA_ "FlexKomSigStartValue" SG_ 544 HVBatCellVltAvg "0000000000000000h";
BA_ "FlexKomSigStartPos" SG_ 544 HVBatCellVltAvg 7;
BA_ "FlexKomSigName" SG_ 544 HVBatCellVltAvg "BPCM_MSG_02";
BA_ "FlexKomSigLaenge" SG_ 544 HVBatCellVltAvg 64;
BA_ "FlexKomSID" SG_ 544 HVBatCellVltAvg 2130708623;
BA_ "FlexKomIsMotorola" SG_ 544 HVBatCellVltAvg 1;
BA_ "FlexKomComment" SG_ 544 HVBatCellVltAvg ".";
BA_ "GenSigSNA" SG_ 544 HVBatCellVltAvgV "0h";
BA_ "GenSigCycleTime" SG_ 544 HVBatCellVltAvgV 20;
BA_ "FlexKomSigStartValue" SG_ 544 HVBatCellVltAvgV "0000000000000000h";
BA_ "FlexKomSigStartPos" SG_ 544 HVBatCellVltAvgV 7;
BA_ "FlexKomSigName" SG_ 544 HVBatCellVltAvgV "BPCM_MSG_02";
BA_ "FlexKomSigLaenge" SG_ 544 HVBatCellVltAvgV 64;
BA_ "FlexKomSID" SG_ 544 HVBatCellVltAvgV 2130708623;
BA_ "FlexKomIsMotorola" SG_ 544 HVBatCellVltAvgV 1;
BA_ "FlexKomComment" SG_ 544 HVBatCellVltAvgV ".";
BA_ "GenSigSNA" SG_ 544 HVBatCellVltMax "1FFFh";
BA_ "GenSigCycleTime" SG_ 544 HVBatCellVltMax 20;
BA_ "FlexKomSigStartValue" SG_ 544 HVBatCellVltMax "0000000000000000h";
BA_ "FlexKomSigStartPos" SG_ 544 HVBatCellVltMax 7;
BA_ "FlexKomSigName" SG_ 544 HVBatCellVltMax "BPCM_MSG_02";
BA_ "FlexKomSigLaenge" SG_ 544 HVBatCellVltMax 64;
BA_ "FlexKomSID" SG_ 544 HVBatCellVltMax 2130708623;
BA_ "FlexKomIsMotorola" SG_ 544 HVBatCellVltMax 1;
BA_ "FlexKomComment" SG_ 544 HVBatCellVltMax ".";
BA_ "GenSigSNA" SG_ 544 HVBatCellVltMaxV "0h";
BA_ "GenSigCycleTime" SG_ 544 HVBatCellVltMaxV 20;
BA_ "FlexKomSigStartValue" SG_ 544 HVBatCellVltMaxV "0000000000000000h";
BA_ "FlexKomSigStartPos" SG_ 544 HVBatCellVltMaxV 7;
BA_ "FlexKomSigName" SG_ 544 HVBatCellVltMaxV "BPCM_MSG_02";
BA_ "FlexKomSigLaenge" SG_ 544 HVBatCellVltMaxV 64;
BA_ "FlexKomSID" SG_ 544 HVBatCellVltMaxV 2130708623;
BA_ "FlexKomIsMotorola" SG_ 544 HVBatCellVltMaxV 1;
BA_ "FlexKomComment" SG_ 544 HVBatCellVltMaxV ".";
BA_ "GenSigSNA" SG_ 544 HVBatCellVltMin "1FFFh";
BA_ "GenSigCycleTime" SG_ 544 HVBatCellVltMin 20;
BA_ "FlexKomSigStartValue" SG_ 544 HVBatCellVltMin "0000000000000000h";
BA_ "FlexKomSigStartPos" SG_ 544 HVBatCellVltMin 7;
BA_ "FlexKomSigName" SG_ 544 HVBatCellVltMin "BPCM_MSG_02";
BA_ "FlexKomSigLaenge" SG_ 544 HVBatCellVltMin 64;
BA_ "FlexKomSID" SG_ 544 HVBatCellVltMin 2130708623;
BA_ "FlexKomIsMotorola" SG_ 544 HVBatCellVltMin 1;
BA_ "FlexKomComment" SG_ 544 HVBatCellVltMin ".";
BA_ "GenSigSNA" SG_ 544 HVBatCellVltMinV "0h";
BA_ "GenSigCycleTime" SG_ 544 HVBatCellVltMinV 20;
BA_ "FlexKomSigStartValue" SG_ 544 HVBatCellVltMinV "0000000000000000h";
BA_ "FlexKomSigStartPos" SG_ 544 HVBatCellVltMinV 7;
BA_ "FlexKomSigName" SG_ 544 HVBatCellVltMinV "BPCM_MSG_02";
BA_ "FlexKomSigLaenge" SG_ 544 HVBatCellVltMinV 64;
BA_ "FlexKomSID" SG_ 544 HVBatCellVltMinV 2130708623;
BA_ "FlexKomIsMotorola" SG_ 544 HVBatCellVltMinV 1;
BA_ "FlexKomComment" SG_ 544 HVBatCellVltMinV ".";
BA_ "GenSigSNA" SG_ 544 HVBatCell_NumMaxVlt "0h";
BA_ "GenSigCycleTime" SG_ 544 HVBatCell_NumMaxVlt 20;
BA_ "FlexKomSigStartValue" SG_ 544 HVBatCell_NumMaxVlt "0000000000000000h";
BA_ "FlexKomSigStartPos" SG_ 544 HVBatCell_NumMaxVlt 7;
BA_ "FlexKomSigName" SG_ 544 HVBatCell_NumMaxVlt "BPCM_MSG_02";
BA_ "FlexKomSigLaenge" SG_ 544 HVBatCell_NumMaxVlt 64;
BA_ "FlexKomSID" SG_ 544 HVBatCell_NumMaxVlt 2130708623;
BA_ "FlexKomIsMotorola" SG_ 544 HVBatCell_NumMaxVlt 1;
BA_ "FlexKomComment" SG_ 544 HVBatCell_NumMaxVlt ".";
BA_ "GenSigSNA" SG_ 544 HVBatCell_NumMinVlt "0h";
BA_ "GenSigCycleTime" SG_ 544 HVBatCell_NumMinVlt 20;
BA_ "FlexKomSigStartValue" SG_ 544 HVBatCell_NumMinVlt "0000000000000000h";
BA_ "FlexKomSigStartPos" SG_ 544 HVBatCell_NumMinVlt 7;
BA_ "FlexKomSigName" SG_ 544 HVBatCell_NumMinVlt "BPCM_MSG_02";
BA_ "FlexKomSigLaenge" SG_ 544 HVBatCell_NumMinVlt 64;
BA_ "FlexKomSID" SG_ 544 HVBatCell_NumMinVlt 2130708623;
BA_ "FlexKomIsMotorola" SG_ 544 HVBatCell_NumMinVlt 1;
BA_ "FlexKomComment" SG_ 544 HVBatCell_NumMinVlt ".";
BA_ "GenSigSNA" SG_ 544 HVBatMod_NumMaxVlt "0h";
BA_ "GenSigCycleTime" SG_ 544 HVBatMod_NumMaxVlt 20;
BA_ "FlexKomSigStartValue" SG_ 544 HVBatMod_NumMaxVlt "0000000000000000h";
BA_ "FlexKomSigStartPos" SG_ 544 HVBatMod_NumMaxVlt 7;
BA_ "FlexKomSigName" SG_ 544 HVBatMod_NumMaxVlt "BPCM_MSG_02";
BA_ "FlexKomSigLaenge" SG_ 544 HVBatMod_NumMaxVlt 64;
BA_ "FlexKomSID" SG_ 544 HVBatMod_NumMaxVlt 2130708623;
BA_ "FlexKomIsMotorola" SG_ 544 HVBatMod_NumMaxVlt 1;
BA_ "FlexKomComment" SG_ 544 HVBatMod_NumMaxVlt ".";
BA_ "GenSigSNA" SG_ 544 HVBatMod_NumMinVlt "0h";
BA_ "GenSigCycleTime" SG_ 544 HVBatMod_NumMinVlt 20;
BA_ "FlexKomSigStartValue" SG_ 544 HVBatMod_NumMinVlt "0000000000000000h";
BA_ "FlexKomSigStartPos" SG_ 544 HVBatMod_NumMinVlt 7;
BA_ "FlexKomSigName" SG_ 544 HVBatMod_NumMinVlt "BPCM_MSG_02";
BA_ "FlexKomSigLaenge" SG_ 544 HVBatMod_NumMinVlt 64;
BA_ "FlexKomSID" SG_ 544 HVBatMod_NumMinVlt 2130708623;
BA_ "FlexKomIsMotorola" SG_ 544 HVBatMod_NumMinVlt 1;
BA_ "FlexKomComment" SG_ 544 HVBatMod_NumMinVlt ".";
BA_ "GenSigSNA" SG_ 851 HVBatFull_Amp_Hr_Capacity "7FFh";
BA_ "GenSigCycleTime" SG_ 851 HVBatFull_Amp_Hr_Capacity 250;
BA_ "FlexKomSigStartValue" SG_ 851 HVBatFull_Amp_Hr_Capacity "0000000000000000h";
BA_ "FlexKomSigStartPos" SG_ 851 HVBatFull_Amp_Hr_Capacity 7;
BA_ "FlexKomSigName" SG_ 851 HVBatFull_Amp_Hr_Capacity "BPCM_MSG_03";
BA_ "FlexKomSigLaenge" SG_ 851 HVBatFull_Amp_Hr_Capacity 64;
BA_ "FlexKomSID" SG_ 851 HVBatFull_Amp_Hr_Capacity 2130708624;
BA_ "FlexKomIsMotorola" SG_ 851 HVBatFull_Amp_Hr_Capacity 1;
BA_ "FlexKomComment" SG_ 851 HVBatFull_Amp_Hr_Capacity ".";
BA_ "GenSigSNA" SG_ 851 HVBatFull_Amp_Hr_Capacity_V "0h";
BA_ "GenSigCycleTime" SG_ 851 HVBatFull_Amp_Hr_Capacity_V 250;
BA_ "FlexKomSigStartValue" SG_ 851 HVBatFull_Amp_Hr_Capacity_V "0000000000000000h";
BA_ "FlexKomSigStartPos" SG_ 851 HVBatFull_Amp_Hr_Capacity_V 7;
BA_ "FlexKomSigName" SG_ 851 HVBatFull_Amp_Hr_Capacity_V "BPCM_MSG_03";
BA_ "FlexKomSigLaenge" SG_ 851 HVBatFull_Amp_Hr_Capacity_V 64;
BA_ "FlexKomSID" SG_ 851 HVBatFull_Amp_Hr_Capacity_V 2130708624;
BA_ "FlexKomIsMotorola" SG_ 851 HVBatFull_Amp_Hr_Capacity_V 1;
BA_ "FlexKomComment" SG_ 851 HVBatFull_Amp_Hr_Capacity_V ".";
BA_ "GenSigSNA" SG_ 851 HVBatMaxChgCurrAlwd "0h";
BA_ "GenSigCycleTime" SG_ 851 HVBatMaxChgCurrAlwd 250;
BA_ "FlexKomSigStartValue" SG_ 851 HVBatMaxChgCurrAlwd "0000000000000000h";
BA_ "FlexKomSigStartPos" SG_ 851 HVBatMaxChgCurrAlwd 7;
BA_ "FlexKomSigName" SG_ 851 HVBatMaxChgCurrAlwd "BPCM_MSG_03";
BA_ "FlexKomSigLaenge" SG_ 851 HVBatMaxChgCurrAlwd 64;
BA_ "FlexKomSID" SG_ 851 HVBatMaxChgCurrAlwd 2130708624;
BA_ "FlexKomIsMotorola" SG_ 851 HVBatMaxChgCurrAlwd 1;
BA_ "FlexKomComment" SG_ 851 HVBatMaxChgCurrAlwd ".";
BA_ "GenSigSNA" SG_ 851 HVBatMaxChgCurrAlwd_V "0h";
BA_ "GenSigCycleTime" SG_ 851 HVBatMaxChgCurrAlwd_V 250;
BA_ "FlexKomSigStartValue" SG_ 851 HVBatMaxChgCurrAlwd_V "0000000000000000h";
BA_ "FlexKomSigStartPos" SG_ 851 HVBatMaxChgCurrAlwd_V 7;
BA_ "FlexKomSigName" SG_ 851 HVBatMaxChgCurrAlwd_V "BPCM_MSG_03";
BA_ "FlexKomSigLaenge" SG_ 851 HVBatMaxChgCurrAlwd_V 64;
BA_ "FlexKomSID" SG_ 851 HVBatMaxChgCurrAlwd_V 2130708624;
BA_ "FlexKomIsMotorola" SG_ 851 HVBatMaxChgCurrAlwd_V 1;
BA_ "FlexKomComment" SG_ 851 HVBatMaxChgCurrAlwd_V ".";
BA_ "GenSigSNA" SG_ 852 HVBatCell_Voltage_High_Thrsh "1FFFh";
BA_ "GenSigCycleTime" SG_ 852 HVBatCell_Voltage_High_Thrsh 250;
BA_ "FlexKomSigStartValue" SG_ 852 HVBatCell_Voltage_High_Thrsh "0000141400000000h";
BA_ "FlexKomSigStartPos" SG_ 852 HVBatCell_Voltage_High_Thrsh 7;
BA_ "FlexKomSigName" SG_ 852 HVBatCell_Voltage_High_Thrsh "BPCM_MSG_04";
BA_ "FlexKomSigLaenge" SG_ 852 HVBatCell_Voltage_High_Thrsh 64;
BA_ "FlexKomSID" SG_ 852 HVBatCell_Voltage_High_Thrsh 2130708625;
BA_ "FlexKomIsMotorola" SG_ 852 HVBatCell_Voltage_High_Thrsh 1;
BA_ "FlexKomComment" SG_ 852 HVBatCell_Voltage_High_Thrsh ".";
BA_ "GenSigSNA" SG_ 852 HVBatCell_Voltage_Low_Thrsh "1FFFh";
BA_ "GenSigCycleTime" SG_ 852 HVBatCell_Voltage_Low_Thrsh 250;
BA_ "FlexKomSigStartValue" SG_ 852 HVBatCell_Voltage_Low_Thrsh "0000141400000000h";
BA_ "FlexKomSigStartPos" SG_ 852 HVBatCell_Voltage_Low_Thrsh 7;
BA_ "FlexKomSigName" SG_ 852 HVBatCell_Voltage_Low_Thrsh "BPCM_MSG_04";
BA_ "FlexKomSigLaenge" SG_ 852 HVBatCell_Voltage_Low_Thrsh 64;
BA_ "FlexKomSID" SG_ 852 HVBatCell_Voltage_Low_Thrsh 2130708625;
BA_ "FlexKomIsMotorola" SG_ 852 HVBatCell_Voltage_Low_Thrsh 1;
BA_ "FlexKomComment" SG_ 852 HVBatCell_Voltage_Low_Thrsh ".";
BA_ "GenSigStartValue" SG_ 852 HVBatHighTempThrsh 20;
BA_ "GenSigSNA" SG_ 852 HVBatHighTempThrsh "FFh";
BA_ "GenSigCycleTime" SG_ 852 HVBatHighTempThrsh 250;
BA_ "FlexKomSigStartValue" SG_ 852 HVBatHighTempThrsh "0000141400000000h";
BA_ "FlexKomSigStartPos" SG_ 852 HVBatHighTempThrsh 7;
BA_ "FlexKomSigName" SG_ 852 HVBatHighTempThrsh "BPCM_MSG_04";
BA_ "FlexKomSigLaenge" SG_ 852 HVBatHighTempThrsh 64;
BA_ "FlexKomSID" SG_ 852 HVBatHighTempThrsh 2130708625;
BA_ "FlexKomIsMotorola" SG_ 852 HVBatHighTempThrsh 1;
BA_ "FlexKomComment" SG_ 852 HVBatHighTempThrsh ".";
BA_ "GenSigStartValue" SG_ 852 HVBatLowTempThrsh 20;
BA_ "GenSigSNA" SG_ 852 HVBatLowTempThrsh "FFh";
BA_ "GenSigCycleTime" SG_ 852 HVBatLowTempThrsh 250;
BA_ "FlexKomSigStartValue" SG_ 852 HVBatLowTempThrsh "0000141400000000h";
BA_ "FlexKomSigStartPos" SG_ 852 HVBatLowTempThrsh 7;
BA_ "FlexKomSigName" SG_ 852 HVBatLowTempThrsh "BPCM_MSG_04";
BA_ "FlexKomSigLaenge" SG_ 852 HVBatLowTempThrsh 64;
BA_ "FlexKomSID" SG_ 852 HVBatLowTempThrsh 2130708625;
BA_ "FlexKomIsMotorola" SG_ 852 HVBatLowTempThrsh 1;
BA_ "FlexKomComment" SG_ 852 HVBatLowTempThrsh ".";
BA_ "GenSigSNA" SG_ 1000 HEV_OnRq_BPCM "0h";
BA_ "GenSigCycleTime" SG_ 1000 HEV_OnRq_BPCM 100;
BA_ "FlexKomSigStartValue" SG_ 1000 HEV_OnRq_BPCM "0000000000000000h";
BA_ "FlexKomSigStartPos" SG_ 1000 HEV_OnRq_BPCM 7;
BA_ "FlexKomSigName" SG_ 1000 HEV_OnRq_BPCM "BPCM_MSG_05";
BA_ "FlexKomSigLaenge" SG_ 1000 HEV_OnRq_BPCM 64;
BA_ "FlexKomSID" SG_ 1000 HEV_OnRq_BPCM 2130708626;
BA_ "FlexKomIsMotorola" SG_ 1000 HEV_OnRq_BPCM 1;
BA_ "FlexKomComment" SG_ 1000 HEV_OnRq_BPCM ".";
BA_ "GenSigSNA" SG_ 1000 HVBatChargeStat "7h";
BA_ "GenSigCycleTime" SG_ 1000 HVBatChargeStat 100;
BA_ "FlexKomSigStartValue" SG_ 1000 HVBatChargeStat "0000000000000000h";
BA_ "FlexKomSigStartPos" SG_ 1000 HVBatChargeStat 7;
BA_ "FlexKomSigName" SG_ 1000 HVBatChargeStat "BPCM_MSG_05";
BA_ "FlexKomSigLaenge" SG_ 1000 HVBatChargeStat 64;
BA_ "FlexKomSID" SG_ 1000 HVBatChargeStat 2130708626;
BA_ "FlexKomIsMotorola" SG_ 1000 HVBatChargeStat 1;
BA_ "FlexKomComment" SG_ 1000 HVBatChargeStat ".";
BA_ "GenSigSNA" SG_ 1000 HVBatCntctrOpnTime "FFh";
BA_ "GenSigCycleTime" SG_ 1000 HVBatCntctrOpnTime 100;
BA_ "FlexKomSigStartValue" SG_ 1000 HVBatCntctrOpnTime "0000000000000000h";
BA_ "FlexKomSigStartPos" SG_ 1000 HVBatCntctrOpnTime 7;
BA_ "FlexKomSigName" SG_ 1000 HVBatCntctrOpnTime "BPCM_MSG_05";
BA_ "FlexKomSigLaenge" SG_ 1000 HVBatCntctrOpnTime 64;
BA_ "FlexKomSID" SG_ 1000 HVBatCntctrOpnTime 2130708626;
BA_ "FlexKomIsMotorola" SG_ 1000 HVBatCntctrOpnTime 1;
BA_ "FlexKomComment" SG_ 1000 HVBatCntctrOpnTime ".";
BA_ "GenSigSNA" SG_ 1000 HVBatPerWU12VChrg "0h";
BA_ "GenSigCycleTime" SG_ 1000 HVBatPerWU12VChrg 100;
BA_ "FlexKomSigStartValue" SG_ 1000 HVBatPerWU12VChrg "0000000000000000h";
BA_ "FlexKomSigStartPos" SG_ 1000 HVBatPerWU12VChrg 7;
BA_ "FlexKomSigName" SG_ 1000 HVBatPerWU12VChrg "BPCM_MSG_05";
BA_ "FlexKomSigLaenge" SG_ 1000 HVBatPerWU12VChrg 64;
BA_ "FlexKomSID" SG_ 1000 HVBatPerWU12VChrg 2130708626;
BA_ "FlexKomIsMotorola" SG_ 1000 HVBatPerWU12VChrg 1;
BA_ "FlexKomComment" SG_ 1000 HVBatPerWU12VChrg ".";
BA_ "GenSigSNA" SG_ 1000 HVBatPerWUThermal "0h";
BA_ "GenSigCycleTime" SG_ 1000 HVBatPerWUThermal 100;
BA_ "FlexKomSigStartValue" SG_ 1000 HVBatPerWUThermal "0000000000000000h";
BA_ "FlexKomSigStartPos" SG_ 1000 HVBatPerWUThermal 7;
BA_ "FlexKomSigName" SG_ 1000 HVBatPerWUThermal "BPCM_MSG_05";
BA_ "FlexKomSigLaenge" SG_ 1000 HVBatPerWUThermal 64;
BA_ "FlexKomSID" SG_ 1000 HVBatPerWUThermal 2130708626;
BA_ "FlexKomIsMotorola" SG_ 1000 HVBatPerWUThermal 1;
BA_ "FlexKomComment" SG_ 1000 HVBatPerWUThermal ".";
BA_ "GenSigSNA" SG_ 1000 HVBatPerWakeUp "0h";
BA_ "GenSigCycleTime" SG_ 1000 HVBatPerWakeUp 100;
BA_ "FlexKomSigStartValue" SG_ 1000 HVBatPerWakeUp "0000000000000000h";
BA_ "FlexKomSigStartPos" SG_ 1000 HVBatPerWakeUp 7;
BA_ "FlexKomSigName" SG_ 1000 HVBatPerWakeUp "BPCM_MSG_05";
BA_ "FlexKomSigLaenge" SG_ 1000 HVBatPerWakeUp 64;
BA_ "FlexKomSID" SG_ 1000 HVBatPerWakeUp 2130708626;
BA_ "FlexKomIsMotorola" SG_ 1000 HVBatPerWakeUp 1;
BA_ "FlexKomComment" SG_ 1000 HVBatPerWakeUp ".";
BA_ "GenSigSNA" SG_ 1000 HVBatSleepTime "FFh";
BA_ "GenSigCycleTime" SG_ 1000 HVBatSleepTime 100;
BA_ "FlexKomSigStartValue" SG_ 1000 HVBatSleepTime "0000000000000000h";
BA_ "FlexKomSigStartPos" SG_ 1000 HVBatSleepTime 7;
BA_ "FlexKomSigName" SG_ 1000 HVBatSleepTime "BPCM_MSG_05";
BA_ "FlexKomSigLaenge" SG_ 1000 HVBatSleepTime 64;
BA_ "FlexKomSID" SG_ 1000 HVBatSleepTime 2130708626;
BA_ "FlexKomIsMotorola" SG_ 1000 HVBatSleepTime 1;
BA_ "FlexKomComment" SG_ 1000 HVBatSleepTime ".";
BA_ "RID" SG_ 1000 MIL_OnRq_BPCM "5078";
BA_ "GenSigSNA" SG_ 1000 MIL_OnRq_BPCM "0h";
BA_ "GenSigCycleTime" SG_ 1000 MIL_OnRq_BPCM 100;
BA_ "FlexKomSigStartValue" SG_ 1000 MIL_OnRq_BPCM "0000000000000000h";
BA_ "FlexKomSigStartPos" SG_ 1000 MIL_OnRq_BPCM 7;
BA_ "FlexKomSigName" SG_ 1000 MIL_OnRq_BPCM "BPCM_MSG_05";
BA_ "FlexKomSigLaenge" SG_ 1000 MIL_OnRq_BPCM 64;
BA_ "FlexKomSID" SG_ 1000 MIL_OnRq_BPCM 2130708626;
BA_ "FlexKomIsMotorola" SG_ 1000 MIL_OnRq_BPCM 1;
BA_ "FlexKomComment" SG_ 1000 MIL_OnRq_BPCM ".";
BA_ "GenSigSNA" SG_ 1000 Prchrgpnltytimer "0h";
BA_ "GenSigCycleTime" SG_ 1000 Prchrgpnltytimer 100;
BA_ "FlexKomSigStartValue" SG_ 1000 Prchrgpnltytimer "0000000000000000h";
BA_ "FlexKomSigStartPos" SG_ 1000 Prchrgpnltytimer 7;
BA_ "FlexKomSigName" SG_ 1000 Prchrgpnltytimer "BPCM_MSG_05";
BA_ "FlexKomSigLaenge" SG_ 1000 Prchrgpnltytimer 64;
BA_ "FlexKomSID" SG_ 1000 Prchrgpnltytimer 2130708626;
BA_ "FlexKomIsMotorola" SG_ 1000 Prchrgpnltytimer 1;
BA_ "FlexKomComment" SG_ 1000 Prchrgpnltytimer ".";
BA_ "GenSigSNA" SG_ 337 HVBat_Real_Time_Clock "FFFFFFFFh";
BA_ "GenSigCycleTime" SG_ 337 HVBat_Real_Time_Clock 1000;
BA_ "FlexKomSigStartValue" SG_ 337 HVBat_Real_Time_Clock "0000000000000000h";
BA_ "FlexKomSigStartPos" SG_ 337 HVBat_Real_Time_Clock 7;
BA_ "FlexKomSigName" SG_ 337 HVBat_Real_Time_Clock "BPCM_PHEV_2";
BA_ "FlexKomSigLaenge" SG_ 337 HVBat_Real_Time_Clock 64;
BA_ "FlexKomSID" SG_ 337 HVBat_Real_Time_Clock 2130708810;
BA_ "FlexKomIsMotorola" SG_ 337 HVBat_Real_Time_Clock 1;
BA_ "FlexKomComment" SG_ 337 HVBat_Real_Time_Clock ".";
BA_ "GenSigSNA" SG_ 337 HVBat_Real_Time_Clock_V "0h";
BA_ "GenSigCycleTime" SG_ 337 HVBat_Real_Time_Clock_V 1000;
BA_ "FlexKomSigStartValue" SG_ 337 HVBat_Real_Time_Clock_V "0000000000000000h";
BA_ "FlexKomSigStartPos" SG_ 337 HVBat_Real_Time_Clock_V 7;
BA_ "FlexKomSigName" SG_ 337 HVBat_Real_Time_Clock_V "BPCM_PHEV_2";
BA_ "FlexKomSigLaenge" SG_ 337 HVBat_Real_Time_Clock_V 64;
BA_ "FlexKomSID" SG_ 337 HVBat_Real_Time_Clock_V 2130708810;
BA_ "FlexKomIsMotorola" SG_ 337 HVBat_Real_Time_Clock_V 1;
BA_ "FlexKomComment" SG_ 337 HVBat_Real_Time_Clock_V ".";
BA_ "GenSigSNA" SG_ 786 HBCNC_BOT "0h";
BA_ "GenSigCycleTime" SG_ 786 HBCNC_BOT 1000;
BA_ "FlexKomSigStartValue" SG_ 786 HBCNC_BOT "0000000000000000h";
BA_ "FlexKomSigStartPos" SG_ 786 HBCNC_BOT 7;
BA_ "FlexKomSigName" SG_ 786 HBCNC_BOT "BP_CNC_CO";
BA_ "FlexKomSigLaenge" SG_ 786 HBCNC_BOT 64;
BA_ "FlexKomSID" SG_ 786 HBCNC_BOT 2130708722;
BA_ "FlexKomIsMotorola" SG_ 786 HBCNC_BOT 1;
BA_ "FlexKomComment" SG_ 786 HBCNC_BOT ".";
BA_ "GenSigSNA" SG_ 786 HBCNC_BUT "0h";
BA_ "GenSigCycleTime" SG_ 786 HBCNC_BUT 1000;
BA_ "FlexKomSigStartValue" SG_ 786 HBCNC_BUT "0000000000000000h";
BA_ "FlexKomSigStartPos" SG_ 786 HBCNC_BUT 7;
BA_ "FlexKomSigName" SG_ 786 HBCNC_BUT "BP_CNC_CO";
BA_ "FlexKomSigLaenge" SG_ 786 HBCNC_BUT 64;
BA_ "FlexKomSID" SG_ 786 HBCNC_BUT 2130708722;
BA_ "FlexKomIsMotorola" SG_ 786 HBCNC_BUT 1;
BA_ "FlexKomComment" SG_ 786 HBCNC_BUT ".";
BA_ "GenSigSNA" SG_ 786 HBCO_CellVltMax_High "0h";
BA_ "GenSigCycleTime" SG_ 786 HBCO_CellVltMax_High 1000;
BA_ "FlexKomSigStartValue" SG_ 786 HBCO_CellVltMax_High "0000000000000000h";
BA_ "FlexKomSigStartPos" SG_ 786 HBCO_CellVltMax_High 7;
BA_ "FlexKomSigName" SG_ 786 HBCO_CellVltMax_High "BP_CNC_CO";
BA_ "FlexKomSigLaenge" SG_ 786 HBCO_CellVltMax_High 64;
BA_ "FlexKomSID" SG_ 786 HBCO_CellVltMax_High 2130708722;
BA_ "FlexKomIsMotorola" SG_ 786 HBCO_CellVltMax_High 1;
BA_ "FlexKomComment" SG_ 786 HBCO_CellVltMax_High ".";
BA_ "GenSigSNA" SG_ 786 HBCO_CellVltMin_Low "0h";
BA_ "GenSigCycleTime" SG_ 786 HBCO_CellVltMin_Low 1000;
BA_ "FlexKomSigStartValue" SG_ 786 HBCO_CellVltMin_Low "0000000000000000h";
BA_ "FlexKomSigStartPos" SG_ 786 HBCO_CellVltMin_Low 7;
BA_ "FlexKomSigName" SG_ 786 HBCO_CellVltMin_Low "BP_CNC_CO";
BA_ "FlexKomSigLaenge" SG_ 786 HBCO_CellVltMin_Low 64;
BA_ "FlexKomSID" SG_ 786 HBCO_CellVltMin_Low 2130708722;
BA_ "FlexKomIsMotorola" SG_ 786 HBCO_CellVltMin_Low 1;
BA_ "FlexKomComment" SG_ 786 HBCO_CellVltMin_Low ".";
BA_ "GenSigStartValue" SG_ 832 DateTmDay 255;
BA_ "GenSigSNA" SG_ 832 DateTmDay "FFh";
BA_ "GenSigCycleTime" SG_ 832 DateTmDay 1000;
BA_ "FlexKomSigStartValue" SG_ 832 DateTmDay "FFFFFFFFh";
BA_ "FlexKomSigStartPos" SG_ 832 DateTmDay 31;
BA_ "FlexKomSigName" SG_ 832 DateTmDay "DATE";
BA_ "FlexKomSigLaenge" SG_ 832 DateTmDay 32;
BA_ "FlexKomSID" SG_ 832 DateTmDay 2130707077;
BA_ "FlexKomIsMotorola" SG_ 832 DateTmDay 1;
BA_ "FlexKomComment" SG_ 832 DateTmDay "DATE";
BA_ "GenSigStartValue" SG_ 832 DateTmFormat 7;
BA_ "GenSigSNA" SG_ 832 DateTmFormat "7h";
BA_ "GenSigCycleTime" SG_ 832 DateTmFormat 1000;
BA_ "FlexKomSigStartValue" SG_ 832 DateTmFormat "07h";
BA_ "FlexKomSigStartPos" SG_ 832 DateTmFormat 58;
BA_ "FlexKomSigName" SG_ 832 DateTmFormat "DateTmFormat";
BA_ "FlexKomSigLaenge" SG_ 832 DateTmFormat 3;
BA_ "FlexKomSID" SG_ 832 DateTmFormat 2130707403;
BA_ "FlexKomIsMotorola" SG_ 832 DateTmFormat 1;
BA_ "FlexKomComment" SG_ 832 DateTmFormat "Date and Time Format";
BA_ "GenSigStartValue" SG_ 832 DateTmHour 255;
BA_ "GenSigSNA" SG_ 832 DateTmHour "FFh";
BA_ "GenSigCycleTime" SG_ 832 DateTmHour 1000;
BA_ "FlexKomSigStartValue" SG_ 832 DateTmHour "FFFFFFh";
BA_ "FlexKomSigStartPos" SG_ 832 DateTmHour 7;
BA_ "FlexKomSigName" SG_ 832 DateTmHour "Clock";
BA_ "FlexKomSigLaenge" SG_ 832 DateTmHour 24;
BA_ "FlexKomSID" SG_ 832 DateTmHour 2130706830;
BA_ "FlexKomIsMotorola" SG_ 832 DateTmHour 1;
BA_ "FlexKomComment" SG_ 832 DateTmHour "Time of day clock";
BA_ "GenSigStartValue" SG_ 832 DateTmMinute 255;
BA_ "GenSigSNA" SG_ 832 DateTmMinute "FFh";
BA_ "GenSigCycleTime" SG_ 832 DateTmMinute 1000;
BA_ "FlexKomSigStartValue" SG_ 832 DateTmMinute "FFFFFFh";
BA_ "FlexKomSigStartPos" SG_ 832 DateTmMinute 7;
BA_ "FlexKomSigName" SG_ 832 DateTmMinute "Clock";
BA_ "FlexKomSigLaenge" SG_ 832 DateTmMinute 24;
BA_ "FlexKomSID" SG_ 832 DateTmMinute 2130706830;
BA_ "FlexKomIsMotorola" SG_ 832 DateTmMinute 1;
BA_ "FlexKomComment" SG_ 832 DateTmMinute "Time of day clock";
BA_ "GenSigStartValue" SG_ 832 DateTmMonth 255;
BA_ "GenSigSNA" SG_ 832 DateTmMonth "FFh";
BA_ "GenSigCycleTime" SG_ 832 DateTmMonth 1000;
BA_ "FlexKomSigStartValue" SG_ 832 DateTmMonth "FFFFFFFFh";
BA_ "FlexKomSigStartPos" SG_ 832 DateTmMonth 31;
BA_ "FlexKomSigName" SG_ 832 DateTmMonth "DATE";
BA_ "FlexKomSigLaenge" SG_ 832 DateTmMonth 32;
BA_ "FlexKomSID" SG_ 832 DateTmMonth 2130707077;
BA_ "FlexKomIsMotorola" SG_ 832 DateTmMonth 1;
BA_ "FlexKomComment" SG_ 832 DateTmMonth "DATE";
BA_ "GenSigStartValue" SG_ 832 DateTmSec 255;
BA_ "GenSigSNA" SG_ 832 DateTmSec "FFh";
BA_ "GenSigCycleTime" SG_ 832 DateTmSec 1000;
BA_ "FlexKomSigStartValue" SG_ 832 DateTmSec "FFFFFFh";
BA_ "FlexKomSigStartPos" SG_ 832 DateTmSec 7;
BA_ "FlexKomSigName" SG_ 832 DateTmSec "Clock";
BA_ "FlexKomSigLaenge" SG_ 832 DateTmSec 24;
BA_ "FlexKomSID" SG_ 832 DateTmSec 2130706830;
BA_ "FlexKomIsMotorola" SG_ 832 DateTmSec 1;
BA_ "FlexKomComment" SG_ 832 DateTmSec "Time of day clock";
BA_ "GenSigStartValue" SG_ 832 DateTmYear 65535;
BA_ "GenSigSNA" SG_ 832 DateTmYear "FFFFh";
BA_ "GenSigCycleTime" SG_ 832 DateTmYear 1000;
BA_ "FlexKomSigStartValue" SG_ 832 DateTmYear "FFFFFFFFh";
BA_ "FlexKomSigStartPos" SG_ 832 DateTmYear 31;
BA_ "FlexKomSigName" SG_ 832 DateTmYear "DATE";
BA_ "FlexKomSigLaenge" SG_ 832 DateTmYear 32;
BA_ "FlexKomSID" SG_ 832 DateTmYear 2130707077;
BA_ "FlexKomIsMotorola" SG_ 832 DateTmYear 1;
BA_ "FlexKomComment" SG_ 832 DateTmYear "DATE";
BA_ "GenSigStartValue" SG_ 500 CRC_DAS_A3 255;
BA_ "GenSigSNA" SG_ 500 CRC_DAS_A3 "FFh";
BA_ "GenSigCycleTime" SG_ 500 CRC_DAS_A3 20;
BA_ "FlexKomSigStartValue" SG_ 500 CRC_DAS_A3 "1FFF0CCB000000FFh";
BA_ "FlexKomSigStartPos" SG_ 500 CRC_DAS_A3 7;
BA_ "FlexKomSigName" SG_ 500 CRC_DAS_A3 "DAS_A3_PKT";
BA_ "FlexKomSigLaenge" SG_ 500 CRC_DAS_A3 64;
BA_ "FlexKomSID" SG_ 500 CRC_DAS_A3 1043;
BA_ "FlexKomIsMotorola" SG_ 500 CRC_DAS_A3 1;
BA_ "FlexKomComment" SG_ 500 CRC_DAS_A3 "DAS_A3_PKT";
BA_ "GenSigSNA" SG_ 500 MC_DAS_A3 "0h";
BA_ "GenSigCycleTime" SG_ 500 MC_DAS_A3 20;
BA_ "FlexKomSigStartValue" SG_ 500 MC_DAS_A3 "1FFF0CCB000000FFh";
BA_ "FlexKomSigStartPos" SG_ 500 MC_DAS_A3 7;
BA_ "FlexKomSigName" SG_ 500 MC_DAS_A3 "DAS_A3_PKT";
BA_ "FlexKomSigLaenge" SG_ 500 MC_DAS_A3 64;
BA_ "FlexKomSID" SG_ 500 MC_DAS_A3 1043;
BA_ "FlexKomIsMotorola" SG_ 500 MC_DAS_A3 1;
BA_ "FlexKomComment" SG_ 500 MC_DAS_A3 "DAS_A3_PKT";
BA_ "GenSigStartValue" SG_ 499 MC_DAS_A3_A 15;
BA_ "GenSigStartValue" SG_ 499 CRC_DAS_A3_A 255;
BA_ "GenSigSNA" SG_ 499 DAS_EPB_APPLY_RQ "0h";
BA_ "GenSigCycleTime" SG_ 499 DAS_EPB_APPLY_RQ 10;
BA_ "FlexKomSigStartValue" SG_ 499 DAS_EPB_APPLY_RQ "000000FF000000FFh";
BA_ "FlexKomSigStartPos" SG_ 499 DAS_EPB_APPLY_RQ 7;
BA_ "FlexKomSigName" SG_ 499 DAS_EPB_APPLY_RQ "DAS_A5_PKT";
BA_ "FlexKomSigLaenge" SG_ 499 DAS_EPB_APPLY_RQ 64;
BA_ "FlexKomSID" SG_ 499 DAS_EPB_APPLY_RQ 2333;
BA_ "FlexKomIsMotorola" SG_ 499 DAS_EPB_APPLY_RQ 1;
BA_ "FlexKomComment" SG_ 499 DAS_EPB_APPLY_RQ "DAS_A5 Packet";
BA_ "GenSigSNA" SG_ 499 DAS_EPB_RELSE_RQ "0h";
BA_ "GenSigCycleTime" SG_ 499 DAS_EPB_RELSE_RQ 10;
BA_ "FlexKomSigStartValue" SG_ 499 DAS_EPB_RELSE_RQ "000000FF000000FFh";
BA_ "FlexKomSigStartPos" SG_ 499 DAS_EPB_RELSE_RQ 7;
BA_ "FlexKomSigName" SG_ 499 DAS_EPB_RELSE_RQ "DAS_A5_PKT";
BA_ "FlexKomSigLaenge" SG_ 499 DAS_EPB_RELSE_RQ 64;
BA_ "FlexKomSID" SG_ 499 DAS_EPB_RELSE_RQ 2333;
BA_ "FlexKomIsMotorola" SG_ 499 DAS_EPB_RELSE_RQ 1;
BA_ "FlexKomComment" SG_ 499 DAS_EPB_RELSE_RQ "DAS_A5 Packet";
BA_ "GenSigSNA" SG_ 499 LFC_Request "0h";
BA_ "GenSigCycleTime" SG_ 499 LFC_Request 10;
BA_ "FlexKomSigStartValue" SG_ 499 LFC_Request "1FFF0CCB000000FFh";
BA_ "FlexKomSigStartPos" SG_ 499 LFC_Request 7;
BA_ "FlexKomSigName" SG_ 499 LFC_Request "DAS_A3_PKT";
BA_ "FlexKomSigLaenge" SG_ 499 LFC_Request 64;
BA_ "FlexKomSID" SG_ 499 LFC_Request 9001;
BA_ "FlexKomIsMotorola" SG_ 499 LFC_Request 1;
BA_ "FlexKomComment" SG_ 499 LFC_Request "DAS_A3_PKT";
BA_ "GenSigCycleTime" SG_ 499 LFC_Request_Type 10;
BA_ "FlexKomSigStartValue" SG_ 499 LFC_Request_Type "0400000000FFh";
BA_ "FlexKomSigStartPos" SG_ 499 LFC_Request_Type 7;
BA_ "FlexKomSigName" SG_ 499 LFC_Request_Type "RHSC_SDS_SteerControl_Pkt";
BA_ "FlexKomSigLaenge" SG_ 499 LFC_Request_Type 48;
BA_ "FlexKomSID" SG_ 499 LFC_Request_Type 9213;
BA_ "FlexKomIsMotorola" SG_ 499 LFC_Request_Type 1;
BA_ "FlexKomComment" SG_ 499 LFC_Request_Type "LFC_Pkt";
BA_ "GenSigCycleTime" SG_ 499 RHSC_OpenLoopBraking_Rq 10;
BA_ "FlexKomSigStartValue" SG_ 499 RHSC_OpenLoopBraking_Rq "0400000000FFh";
BA_ "FlexKomSigStartPos" SG_ 499 RHSC_OpenLoopBraking_Rq 7;
BA_ "FlexKomSigName" SG_ 499 RHSC_OpenLoopBraking_Rq "RHSC_SDS_SteerControl_Pkt";
BA_ "FlexKomSigLaenge" SG_ 499 RHSC_OpenLoopBraking_Rq 48;
BA_ "FlexKomSID" SG_ 499 RHSC_OpenLoopBraking_Rq 9213;
BA_ "FlexKomIsMotorola" SG_ 499 RHSC_OpenLoopBraking_Rq 1;
BA_ "FlexKomComment" SG_ 499 RHSC_OpenLoopBraking_Rq "LFC_Pkt";
BA_ "GenSigSNA" SG_ 499 SDS_Engaged_State "3h";
BA_ "GenSigCycleTime" SG_ 499 SDS_Engaged_State 10;
BA_ "FlexKomSigStartValue" SG_ 499 SDS_Engaged_State "000000FF000000FFh";
BA_ "FlexKomSigStartPos" SG_ 499 SDS_Engaged_State 7;
BA_ "FlexKomSigName" SG_ 499 SDS_Engaged_State "DAS_A5_PKT";
BA_ "FlexKomSigLaenge" SG_ 499 SDS_Engaged_State 64;
BA_ "FlexKomSID" SG_ 499 SDS_Engaged_State 2333;
BA_ "FlexKomIsMotorola" SG_ 499 SDS_Engaged_State 1;
BA_ "FlexKomComment" SG_ 499 SDS_Engaged_State "DAS_A5 Packet";
BA_ "GenSigStartValue" SG_ 625 CRC_DAS_A5 255;
BA_ "GenSigSNA" SG_ 625 CRC_DAS_A5 "FFh";
BA_ "GenSigCycleTime" SG_ 625 CRC_DAS_A5 20;
BA_ "FlexKomSigStartValue" SG_ 625 CRC_DAS_A5 "000000FF000000FFh";
BA_ "FlexKomSigStartPos" SG_ 625 CRC_DAS_A5 7;
BA_ "FlexKomSigName" SG_ 625 CRC_DAS_A5 "DAS_A5_PKT";
BA_ "FlexKomSigLaenge" SG_ 625 CRC_DAS_A5 64;
BA_ "FlexKomSID" SG_ 625 CRC_DAS_A5 2333;
BA_ "FlexKomIsMotorola" SG_ 625 CRC_DAS_A5 1;
BA_ "FlexKomComment" SG_ 625 CRC_DAS_A5 "DAS_A5 Packet";
BA_ "GenSigSNA" SG_ 625 DAS_EPB_APPLY_RQ "0h";
BA_ "GenSigCycleTime" SG_ 625 DAS_EPB_APPLY_RQ 20;
BA_ "FlexKomSigStartValue" SG_ 625 DAS_EPB_APPLY_RQ "000000FF000000FFh";
BA_ "FlexKomSigStartPos" SG_ 625 DAS_EPB_APPLY_RQ 7;
BA_ "FlexKomSigName" SG_ 625 DAS_EPB_APPLY_RQ "DAS_A5_PKT";
BA_ "FlexKomSigLaenge" SG_ 625 DAS_EPB_APPLY_RQ 64;
BA_ "FlexKomSID" SG_ 625 DAS_EPB_APPLY_RQ 2333;
BA_ "FlexKomIsMotorola" SG_ 625 DAS_EPB_APPLY_RQ 1;
BA_ "FlexKomComment" SG_ 625 DAS_EPB_APPLY_RQ "DAS_A5 Packet";
BA_ "GenSigSNA" SG_ 625 DAS_EPB_RELSE_RQ "0h";
BA_ "GenSigCycleTime" SG_ 625 DAS_EPB_RELSE_RQ 20;
BA_ "FlexKomSigStartValue" SG_ 625 DAS_EPB_RELSE_RQ "000000FF000000FFh";
BA_ "FlexKomSigStartPos" SG_ 625 DAS_EPB_RELSE_RQ 7;
BA_ "FlexKomSigName" SG_ 625 DAS_EPB_RELSE_RQ "DAS_A5_PKT";
BA_ "FlexKomSigLaenge" SG_ 625 DAS_EPB_RELSE_RQ 64;
BA_ "FlexKomSID" SG_ 625 DAS_EPB_RELSE_RQ 2333;
BA_ "FlexKomIsMotorola" SG_ 625 DAS_EPB_RELSE_RQ 1;
BA_ "FlexKomComment" SG_ 625 DAS_EPB_RELSE_RQ "DAS_A5 Packet";
BA_ "GenSigSNA" SG_ 625 MC_DAS_A5 "0h";
BA_ "GenSigCycleTime" SG_ 625 MC_DAS_A5 20;
BA_ "FlexKomSigStartValue" SG_ 625 MC_DAS_A5 "000000FF000000FFh";
BA_ "FlexKomSigStartPos" SG_ 625 MC_DAS_A5 7;
BA_ "FlexKomSigName" SG_ 625 MC_DAS_A5 "DAS_A5_PKT";
BA_ "FlexKomSigLaenge" SG_ 625 MC_DAS_A5 64;
BA_ "FlexKomSID" SG_ 625 MC_DAS_A5 2333;
BA_ "FlexKomIsMotorola" SG_ 625 MC_DAS_A5 1;
BA_ "FlexKomComment" SG_ 625 MC_DAS_A5 "DAS_A5 Packet";
BA_ "GenSigSNA" SG_ 625 SDS_Engaged_State "3h";
BA_ "GenSigCycleTime" SG_ 625 SDS_Engaged_State 20;
BA_ "FlexKomSigStartValue" SG_ 625 SDS_Engaged_State "000000FF000000FFh";
BA_ "FlexKomSigStartPos" SG_ 625 SDS_Engaged_State 7;
BA_ "FlexKomSigName" SG_ 625 SDS_Engaged_State "DAS_A5_PKT";
BA_ "FlexKomSigLaenge" SG_ 625 SDS_Engaged_State 64;
BA_ "FlexKomSID" SG_ 625 SDS_Engaged_State 2333;
BA_ "FlexKomIsMotorola" SG_ 625 SDS_Engaged_State 1;
BA_ "FlexKomComment" SG_ 625 SDS_Engaged_State "DAS_A5 Packet";
BA_ "RID" SG_ 2015 DG_RQ_GLOBAL "5026";
BA_ "GenSigSNA" SG_ 2015 DG_RQ_GLOBAL "0h";
BA_ "FlexKomSigStartValue" SG_ 2015 DG_RQ_GLOBAL "0000000000000000h";
BA_ "FlexKomSigStartPos" SG_ 2015 DG_RQ_GLOBAL 7;
BA_ "FlexKomSigName" SG_ 2015 DG_RQ_GLOBAL "DG_RQ_GLOBAL";
BA_ "FlexKomSigLaenge" SG_ 2015 DG_RQ_GLOBAL 64;
BA_ "FlexKomSID" SG_ 2015 DG_RQ_GLOBAL 2130706824;
BA_ "FlexKomIsMotorola" SG_ 2015 DG_RQ_GLOBAL 1;
BA_ "FlexKomComment" SG_ 2015 DG_RQ_GLOBAL "Diagnostic-Request";
BA_ "RID" SG_ 1089 DG_RQ_GLOBAL_UDS "2075";
BA_ "GenSigSNA" SG_ 1089 DG_RQ_GLOBAL_UDS "0h";
BA_ "FlexKomSigStartValue" SG_ 1089 DG_RQ_GLOBAL_UDS "0000000000000000h";
BA_ "FlexKomSigStartPos" SG_ 1089 DG_RQ_GLOBAL_UDS 7;
BA_ "FlexKomSigName" SG_ 1089 DG_RQ_GLOBAL_UDS "DG_RQ_GLOBAL_UDS";
BA_ "FlexKomSigLaenge" SG_ 1089 DG_RQ_GLOBAL_UDS 64;
BA_ "FlexKomSID" SG_ 1089 DG_RQ_GLOBAL_UDS 2130706825;
BA_ "FlexKomIsMotorola" SG_ 1089 DG_RQ_GLOBAL_UDS 1;
BA_ "FlexKomComment" SG_ 1089 DG_RQ_GLOBAL_UDS "Diagnostic-Request";
BA_ "RID" SG_ 1900 D_RQ_AHCP "2903";
BA_ "GenSigSNA" SG_ 1900 D_RQ_AHCP "0h";
BA_ "FlexKomSigStartValue" SG_ 1900 D_RQ_AHCP "0000000000000000h";
BA_ "FlexKomSigStartPos" SG_ 1900 D_RQ_AHCP 7;
BA_ "FlexKomSigName" SG_ 1900 D_RQ_AHCP "D_RQ_AHCP";
BA_ "FlexKomSigLaenge" SG_ 1900 D_RQ_AHCP 64;
BA_ "FlexKomSID" SG_ 1900 D_RQ_AHCP 2130708949;
BA_ "FlexKomIsMotorola" SG_ 1900 D_RQ_AHCP 1;
BA_ "FlexKomComment" SG_ 1900 D_RQ_AHCP "Diagnostic-Request";
BA_ "RID" SG_ 1898 D_RQ_APM "2060";
BA_ "GenSigSNA" SG_ 1898 D_RQ_APM "0h";
BA_ "FlexKomSigStartValue" SG_ 1898 D_RQ_APM "0000000000000000h";
BA_ "FlexKomSigStartPos" SG_ 1898 D_RQ_APM 7;
BA_ "FlexKomSigName" SG_ 1898 D_RQ_APM "D_RQ_APM";
BA_ "FlexKomSigLaenge" SG_ 1898 D_RQ_APM 64;
BA_ "FlexKomSID" SG_ 1898 D_RQ_APM 2130708556;
BA_ "FlexKomIsMotorola" SG_ 1898 D_RQ_APM 1;
BA_ "FlexKomComment" SG_ 1898 D_RQ_APM "Diagnostic-Request";
BA_ "RID" SG_ 2023 D_RQ_BPCM "2073";
BA_ "GenSigSNA" SG_ 2023 D_RQ_BPCM "0h";
BA_ "FlexKomSigStartValue" SG_ 2023 D_RQ_BPCM "0000000000000000h";
BA_ "FlexKomSigStartPos" SG_ 2023 D_RQ_BPCM 7;
BA_ "FlexKomSigName" SG_ 2023 D_RQ_BPCM "D_RQ_BPCM";
BA_ "FlexKomSigLaenge" SG_ 2023 D_RQ_BPCM 64;
BA_ "FlexKomSID" SG_ 2023 D_RQ_BPCM 2130708570;
BA_ "FlexKomIsMotorola" SG_ 2023 D_RQ_BPCM 1;
BA_ "FlexKomComment" SG_ 2023 D_RQ_BPCM "Diagnostic-Request";
BA_ "RID" SG_ 1899 D_RQ_EAC "2074";
BA_ "GenSigSNA" SG_ 1899 D_RQ_EAC "0h";
BA_ "FlexKomSigStartValue" SG_ 1899 D_RQ_EAC "0000000000000000h";
BA_ "FlexKomSigStartPos" SG_ 1899 D_RQ_EAC 7;
BA_ "FlexKomSigName" SG_ 1899 D_RQ_EAC "D_RQ_EAC";
BA_ "FlexKomSigLaenge" SG_ 1899 D_RQ_EAC 64;
BA_ "FlexKomSID" SG_ 1899 D_RQ_EAC 2130708558;
BA_ "FlexKomIsMotorola" SG_ 1899 D_RQ_EAC 1;
BA_ "FlexKomComment" SG_ 1899 D_RQ_EAC "Diagnostic-Request";
BA_ "RID" SG_ 1902 D_RQ_OBCM "2080";
BA_ "GenSigSNA" SG_ 1902 D_RQ_OBCM "0h";
BA_ "FlexKomSigStartValue" SG_ 1902 D_RQ_OBCM "0000000000000000h";
BA_ "FlexKomSigStartPos" SG_ 1902 D_RQ_OBCM 7;
BA_ "FlexKomSigName" SG_ 1902 D_RQ_OBCM "D_RQ_OBCM";
BA_ "FlexKomSigLaenge" SG_ 1902 D_RQ_OBCM 64;
BA_ "FlexKomSID" SG_ 1902 D_RQ_OBCM 2130708568;
BA_ "FlexKomIsMotorola" SG_ 1902 D_RQ_OBCM 1;
BA_ "FlexKomComment" SG_ 1902 D_RQ_OBCM "Diagnostic-Request";
BA_ "RID" SG_ 1260 D_RS_AHCP "2904";
BA_ "GenSigSNA" SG_ 1260 D_RS_AHCP "0h";
BA_ "FlexKomSigStartValue" SG_ 1260 D_RS_AHCP "0000000000000000h";
BA_ "FlexKomSigStartPos" SG_ 1260 D_RS_AHCP 7;
BA_ "FlexKomSigName" SG_ 1260 D_RS_AHCP "D_RS_AHCP";
BA_ "FlexKomSigLaenge" SG_ 1260 D_RS_AHCP 64;
BA_ "FlexKomSID" SG_ 1260 D_RS_AHCP 2130708950;
BA_ "FlexKomIsMotorola" SG_ 1260 D_RS_AHCP 1;
BA_ "FlexKomComment" SG_ 1260 D_RS_AHCP "Diagnostic-Response";
BA_ "RID" SG_ 1258 D_RS_APM "2062";
BA_ "GenSigSNA" SG_ 1258 D_RS_APM "0h";
BA_ "FlexKomSigStartValue" SG_ 1258 D_RS_APM "0000000000000000h";
BA_ "FlexKomSigStartPos" SG_ 1258 D_RS_APM 7;
BA_ "FlexKomSigName" SG_ 1258 D_RS_APM "D_RS_APM";
BA_ "FlexKomSigLaenge" SG_ 1258 D_RS_APM 64;
BA_ "FlexKomSID" SG_ 1258 D_RS_APM 2130708557;
BA_ "FlexKomIsMotorola" SG_ 1258 D_RS_APM 1;
BA_ "FlexKomComment" SG_ 1258 D_RS_APM "Diagnostic-Response";
BA_ "RID" SG_ 2031 D_RS_BPCM "2079";
BA_ "GenSigSNA" SG_ 2031 D_RS_BPCM "0h";
BA_ "FlexKomSigStartValue" SG_ 2031 D_RS_BPCM "0000000000000000h";
BA_ "FlexKomSigStartPos" SG_ 2031 D_RS_BPCM 7;
BA_ "FlexKomSigName" SG_ 2031 D_RS_BPCM "D_RS_BPCM";
BA_ "FlexKomSigLaenge" SG_ 2031 D_RS_BPCM 64;
BA_ "FlexKomSID" SG_ 2031 D_RS_BPCM 2130708571;
BA_ "FlexKomIsMotorola" SG_ 2031 D_RS_BPCM 1;
BA_ "FlexKomComment" SG_ 2031 D_RS_BPCM "Diagnostic-Response";
BA_ "RID" SG_ 1259 D_RS_EAC "2066";
BA_ "GenSigSNA" SG_ 1259 D_RS_EAC "0h";
BA_ "FlexKomSigStartValue" SG_ 1259 D_RS_EAC "0000000000000000h";
BA_ "FlexKomSigStartPos" SG_ 1259 D_RS_EAC 7;
BA_ "FlexKomSigName" SG_ 1259 D_RS_EAC "D_RS_EAC";
BA_ "FlexKomSigLaenge" SG_ 1259 D_RS_EAC 64;
BA_ "FlexKomSID" SG_ 1259 D_RS_EAC 2130708559;
BA_ "FlexKomIsMotorola" SG_ 1259 D_RS_EAC 1;
BA_ "FlexKomComment" SG_ 1259 D_RS_EAC "Diagnostic-Response";
BA_ "RID" SG_ 1262 D_RS_OBCM "2067";
BA_ "GenSigSNA" SG_ 1262 D_RS_OBCM "0h";
BA_ "FlexKomSigStartValue" SG_ 1262 D_RS_OBCM "0000000000000000h";
BA_ "FlexKomSigStartPos" SG_ 1262 D_RS_OBCM 7;
BA_ "FlexKomSigName" SG_ 1262 D_RS_OBCM "D_RS_OBCM";
BA_ "FlexKomSigLaenge" SG_ 1262 D_RS_OBCM 64;
BA_ "FlexKomSID" SG_ 1262 D_RS_OBCM 2130708569;
BA_ "FlexKomIsMotorola" SG_ 1262 D_RS_OBCM 1;
BA_ "FlexKomComment" SG_ 1262 D_RS_OBCM "Diagnostic-Response";
BA_ "GenSigSNA" SG_ 793 CompElecCurr "0h";
BA_ "GenSigCycleTime" SG_ 793 CompElecCurr 100;
BA_ "FlexKomSigStartValue" SG_ 793 CompElecCurr "000000000000h";
BA_ "FlexKomSigStartPos" SG_ 793 CompElecCurr 7;
BA_ "FlexKomSigName" SG_ 793 CompElecCurr "EAC_STATUS1";
BA_ "FlexKomSigLaenge" SG_ 793 CompElecCurr 48;
BA_ "FlexKomSID" SG_ 793 CompElecCurr 2130708631;
BA_ "FlexKomIsMotorola" SG_ 793 CompElecCurr 1;
BA_ "FlexKomComment" SG_ 793 CompElecCurr ".";
BA_ "GenSigSNA" SG_ 793 CompElecCurrV "0h";
BA_ "GenSigCycleTime" SG_ 793 CompElecCurrV 100;
BA_ "FlexKomSigStartValue" SG_ 793 CompElecCurrV "000000000000h";
BA_ "FlexKomSigStartPos" SG_ 793 CompElecCurrV 7;
BA_ "FlexKomSigName" SG_ 793 CompElecCurrV "EAC_STATUS1";
BA_ "FlexKomSigLaenge" SG_ 793 CompElecCurrV 48;
BA_ "FlexKomSID" SG_ 793 CompElecCurrV 2130708631;
BA_ "FlexKomIsMotorola" SG_ 793 CompElecCurrV 1;
BA_ "FlexKomComment" SG_ 793 CompElecCurrV ".";
BA_ "GenSigSNA" SG_ 793 CompElecPwr "0h";
BA_ "GenSigCycleTime" SG_ 793 CompElecPwr 100;
BA_ "FlexKomSigStartValue" SG_ 793 CompElecPwr "000000000000h";
BA_ "FlexKomSigStartPos" SG_ 793 CompElecPwr 7;
BA_ "FlexKomSigName" SG_ 793 CompElecPwr "EAC_STATUS1";
BA_ "FlexKomSigLaenge" SG_ 793 CompElecPwr 48;
BA_ "FlexKomSID" SG_ 793 CompElecPwr 2130708631;
BA_ "FlexKomIsMotorola" SG_ 793 CompElecPwr 1;
BA_ "FlexKomComment" SG_ 793 CompElecPwr ".";
BA_ "GenSigSNA" SG_ 793 CompElecPwrV "0h";
BA_ "GenSigCycleTime" SG_ 793 CompElecPwrV 100;
BA_ "FlexKomSigStartValue" SG_ 793 CompElecPwrV "000000000000h";
BA_ "FlexKomSigStartPos" SG_ 793 CompElecPwrV 7;
BA_ "FlexKomSigName" SG_ 793 CompElecPwrV "EAC_STATUS1";
BA_ "FlexKomSigLaenge" SG_ 793 CompElecPwrV 48;
BA_ "FlexKomSID" SG_ 793 CompElecPwrV 2130708631;
BA_ "FlexKomIsMotorola" SG_ 793 CompElecPwrV 1;
BA_ "FlexKomComment" SG_ 793 CompElecPwrV ".";
BA_ "GenSigSNA" SG_ 793 CompFltStat "Fh";
BA_ "GenSigCycleTime" SG_ 793 CompFltStat 100;
BA_ "FlexKomSigStartValue" SG_ 793 CompFltStat "000000000000h";
BA_ "FlexKomSigStartPos" SG_ 793 CompFltStat 7;
BA_ "FlexKomSigName" SG_ 793 CompFltStat "EAC_STATUS1";
BA_ "FlexKomSigLaenge" SG_ 793 CompFltStat 48;
BA_ "FlexKomSID" SG_ 793 CompFltStat 2130708631;
BA_ "FlexKomIsMotorola" SG_ 793 CompFltStat 1;
BA_ "FlexKomComment" SG_ 793 CompFltStat ".";
BA_ "GenSigSNA" SG_ 793 CompSpd "3FFFh";
BA_ "GenSigCycleTime" SG_ 793 CompSpd 100;
BA_ "FlexKomSigStartValue" SG_ 793 CompSpd "000000000000h";
BA_ "FlexKomSigStartPos" SG_ 793 CompSpd 7;
BA_ "FlexKomSigName" SG_ 793 CompSpd "EAC_STATUS1";
BA_ "FlexKomSigLaenge" SG_ 793 CompSpd 48;
BA_ "FlexKomSID" SG_ 793 CompSpd 2130708631;
BA_ "FlexKomIsMotorola" SG_ 793 CompSpd 1;
BA_ "FlexKomComment" SG_ 793 CompSpd ".";
BA_ "GenSigSNA" SG_ 793 CompSpdIncrReq "0h";
BA_ "GenSigCycleTime" SG_ 793 CompSpdIncrReq 100;
BA_ "FlexKomSigStartValue" SG_ 793 CompSpdIncrReq "000000000000h";
BA_ "FlexKomSigStartPos" SG_ 793 CompSpdIncrReq 7;
BA_ "FlexKomSigName" SG_ 793 CompSpdIncrReq "EAC_STATUS1";
BA_ "FlexKomSigLaenge" SG_ 793 CompSpdIncrReq 48;
BA_ "FlexKomSID" SG_ 793 CompSpdIncrReq 2130708631;
BA_ "FlexKomIsMotorola" SG_ 793 CompSpdIncrReq 1;
BA_ "FlexKomComment" SG_ 793 CompSpdIncrReq ".";
BA_ "GenSigSNA" SG_ 793 CompSpdV "0h";
BA_ "GenSigCycleTime" SG_ 793 CompSpdV 100;
BA_ "FlexKomSigStartValue" SG_ 793 CompSpdV "000000000000h";
BA_ "FlexKomSigStartPos" SG_ 793 CompSpdV 7;
BA_ "FlexKomSigName" SG_ 793 CompSpdV "EAC_STATUS1";
BA_ "FlexKomSigLaenge" SG_ 793 CompSpdV 48;
BA_ "FlexKomSID" SG_ 793 CompSpdV 2130708631;
BA_ "FlexKomIsMotorola" SG_ 793 CompSpdV 1;
BA_ "FlexKomComment" SG_ 793 CompSpdV ".";
BA_ "RID" SG_ 793 CompStat "3587";
BA_ "GenSigSNA" SG_ 793 CompStat "Fh";
BA_ "GenSigCycleTime" SG_ 793 CompStat 100;
BA_ "FlexKomSigStartValue" SG_ 793 CompStat "000000000000h";
BA_ "FlexKomSigStartPos" SG_ 793 CompStat 7;
BA_ "FlexKomSigName" SG_ 793 CompStat "EAC_STATUS1";
BA_ "FlexKomSigLaenge" SG_ 793 CompStat 48;
BA_ "FlexKomSID" SG_ 793 CompStat 2130708631;
BA_ "FlexKomIsMotorola" SG_ 793 CompStat 1;
BA_ "FlexKomComment" SG_ 793 CompStat ".";
VAL_ 565 APM_IdcHvFdbk 4095 "SNA" ;
VAL_ 565 APM_IdcLvFdbk 4095 "SNA" ;
VAL_ 565 APM_OperModeStatus 0 "IDLE" 1 "Buck_CV" 2 "Buck_CC" 3 "Buck_CP" 4 "Buck_Special" 5 "Boost" 6 "Precharge" 7 "Discharge" 8 "Failure" 15 "SNA" ;
VAL_ 565 APM_VdcHvFdbk 4095 "SNA" ;
VAL_ 565 APM_VdcLvFdbk 4095 "SNA" ;
VAL_ 853 APM_TempColdPlate 254 "Failure" 255 "SNA" ;
VAL_ 853 APM_TempOne 254 "Failure" 255 "SNA" ;
VAL_ 853 APM_TempTwo 254 "Failure" 255 "SNA" ;
VAL_ 853 APM_UtilPctOfDCDC 127 "SNA" ;
VAL_ 672 APM_Battfeedvolt 4095 "SNA" ;
VAL_ 672 APM_DeratingModeStatus 0 "No_derating" 1 "Derating_Initialized" 2 "Derating_Initialization_Failure" 3 "Derating_Mode" 7 "SNA" ;
VAL_ 672 APM_DeratingPower 63 "SNA" ;
VAL_ 672 APM_DeratingReason 0 "No_Derating" 1 "high_temp_De_rating" 2 "low_temp_De_rating" 3 "OverVolt_HV_De_rating" 4 "lowVolt_HV_De_rating" 5 "highVolt_LV_De_rating" 6 "lowVolt_LV_De_rating" 7 "highCurrent_LV_Current_limit" 8 "internal_HD_fail_De_rating" 9 "high_current_HV_De_rating" 31 "SNA" ;
VAL_ 672 APM_VdcLvSetPFdbk 255 "SNA" ;
VAL_ 855 APM_EstPwrLoss 255 "SNA" ;
VAL_ 855 APM_FailureModeStatus 0 "No_Failure" 1 "Failure_mode" 2 "Retry" 3 "SNA" ;
VAL_ 855 APM_FailureReason 0 "No_Failure" 1 "Fail_high_voltage_at_HV" 2 "Fail_low_voltage_at_HV" 3 "Fail_high_voltage_at_LV" 4 "Fail_low_voltage_at_LV" 5 "Fail_high_PCB_temperature" 6 "Fail_high_DBC_temperature" 7 "Fail_high_cur_at_LV" 8 "Fail_high_curr_at_HV" 9 "Fail_short_circ_at_LV" 10 "Fail_short_circ_at_HV" 11 "Fail_open_circ_at_LV" 12 "Fail_open_circ_at_HV" 13 "Fail_init_failure" 14 "Fail_wake_up_issue" 15 "Fail_internal_hardware" 16 "Fail_bat_feed_low" 17 "Fail_bat_feed_high_" 18 "Fail_Aux_OV" 19 "Fail_Aux_UV" 20 "Fail_HVIL_fault" 21 "Fail_LOC_with_HCP" 22 "Fail_LOC_with_BPCM" 23 "Fail_cont_not_closed" 24 "Fail_SBC_fault" 25 "Memory_Fail" 26 "Implausible_data_from_HCP" 27 "Implausible_data_from_BPCM" 28 "CAN_bus_off" 29 "Fail_temp_diff_is_high" 30 "Fail_high_voltage_diff_is_high" 31 "Fail_for_other_reason" 32 "LOC_ORC" 33 "Implausible_data_ORC" 63 "SNA" ;
VAL_ 855 APM_HvVsetPFdbk 511 "SNA" ;
VAL_ 855 APM_IdcHvSetPFdbk 1023 "SNA" ;
VAL_ 855 APM_Internal_Mode 0 "Not_in_Buck" 1 "Current_control" 2 "voltage_control" 3 "Default_current_set_point" 4 "Default_voltage_set_point" 7 "SNA" ;
VAL_ 855 APM_LvIsetPFdbk 511 "SNA" ;
VAL_ 674 APM_CurrentOperTime 65535 "SNA" ;
VAL_ 674 APM_InputPower 1023 "SNA" ;
VAL_ 674 APM_OutputPower 1023 "SNA" ;
VAL_ 674 APM_TotalOperTime 65535 "SNA" ;
VAL_ 674 APM_WUStatus 0 "No_Wake_up" 1 "APM_awake" 2 "APM_wake_up_failure" 3 "SNA" ;
VAL_ 674 APM_WUStatus_Reason 0 "No_Wake_up" 1 "Wake_up_1" 2 "Wake_up_2" 3 "SNA" ;
VAL_ 168 CmndAxleTorqPrdtd 16383 "SNA" ;
VAL_ 168 CmndAxleTorqRespTyp 0 "Inactive" 1 "PL" 2 "MR" ;
VAL_ 168 DrvrIntndedAxleTorq 16383 "SNA" ;
VAL_ 168 DrvrIntndedAxleTorqRaw 16383 "SNA" ;
VAL_ 168 DrvrIntndedAxleTorqRawV 0 "Valid" 1 "Not_Valid" ;
VAL_ 168 DrvrIntndedAxleTorqV 0 "Valid" 1 "Not_Valid" ;
VAL_ 708 HVBatBalComplete 0 "INCOMPLETE" 1 "COMPLETE" ;
VAL_ 708 HVBatBalMd 0 "NoBalancing" 1 "Balancing" ;
VAL_ 710 HVBatMax_Cell_Dischrg_Imped 4095 "SNA" ;
VAL_ 710 HVBatMax_Cell_Dischrg_Imped_V 0 "Valid" 1 "Not_Valid" ;
VAL_ 710 HVBatMin_Cell_Dischrg_Imped 4095 "SNA" ;
VAL_ 710 HVBatMin_Cell_Dischrg_Imped_V 0 "Valid" 1 "Not_Valid" ;
VAL_ 707 HVBatOCV_Ave_Cell_Voltage 4095 "SNA" ;
VAL_ 707 HVBatOCV_Ave_Cell_Voltage_V 0 "Valid" 1 "Not_Valid" ;
VAL_ 707 HVBatOCV_Max_Cell_Voltage 4095 "SNA" ;
VAL_ 707 HVBatOCV_Max_Cell_Voltage_V 0 "Valid" 1 "Not_Valid" ;
VAL_ 707 HVBatOCV_Min_Cell_Voltage 4095 "SNA" ;
VAL_ 707 HVBatOCV_Min_Cell_Voltage_V 0 "Valid" 1 "Not_Valid" ;
VAL_ 773 HVBatChrgPow10sec 255 "SNA" ;
VAL_ 773 HVBatChrgPow10secV 0 "Valid" 1 "Not_Valid" ;
VAL_ 773 HVBatChrgPow2sec 255 "SNA" ;
VAL_ 773 HVBatChrgPow2secV 0 "Valid" 1 "Not_Valid" ;
VAL_ 773 HVBatChrgPow30sec 255 "SNA" ;
VAL_ 773 HVBatChrgPow30secV 0 "Valid" 1 "Not_Valid" ;
VAL_ 773 HVBatDischrgPow10sec 255 "SNA" ;
VAL_ 773 HVBatDischrgPow10secV 0 "Valid" 1 "Not_Valid" ;
VAL_ 773 HVBatDischrgPow2sec 255 "SNA" ;
VAL_ 773 HVBatDischrgPow2secV 0 "Valid" 1 "Not_Valid" ;
VAL_ 773 HVBatDischrgPow30sec 255 "SNA" ;
VAL_ 773 HVBatDischrgPow30secV 0 "Valid" 1 "Not_Valid" ;
VAL_ 773 HVBatPwrLim_On_BPCM 0 "FALSE" 1 "TRUE" ;
VAL_ 774 HVBatSOH 255 "SNA" ;
VAL_ 774 HVBatSOHLow 255 "SNA" ;
VAL_ 774 OBCCoolTempIn 255 "SNA" ;
VAL_ 775 HVBatClgInletTemp 255 "SNA" ;
VAL_ 775 HVBatClgInletTempV 0 "Valid" 1 "Not_Valid" ;
VAL_ 775 HVBatClgOutletTemp 255 "SNA" ;
VAL_ 775 HVBatClgOutletTempV 0 "Valid" 1 "Not_Valid" ;
VAL_ 775 HVBatModTempAvg 255 "SNA" ;
VAL_ 775 HVBatModTempMax 255 "SNA" ;
VAL_ 775 HVBatModTempMaxV 0 "Valid" 1 "Not_Valid" ;
VAL_ 775 HVBatModTempMin 255 "SNA" ;
VAL_ 775 HVBatModTempMinV 0 "Valid" 1 "Not_Valid" ;
VAL_ 775 HVBatModlTempAvgV 0 "Valid" 1 "Not_Valid" ;
VAL_ 998 LTActPumpCrnt 255 "SNA" ;
VAL_ 998 LTActPumpDeblock 0 "INACTIVE" 1 "ACTIVE" 3 "SNA" ;
VAL_ 998 LTActPumpDryRun 0 "NO_DRY" 1 "DRY" 3 "SNA" ;
VAL_ 998 LTActPumpLimpHmAnON 0 "FALSE" 1 "TRUE" 3 "SNA" ;
VAL_ 998 LTActPumpMontrngRPM 0 "TRUE" 1 "FALSE" 3 "SNA" ;
VAL_ 998 LTActPumpOvrTemp 0 "NO_OVER" 1 "OVER" 3 "SNA" ;
VAL_ 998 LTActPumpPmpRPMTgt 255 "SNA" ;
VAL_ 998 LTActPumpPostRunSts 0 "NO_POST_RUNNING" 1 "PR_1x" 2 "PR_1y" 3 "PR_2x" 4 "PR_2y" 5 "PR_3x" 6 "PR_3y" 7 "SNA" ;
VAL_ 998 LTActPumpRPMAct 255 "SNA" ;
VAL_ 998 LTActPumpSuppVltErr 0 "IN" 1 "OUT" 3 "SNA" ;
VAL_ 998 LTActPumpTemp 255 "SNA" ;
VAL_ 998 LTActPumpVlt 255 "SNA" ;
VAL_ 854 HVBatMaxCellVltAlld 4095 "SNA" ;
VAL_ 854 HVBatMaxCellVltAlld_V 0 "Valid" 1 "Not_Valid" ;
VAL_ 854 HVBatMaxPkVltAllwd 511 "SNA" ;
VAL_ 854 HVBatMaxPkVltAllwd_V 0 "Valid" 1 "Not_Valid" ;
VAL_ 854 HVBatMinCellVltAlld 4095 "SNA" ;
VAL_ 854 HVBatMinCellVltAlld_V 0 "Valid" 1 "Not_Valid" ;
VAL_ 854 HVBatMinPkVltAllwd 511 "SNA" ;
VAL_ 854 HVBatMinPkVltAllwd_V 0 "Valid" 1 "Not_Valid" ;
VAL_ 336 HVBatCntctrOpn 0 "FALSE" 1 "TRUE" ;
VAL_ 336 HVBatCntctrReq 0 "FALSE" 1 "TRUE" ;
VAL_ 336 HVBatCntctrStat 0 "Open" 1 "Precharging" 2 "Closed" 3 "Precharge_Failed" 4 "Precharge_Inhibited" 7 "SNA" ;
VAL_ 336 HVBatCrnt 0 "SNA" ;
VAL_ 336 HVBatCrntV 0 "Valid" 1 "Not_Valid" ;
VAL_ 336 HVBatIntrlkStat 0 "N_S" 1 "PASS" 2 "FAIL" 3 "INV" ;
VAL_ 336 HVBatIntrlk_InternalStat 0 "N_S" 1 "PASS" 2 "FAIL" 3 "INV" ;
VAL_ 336 HVBatIsolStat 0 "N_S" 1 "PASS" 2 "FAIL" 3 "INV" ;
VAL_ 336 HVBatRdy 0 "FALSE" 1 "TRUE" ;
VAL_ 336 HVBatVlt 4095 "SNA" ;
VAL_ 336 HVBatVltV 0 "Valid" 1 "Not_Valid" ;
VAL_ 336 PwrtrnHV_IsolStat 0 "N_S" 1 "PASS" 2 "FAIL" 3 "INV" ;
VAL_ 544 HVBatCellVltAvg 8191 "SNA" ;
VAL_ 544 HVBatCellVltAvgV 0 "Valid" 1 "Not_Valid" ;
VAL_ 544 HVBatCellVltMax 8191 "SNA" ;
VAL_ 544 HVBatCellVltMaxV 0 "Valid" 1 "Not_Valid" ;
VAL_ 544 HVBatCellVltMin 8191 "SNA" ;
VAL_ 544 HVBatCellVltMinV 0 "Valid" 1 "Not_Valid" ;
VAL_ 851 HVBatFull_Amp_Hr_Capacity 2047 "SNA" ;
VAL_ 851 HVBatFull_Amp_Hr_Capacity_V 0 "Valid" 1 "Not_Valid" ;
VAL_ 851 HVBatMaxChgCurrAlwd_V 0 "Valid" 1 "Not_Valid" ;
VAL_ 852 HVBatCell_Voltage_High_Thrsh 8191 "SNA" ;
VAL_ 852 HVBatCell_Voltage_Low_Thrsh 8191 "SNA" ;
VAL_ 852 HVBatHighTempThrsh 255 "SNA" ;
VAL_ 852 HVBatLowTempThrsh 255 "SNA" ;
VAL_ 1000 HEV_OnRq_BPCM 0 "FALSE" 1 "TRUE" ;
VAL_ 1000 HVBatChargeStat 0 "NOT_READY" 1 "READY" 2 "CAC_CHARGEALLOWCURRENT" 3 "CDC_CHARGEDIS_ALLOWCURRENT" 6 "COMPLETE" 7 "SNA" ;
VAL_ 1000 HVBatCntctrOpnTime 255 "SNA" ;
VAL_ 1000 HVBatSleepTime 255 "SNA" ;
VAL_ 1000 MIL_OnRq_BPCM 0 "FALSE" 1 "TRUE" ;
VAL_ 1000 Prchrgpnltytimer 0 "SNA" ;
VAL_ 337 HVBat_Real_Time_Clock -2147483648 "SNA" ;
VAL_ 337 HVBat_Real_Time_Clock_V 0 "Valid" 1 "Not_Valid" ;
VAL_ 832 DateTmDay 255 "SNA" ;
VAL_ 832 DateTmFormat 0 "NDEF0" 1 "FORMAT_12H" 2 "FORMAT_24H" 3 "FORMAT_0" 4 "FORMAT_1" 5 "FORMAT_2" 6 "FORMAT_3" 7 "SNA" ;
VAL_ 832 DateTmHour 255 "SNA" ;
VAL_ 832 DateTmMinute 255 "SNA" ;
VAL_ 832 DateTmMonth 255 "SNA" ;
VAL_ 832 DateTmSec 255 "SNA" ;
VAL_ 832 DateTmYear 65535 "SNA" ;
VAL_ 499 LFC_Request_Type 0 "No Request" 1 "Brake Torque Request" 2 "Standstill Hold Request" 3 "RHSC_Override" ;
VAL_ 499 RHSC_OpenLoopBraking_Rq 0 "False" 1 "True" ;
VAL_ 499 SDS_Engaged_State 0 "Disengaged" 1 "Engaged_with_Driver" 2 "Engaged_Driverless" 3 "SNA" ;
VAL_ 625 SDS_Engaged_State 0 "Disengaged" 1 "Engaged_with_Driver" 2 "Engaged_Driverless" 3 "SNA" ;
VAL_ 793 CompElecCurrV 0 "Valid" 1 "Not_Valid" ;
VAL_ 793 CompElecPwrV 0 "Valid" 1 "Not_Valid" ;
VAL_ 793 CompFltStat 0 "No_Fault" 1 "Under_Voltage" 2 "Over_Voltage" 3 "Over_Temperature" 4 "Input_Control" 5 "Current_Fault" 6 "Internal_Fault" 7 "Memory_Fault" 8 "Rotor_Lock" 9 "Loss_of_Comm_with_HCP" 10 "Loss_of_Comm_with_ORC" 15 "SNA" ;
VAL_ 793 CompSpd 16383 "SNA" ;
VAL_ 793 CompSpdIncrReq 0 "FALSE" 1 "TRUE" ;
VAL_ 793 CompSpdV 0 "Valid" 1 "Not_Valid" ;
VAL_ 793 CompStat 0 "NormalOperation" 1 "DegradedOperation" 2 "Inoperative" 3 "Reserved1" 4 "Reserved2" 5 "Reserved3" 6 "Reserved4" 15 "SNA" ;
